VERSION "10.9.1"

NS_ :

BS_:

BU_: ADAS_Info AMP CPD DUMMY_DEBUG DUMMY_ECU EASC HUD MHU XGW_Info

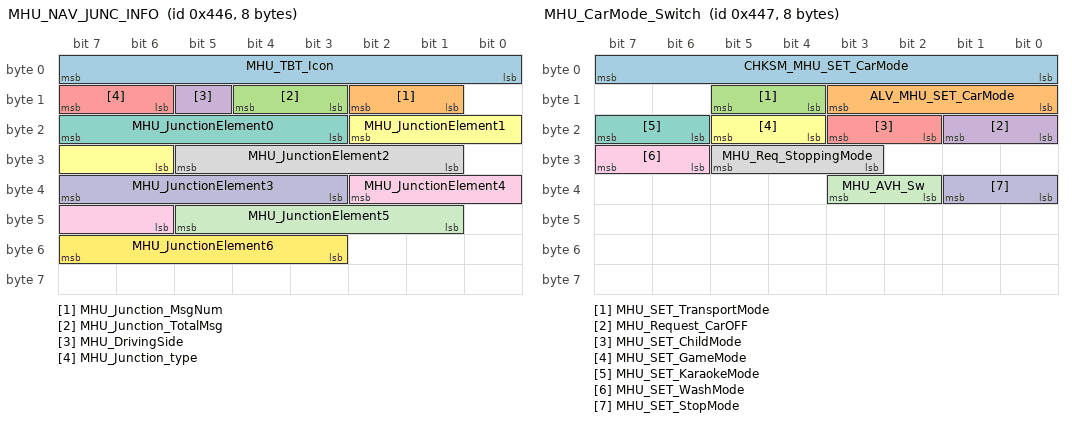
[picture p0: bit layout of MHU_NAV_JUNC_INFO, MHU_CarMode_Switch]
BO_ 1094 MHU_NAV_JUNC_INFO: 8 MHU
  SG_ MHU_TBT_Icon : 7|8@0+ (1,0) [0|255] "-" HUD
  SG_ MHU_Junction_MsgNum : 10|2@0+ (1,0) [0|3] "-" HUD
  SG_ MHU_Junction_TotalMsg : 12|2@0+ (1,0) [0|3] "-" HUD
  SG_ MHU_DrivingSide : 13|1@0+ (1,0) [0|1] "-" HUD
  SG_ MHU_Junction_type : 15|2@0+ (1,0) [0|3] "-" HUD
  SG_ MHU_JunctionElement1 : 18|5@0+ (1,0) [0|31] "-" HUD
  SG_ MHU_JunctionElement0 : 23|5@0+ (1,0) [0|31] "-" HUD
  SG_ MHU_JunctionElement2 : 29|5@0+ (1,0) [0|31] "-" HUD
  SG_ MHU_JunctionElement4 : 34|5@0+ (1,0) [0|31] "-" HUD
  SG_ MHU_JunctionElement3 : 39|5@0+ (1,0) [0|31] "-" HUD
  SG_ MHU_JunctionElement5 : 45|5@0+ (1,0) [0|31] "-" HUD
  SG_ MHU_JunctionElement6 : 55|5@0+ (1,0) [0|31] "-" HUD

BO_ 1095 MHU_CarMode_Switch: 8 MHU
  SG_ CHKSM_MHU_SET_CarMode : 7|8@0+ (1,0) [0|255] "" XGW_Info
  SG_ ALV_MHU_SET_CarMode : 11|4@0+ (1,0) [0|14] "" XGW_Info
  SG_ MHU_SET_TransportMode : 13|2@0+ (1,0) [0|3] "" XGW_Info
  SG_ MHU_Request_CarOFF : 17|2@0+ (1,0) [0|3] "-" XGW_Info
  SG_ MHU_SET_ChildMode : 19|2@0+ (1,0) [0|3] "" XGW_Info
  SG_ MHU_SET_GameMode : 21|2@0+ (1,0) [0|3] "" XGW_Info
  SG_ MHU_SET_KaraokeMode : 23|2@0+ (1,0) [0|3] "" XGW_Info
  SG_ MHU_Req_StoppingMode : 29|3@0+ (1,0) [0|7] "" XGW_Info
  SG_ MHU_SET_WashMode : 31|2@0+ (1,0) [0|3] "" XGW_Info
  SG_ MHU_SET_StopMode : 33|2@0+ (1,0) [0|3] "" XGW_Info
  SG_ MHU_AVH_Sw : 35|2@0+ (1,0) [0|3] "" XGW_Info

BO_ 1096 EDS_Error_FR_B: 8 XGW_Info
  SG_ CHKSM_EDS_Error_FR_B : 7|8@0+ (1,0) [0|255] "" MHU
  SG_ ALV_EDS_Error_FR_B : 11|4@0+ (1,0) [0|14] "" MHU
  SG_ EDS_iDcLnkOvCLimFail_FWD : 16|1@0+ (1,0) [0|1] "" MHU
  SG_ EDS_MotBlockedFault_FWD : 17|1@0+ (1,0) [0|1] "" MHU
  SG_ EDS_RSLErr_FWD : 18|1@0+ (1,0) [0|1] "" MHU
  SG_ EDS_MotTrqLimFault_FWD : 19|1@0+ (1,0) [0|1] "" MHU
  SG_ EDS_VCUChksumFault_FWD : 20|1@0+ (1,0) [0|1] "" MHU
  SG_ EDS_IGBTFault_FWD : 22|1@0+ (1,0) [0|1] "" MHU
  SG_ EDS_CANBusoffFault_FWD : 23|1@0+ (1,0) [0|1] "" MHU
  SG_ EDS_TDrvBoardOvHiWarn_FWD : 24|1@0+ (1,0) [0|1] "" MHU
  SG_ EDS_TIGBTOvHiFault_FWD : 25|1@0+ (1,0) [0|1] "" MHU
  SG_ EDS_TIGBTOvHiWarn_FWD : 26|1@0+ (1,0) [0|1] "" MHU
  SG_ EDS_IOHWABSampFail_FWD : 27|1@0+ (1,0) [0|1] "" MHU
  SG_ EDS_EDSOpenFault_FWD : 28|1@0+ (1,0) [0|1] "" MHU
  SG_ EDS_MotorOpenFault_FWD : 29|1@0+ (1,0) [0|1] "" MHU
  SG_ EDS_EparkSampFail_FWD : 30|1@0+ (1,0) [0|1] "" MHU
  SG_ EDS_EmacBlkdWarn_FWD : 31|1@0+ (1,0) [0|1] "" MHU
  SG_ EDS_VerMatchFailureErr_FWD : 32|1@0+ (1,0) [0|1] "" MHU
  SG_ EDS_DiashCirNoPsblErr_FWD : 33|1@0+ (1,0) [0|1] "" MHU
  SG_ EDS_OperOutdRngErr_FWD : 34|1@0+ (1,0) [0|1] "" MHU
  SG_ EDS_PhaseLossFaultErr_FWD : 35|1@0+ (1,0) [0|1] "" MHU
  SG_ EDS_CPLDFault_FWD : 36|1@0+ (1,0) [0|1] "" MHU
  SG_ EDS_CPLDFaultBaseSpd_FWD : 37|1@0+ (1,0) [0|1] "" MHU
  SG_ EDS_IOHWABNen33Fail_FWD : 38|1@0+ (1,0) [0|1] "" MHU
  SG_ EDS_HvMcuSlightFault_FWD : 39|1@0+ (1,0) [0|1] "" MHU
  SG_ EDS_HvMcuSevFault_FWD : 40|1@0+ (1,0) [0|1] "" MHU
  SG_ EDS_EDSPhaSampHWFault_FWD : 41|1@0+ (1,0) [0|1] "" MHU
  SG_ EDS_IsOvHiErr_FWD : 42|1@0+ (1,0) [0|1] "" MHU
  SG_ EDS_CanRollingCounterErr_FWD : 43|1@0+ (1,0) [0|1] "" MHU
  SG_ EDS_CanTimeoutErr_FWD : 44|1@0+ (1,0) [0|1] "" MHU
  SG_ EDS_CrashFault_FWD : 45|1@0+ (1,0) [0|1] "" MHU
  SG_ EDS_PCFSlightFault_FWD : 46|1@0+ (1,0) [0|1] "" MHU
  SG_ EDS_PCFSerFault_FWD : 47|1@0+ (1,0) [0|1] "" MHU
  SG_ SECCAN_EDS_Error_FR_B : 63|8@0+ (1,0) [0|255] "" MHU

BO_ 1097 EDS_Error_RR_B: 8 XGW_Info
  SG_ CHKSM_EDS_Error_RR_B : 7|8@0+ (1,0) [0|255] "" MHU
  SG_ ALV_EDS_Error_RR_B : 11|4@0+ (1,0) [0|14] "" MHU
  SG_ EDS_iDcLnkOvCLimFail_RWD : 16|1@0+ (1,0) [0|1] "" MHU
  SG_ EDS_MotBlockedFault_RWD : 17|1@0+ (1,0) [0|1] "" MHU
  SG_ EDS_RSLErr_RWD : 18|1@0+ (1,0) [0|1] "" MHU
  SG_ EDS_MotTrqLimFault_RWD : 19|1@0+ (1,0) [0|1] "" MHU
  SG_ EDS_VCUChksumFault_RWD : 20|1@0+ (1,0) [0|1] "" MHU
  SG_ EDS_IGBTFault_RWD : 22|1@0+ (1,0) [0|1] "" MHU
  SG_ EDS_CANBusoffFault_RWD : 23|1@0+ (1,0) [0|1] "" MHU
  SG_ EDS_TDrvBoardOvHiWarn_RWD : 24|1@0+ (1,0) [0|1] "" MHU
  SG_ EDS_TIGBTOvHiFault_RWD : 25|1@0+ (1,0) [0|1] "" MHU
  SG_ EDS_TIGBTOvHiWarn_RWD : 26|1@0+ (1,0) [0|1] "" MHU
  SG_ EDS_IOHWABSampFail_RWD : 27|1@0+ (1,0) [0|1] "" MHU
  SG_ EDS_EDSOpenFault_RWD : 28|1@0+ (1,0) [0|1] "" MHU
  SG_ EDS_MotorOpenFault_RWD : 29|1@0+ (1,0) [0|1] "" MHU
  SG_ EDS_EparkSampFail_RWD : 30|1@0+ (1,0) [0|1] "" MHU
  SG_ EDS_EmacBlkdWarn_RWD : 31|1@0+ (1,0) [0|1] "" MHU
  SG_ EDS_VerMatchFailureErr_RWD : 32|1@0+ (1,0) [0|1] "" MHU
  SG_ EDS_DiashCirNoPsblErr_RWD : 33|1@0+ (1,0) [0|1] "" MHU
  SG_ EDS_OperOutdRngErr_RWD : 34|1@0+ (1,0) [0|1] "" MHU
  SG_ EDS_PhaseLossFaultErr_RWD : 35|1@0+ (1,0) [0|1] "" MHU
  SG_ EDS_CPLDFault_RWD : 36|1@0+ (1,0) [0|1] "" MHU
  SG_ EDS_CPLDFaultBaseSpd_RWD : 37|1@0+ (1,0) [0|1] "" MHU
  SG_ EDS_IOHWABNen33Fail_RWD : 38|1@0+ (1,0) [0|1] "" MHU
  SG_ EDS_HvMcuSlightFault_RWD : 39|1@0+ (1,0) [0|1] "" MHU
  SG_ EDS_HvMcuSevFault_RWD : 40|1@0+ (1,0) [0|1] "" MHU
  SG_ EDS_EDSPhaSampHWFault_RWD : 41|1@0+ (1,0) [0|1] "" MHU
  SG_ EDS_IsOvHiErr_RWD : 42|1@0+ (1,0) [0|1] "" MHU
  SG_ EDS_CanRollingCounterErr_RWD : 43|1@0+ (1,0) [0|1] "" MHU
  SG_ EDS_CanTimeoutErr_RWD : 44|1@0+ (1,0) [0|1] "" MHU
  SG_ EDS_CrashFault_RWD : 45|1@0+ (1,0) [0|1] "" MHU
  SG_ EDS_PCFSlightFault_RWD : 46|1@0+ (1,0) [0|1] "" MHU
  SG_ EDS_PCFSerFault_RWD : 47|1@0+ (1,0) [0|1] "" MHU
  SG_ SECCAN_EDS_Error_RR_B : 63|8@0+ (1,0) [0|255] "" MHU

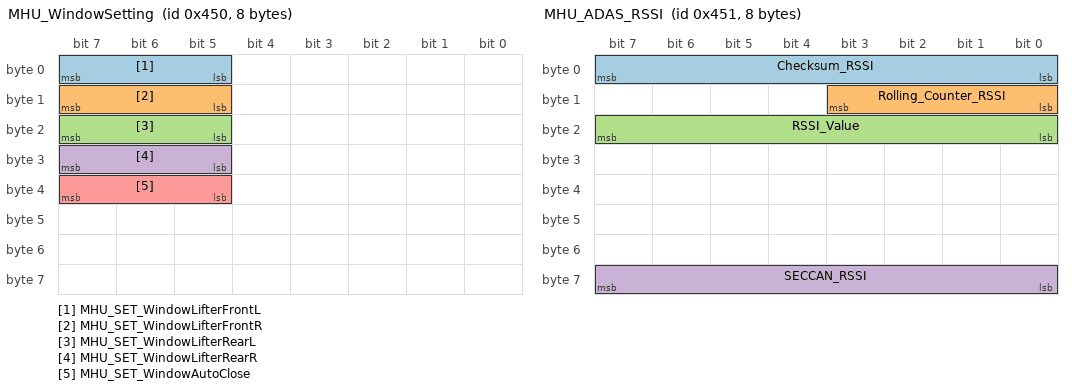
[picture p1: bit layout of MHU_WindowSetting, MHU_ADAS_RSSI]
BO_ 1104 MHU_WindowSetting: 8 MHU
  SG_ MHU_SET_WindowLifterFrontL : 7|3@0+ (1,0) [0|7] "" XGW_Info
  SG_ MHU_SET_WindowLifterFrontR : 15|3@0+ (1,0) [0|7] "" XGW_Info
  SG_ MHU_SET_WindowLifterRearL : 23|3@0+ (1,0) [0|7] "" XGW_Info
  SG_ MHU_SET_WindowLifterRearR : 31|3@0+ (1,0) [0|7] "" XGW_Info
  SG_ MHU_SET_WindowAutoClose : 39|3@0+ (1,0) [0|3] "" XGW_Info

BO_ 1105 MHU_ADAS_RSSI: 8 MHU
  SG_ Checksum_RSSI : 7|8@0+ (1,0) [0|255] "" ADAS_Info
  SG_ Rolling_Counter_RSSI : 11|4@0+ (1,0) [0|14] "" ADAS_Info
  SG_ RSSI_Value : 23|8@0+ (1,0) [0|255] "" ADAS_Info
  SG_ SECCAN_RSSI : 63|8@0+ (1,0) [0|255] "" ADAS_Info

BO_ 1106 MHU_AMP_Ann1_ModeSET: 8 MHU
  SG_ MHU_SET_ANN1_MODE : 7|2@0+ (1,0) [0|3] "" AMP

BO_ 1107 MHU_AMP_Ann1_PromptsSET: 8 MHU
  SG_ MHU_SET_ANN1_PROMPTS_SPEAKER : 7|3@0+ (1,0) [0|6] "" AMP

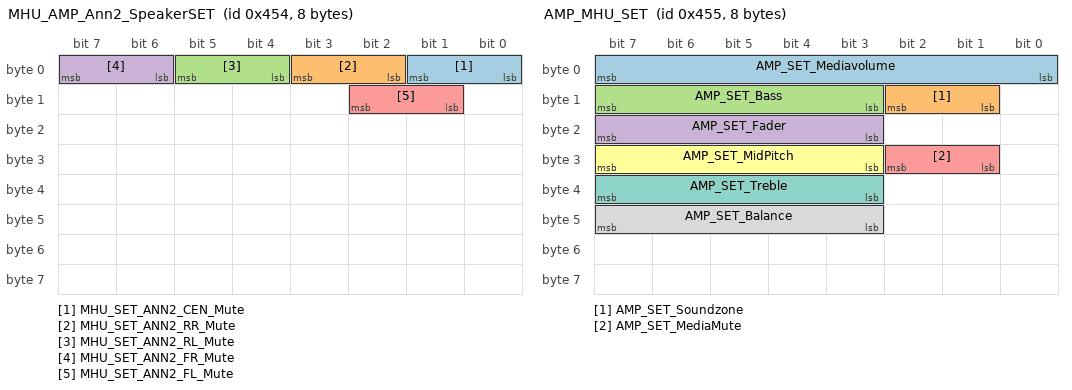
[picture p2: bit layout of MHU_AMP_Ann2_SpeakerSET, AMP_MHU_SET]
BO_ 1108 MHU_AMP_Ann2_SpeakerSET: 8 MHU
  SG_ MHU_SET_ANN2_CEN_Mute : 1|2@0+ (1,0) [0|2] "" AMP
  SG_ MHU_SET_ANN2_RR_Mute : 3|2@0+ (1,0) [0|2] "" AMP
  SG_ MHU_SET_ANN2_RL_Mute : 5|2@0+ (1,0) [0|2] "" AMP
  SG_ MHU_SET_ANN2_FR_Mute : 7|2@0+ (1,0) [0|2] "" AMP
  SG_ MHU_SET_ANN2_FL_Mute : 10|2@0+ (1,0) [0|2] "" AMP

BO_ 1109 AMP_MHU_SET: 8 AMP
  SG_ AMP_SET_Mediavolume : 7|8@0+ (1,0) [0|40] "-" MHU
  SG_ AMP_SET_Soundzone : 10|2@0+ (1,0) [0|3] "-" MHU
  SG_ AMP_SET_Bass : 15|5@0+ (1,-6) [-6|6] "-" MHU
  SG_ AMP_SET_Fader : 23|5@0+ (1,-10) [-10|10] "-" MHU
  SG_ AMP_SET_MediaMute : 26|2@0+ (1,0) [0|3] "-" MHU
  SG_ AMP_SET_MidPitch : 31|5@0+ (1,-6) [-6|6] "-" MHU
  SG_ AMP_SET_Treble : 39|5@0+ (1,-6) [-6|6] "-" MHU
  SG_ AMP_SET_Balance : 47|5@0+ (1,-10) [-10|10] "-" MHU

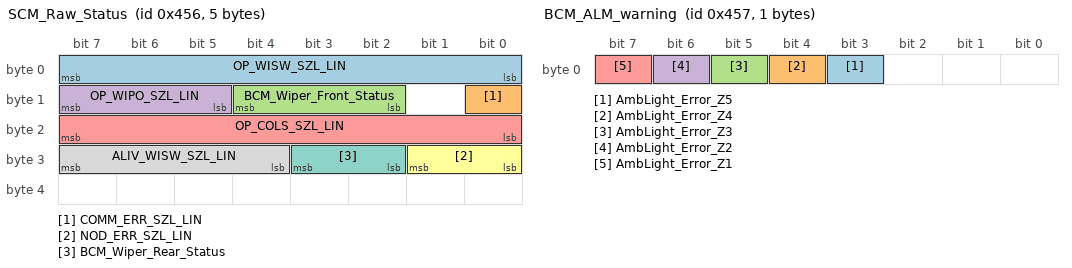
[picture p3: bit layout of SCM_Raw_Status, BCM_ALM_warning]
BO_ 1110 SCM_Raw_Status: 5 XGW_Info
  SG_ OP_WISW_SZL_LIN : 7|8@0+ (1,0) [0|255] "" HUD,MHU
  SG_ COMM_ERR_SZL_LIN : 8|1@0+ (1,0) [0|1] "" HUD,MHU
  SG_ BCM_Wiper_Front_Status : 12|3@0+ (1,0) [0|7] "" HUD,MHU
  SG_ OP_WIPO_SZL_LIN : 15|3@0+ (1,0) [0|7] "-" HUD,MHU
  SG_ OP_COLS_SZL_LIN : 23|8@0+ (1,0) [0|255] "-" HUD,MHU
  SG_ NOD_ERR_SZL_LIN : 25|2@0+ (1,0) [0|3] "" HUD,MHU
  SG_ BCM_Wiper_Rear_Status : 27|2@0+ (1,0) [0|3] "" MHU
  SG_ ALIV_WISW_SZL_LIN : 31|4@0+ (1,0) [0|14] "" HUD,MHU

BO_ 1111 BCM_ALM_warning: 1 XGW_Info
  SG_ AmbLight_Error_Z5 : 3|1@0+ (1,0) [0|1] "-" MHU
  SG_ AmbLight_Error_Z4 : 4|1@0+ (1,0) [0|1] "" MHU
  SG_ AmbLight_Error_Z3 : 5|1@0+ (1,0) [0|1] "-" MHU
  SG_ AmbLight_Error_Z2 : 6|1@0+ (1,0) [0|1] "" MHU
  SG_ AmbLight_Error_Z1 : 7|1@0+ (1,0) [0|1] "" MHU

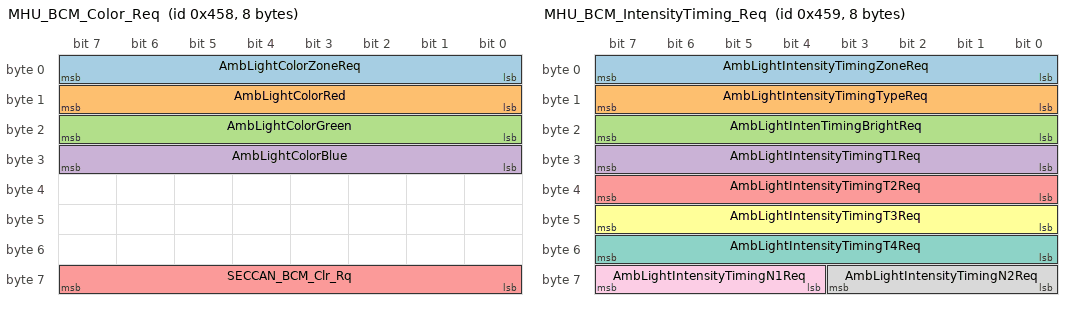
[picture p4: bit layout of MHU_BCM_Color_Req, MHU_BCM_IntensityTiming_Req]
BO_ 1112 MHU_BCM_Color_Req: 8 MHU
  SG_ AmbLightColorZoneReq : 7|8@0+ (1,0) [0|31] "-" XGW_Info
  SG_ AmbLightColorRed : 15|8@0+ (1,0) [0|255] "" XGW_Info
  SG_ AmbLightColorGreen : 23|8@0+ (1,0) [0|255] "-" XGW_Info
  SG_ AmbLightColorBlue : 31|8@0+ (1,0) [0|255] "-" XGW_Info
  SG_ SECCAN_BCM_Clr_Rq : 63|8@0+ (1,0) [0|255] "" XGW_Info

BO_ 1113 MHU_BCM_IntensityTiming_Req: 8 MHU
  SG_ AmbLightIntensityTimingZoneReq : 7|8@0+ (1,0) [0|31] "" XGW_Info
  SG_ AmbLightIntensityTimingTypeReq : 15|8@0+ (1,0) [0|5] "" XGW_Info
  SG_ AmbLightIntenTimingBrightReq : 23|8@0+ (1,0) [0|100] "" XGW_Info
  SG_ AmbLightIntensityTimingT1Req : 31|8@0+ (0.1,0) [0|25.5] "s" XGW_Info
  SG_ AmbLightIntensityTimingT2Req : 39|8@0+ (0.1,0) [0|25.5] "s" XGW_Info
  SG_ AmbLightIntensityTimingT3Req : 47|8@0+ (0.1,0) [0|25.5] "s" XGW_Info
  SG_ AmbLightIntensityTimingT4Req : 55|8@0+ (0.1,0) [0|25.5] "s" XGW_Info
  SG_ AmbLightIntensityTimingN2Req : 59|4@0+ (1,0) [0|15] "-" XGW_Info
  SG_ AmbLightIntensityTimingN1Req : 63|4@0+ (1,0) [0|15] "" XGW_Info

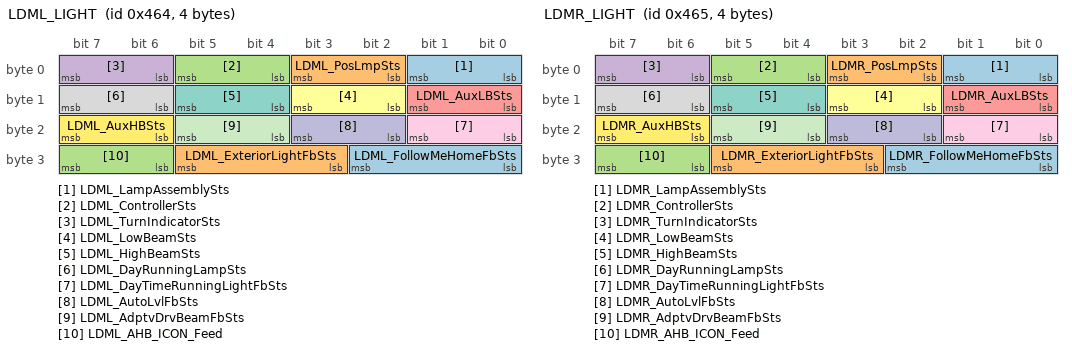
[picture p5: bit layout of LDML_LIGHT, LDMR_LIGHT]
BO_ 1124 LDML_LIGHT: 4 XGW_Info
  SG_ LDML_LampAssemblySts : 1|2@0+ (1,0) [0|3] "-" HUD,MHU
  SG_ LDML_PosLmpSts : 3|2@0+ (1,0) [0|3] "" HUD,MHU
  SG_ LDML_ControllerSts : 5|2@0+ (1,0) [0|3] "" HUD,MHU
  SG_ LDML_TurnIndicatorSts : 7|2@0+ (1,0) [0|3] "" HUD,MHU
  SG_ LDML_AuxLBSts : 9|2@0+ (1,0) [0|3] "-" HUD,MHU
  SG_ LDML_LowBeamSts : 11|2@0+ (1,0) [0|3] "-" HUD,MHU
  SG_ LDML_HighBeamSts : 13|2@0+ (1,0) [0|3] "" HUD,MHU
  SG_ LDML_DayRunningLampSts : 15|2@0+ (1,0) [0|3] "" HUD,MHU
  SG_ LDML_DayTimeRunningLightFbSts : 17|2@0+ (1,0) [0|3] "" HUD,MHU
  SG_ LDML_AutoLvlFbSts : 19|2@0+ (1,0) [0|3] "" HUD,MHU
  SG_ LDML_AdptvDrvBeamFbSts : 21|2@0+ (1,0) [0|3] "-" HUD,MHU
  SG_ LDML_AuxHBSts : 23|2@0+ (1,0) [0|3] "-" HUD,MHU
  SG_ LDML_FollowMeHomeFbSts : 26|3@0+ (1,0) [0|5] "-" HUD,MHU
  SG_ LDML_ExteriorLightFbSts : 29|3@0+ (1,0) [0|4] "-" HUD,MHU
  SG_ LDML_AHB_ICON_Feed : 31|2@0+ (1,0) [0|3] "" HUD,MHU

BO_ 1125 LDMR_LIGHT: 4 XGW_Info
  SG_ LDMR_LampAssemblySts : 1|2@0+ (1,0) [0|3] "" HUD,MHU
  SG_ LDMR_PosLmpSts : 3|2@0+ (1,0) [0|3] "-" HUD,MHU
  SG_ LDMR_ControllerSts : 5|2@0+ (1,0) [0|3] "" HUD,MHU
  SG_ LDMR_TurnIndicatorSts : 7|2@0+ (1,0) [0|3] "-" HUD,MHU
  SG_ LDMR_AuxLBSts : 9|2@0+ (1,0) [0|3] "-" HUD,MHU
  SG_ LDMR_LowBeamSts : 11|2@0+ (1,0) [0|3] "-" HUD,MHU
  SG_ LDMR_HighBeamSts : 13|2@0+ (1,0) [0|3] "" HUD,MHU
  SG_ LDMR_DayRunningLampSts : 15|2@0+ (1,0) [0|3] "" HUD,MHU
  SG_ LDMR_DayTimeRunningLightFbSts : 17|2@0+ (1,0) [0|3] "-" HUD,MHU
  SG_ LDMR_AutoLvlFbSts : 19|2@0+ (1,0) [0|3] "-" HUD,MHU
  SG_ LDMR_AdptvDrvBeamFbSts : 21|2@0+ (1,0) [0|3] "" HUD,MHU
  SG_ LDMR_AuxHBSts : 23|2@0+ (1,0) [0|3] "-" HUD,MHU
  SG_ LDMR_FollowMeHomeFbSts : 26|3@0+ (1,0) [0|5] "" HUD,MHU
  SG_ LDMR_ExteriorLightFbSts : 29|3@0+ (1,0) [0|4] "-" HUD,MHU
  SG_ LDMR_AHB_ICON_Feed : 31|2@0+ (1,0) [0|3] "" HUD,MHU

BO_ 1136 AMP_MHU_Ann1_ModeSET: 8 AMP
  SG_ AMP_SET_ANN1_MODE : 15|2@0+ (1,0) [0|3] "" MHU

BO_ 1137 AMP_MHU_Ann1_PromptsSET: 8 AMP
  SG_ AMP_SET_ANN1_PROMPTS_SPEAKER : 13|3@0+ (1,0) [0|6] "" MHU

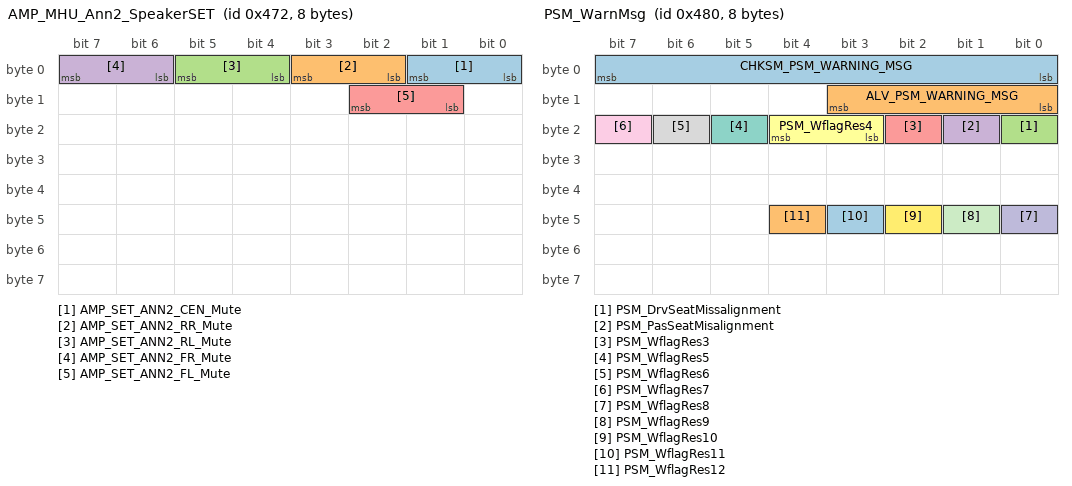
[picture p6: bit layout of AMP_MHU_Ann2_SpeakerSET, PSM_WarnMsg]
BO_ 1138 AMP_MHU_Ann2_SpeakerSET: 8 AMP
  SG_ AMP_SET_ANN2_CEN_Mute : 1|2@0+ (1,0) [0|3] "" MHU
  SG_ AMP_SET_ANN2_RR_Mute : 3|2@0+ (1,0) [0|3] "" MHU
  SG_ AMP_SET_ANN2_RL_Mute : 5|2@0+ (1,0) [0|3] "" MHU
  SG_ AMP_SET_ANN2_FR_Mute : 7|2@0+ (1,0) [0|3] "" MHU
  SG_ AMP_SET_ANN2_FL_Mute : 10|2@0+ (1,0) [0|3] "" MHU

BO_ 1152 PSM_WarnMsg: 8 XGW_Info
  SG_ CHKSM_PSM_WARNING_MSG : 7|8@0+ (1,0) [0|255] "" MHU
  SG_ ALV_PSM_WARNING_MSG : 11|4@0+ (1,0) [0|14] "" MHU
  SG_ PSM_DrvSeatMissalignment : 16|1@0+ (1,0) [0|1] "" MHU
  SG_ PSM_PasSeatMisalignment : 17|1@0+ (1,0) [0|1] "Bit" MHU
  SG_ PSM_WflagRes3 : 18|1@0+ (1,0) [0|1] "Bit" MHU
  SG_ PSM_WflagRes4 : 20|2@0+ (1,0) [0|3] "Bit" MHU
  SG_ PSM_WflagRes5 : 21|1@0+ (1,0) [0|1] "-" MHU
  SG_ PSM_WflagRes6 : 22|1@0+ (1,0) [0|1] "-" MHU
  SG_ PSM_WflagRes7 : 23|1@0+ (1,0) [0|1] "-" MHU
  SG_ PSM_WflagRes8 : 40|1@0+ (1,0) [0|1] "" MHU
  SG_ PSM_WflagRes9 : 41|1@0+ (1,0) [0|1] "" MHU
  SG_ PSM_WflagRes10 : 42|1@0+ (1,0) [0|1] "-" MHU
  SG_ PSM_WflagRes11 : 43|1@0+ (1,0) [0|1] "-" MHU
  SG_ PSM_WflagRes12 : 44|1@0+ (1,0) [0|1] "-" MHU

BO_ 1153 BCM_WarnMsg: 8 XGW_Info
 SG_ CHSKM_BCM_WarnMsg : 7|8@0+ (1,0) [0|255] "" MHU
 SG_ ALV_BCM_WarnMsg : 11|4@0+ (1,0) [0|14] "" MHU
 SG_ BCM_NoValidKey_1 : 12|1@0+ (1,0) [0|1] "" MHU
 SG_ BCM_SSB_defect : 13|1@0+ (1,0) [0|1] "" MHU
 SG_ BCM_WrongGearPosToStart : 14|1@0+ (1,0) [0|1] "" MHU
 SG_ BCM_NoValidKey_2 : 15|1@0+ (1,0) [0|1] "" MHU
 SG_ BCM_PressBrakeToStart : 16|1@0+ (1,0) [0|1] "" MHU
 SG_ BCM_TurnOffPosLightRemindr : 17|1@0+ (1,0) [0|1] "" MHU
 SG_ BCM_KeyFob_LowBattery : 18|1@0+ (1,0) [0|1] "" MHU
 SG_ BCM_StopLightDefect : 19|1@0+ (1,0) [0|1] "" MHU
 SG_ BCM_LowBeamDefect : 20|1@0+ (1,0) [0|1] "" MHU
 SG_ BCM_HighBeamDefect : 21|1@0+ (1,0) [0|1] "" MHU
 SG_ BCM_PositionLightDefect : 22|1@0+ (1,0) [0|1] "" MHU
 SG_ BCM_CHMLS_Defect : 23|1@0+ (1,0) [0|1] "" MHU
 SG_ BCM_LicencePlateLight_Defect : 24|1@0+ (1,0) [0|1] "" MHU
 SG_ BCM_FrontFog_Defect : 25|1@0+ (1,0) [0|1] "" MHU
 SG_ BCM_RearFog_Defect : 26|1@0+ (1,0) [0|1] "" MHU
 SG_ BCM_ReverseLightDefect : 27|1@0+ (1,0) [0|1] "" MHU
 SG_ BCM_RLS_Malfunction : 28|1@0+ (1,0) [0|1] "" MHU
 SG_ BCM_12VBattery_LowLevel : 29|1@0+ (1,0) [0|1] "" MHU
 SG_ BCM_ForgetKeyFOBInCar : 30|1@0+ (1,0) [0|1] "" MHU
 SG_ BCM_12VBattery_Discharging : 31|1@0+ (1,0) [0|1] "" MHU
 SG_ BCM_TurnIndicatorDefect : 32|1@0+ (1,0) [0|1] "" MHU
 SG_ BCM_dTPMS_Malfunc : 33|1@0+ (1,0) [0|1] "" MHU
 SG_ BCM_dTPMS_Malfunc_LostSensor : 34|1@0+ (1,0) [0|1] "" MHU
 SG_ BCM_dTPMS_LowPressure : 35|1@0+ (1,0) [0|1] "" MHU
 SG_ BCM_dTPMS_RapidLeak : 36|1@0+ (1,0) [0|1] "" MHU
 SG_ BCM_dTPMS_HighTemperature : 37|1@0+ (1,0) [0|1] "" MHU
 SG_ BCM_dTPMS_HighPressure : 38|1@0+ (1,0) [0|1] "" MHU
 SG_ BCM_dTPMS_LowBattery : 39|1@0+ (1,0) [0|1] "" MHU
 SG_ BCM_Keyfob_Leftcar : 40|1@0+ (1,0) [0|1] "" MHU
 SG_ BCM_IDB_Brakelight_Malfunction : 41|1@0+ (1,0) [0|1] "" MHU
 SG_ BCM_VCU_Brakelight_Malfunction : 42|1@0+ (1,0) [0|1] "" MHU
 SG_ BCM_ADAS_Turnlight_Malfunction : 43|1@0+ (1,0) [0|1] "" MHU
 SG_ BCM_ADAS_Highbeam_Malfunction : 44|1@0+ (1,0) [0|1] "" MHU
 SG_ BCM_ADAS_LowBeam_Malfunction : 45|1@0+ (1,0) [0|1] "" MHU
 SG_ BCM_MHU_Malfunction : 46|1@0+ (1,0) [0|1] "" MHU
 SG_ BCM_BCM_Malfunction : 47|1@0+ (1,0) [0|1] "" MHU
 SG_ BCM_SCM_Malfunction : 48|1@0+ (1,0) [0|1] "" MHU
 SG_ BCM_CrashSignalDefect : 49|1@0+ (1,0) [0|1] "" MHU
 SG_ BCM_FrontWiperDefect : 51|1@0+ (1,0) [0|1] "" MHU
 SG_ BCM_Rear_RightDoorLockDefect : 52|1@0+ (1,0) [0|1] "" MHU
 SG_ BCM_RearLeftDoorLockDefect : 53|1@0+ (1,0) [0|1] "" MHU
 SG_ BCM_Front_RightDoorLockDefect : 54|1@0+ (1,0) [0|1] "" MHU
 SG_ BCM_FrontLeftDoorLockDefect : 55|1@0+ (1,0) [0|1] "" MHU
 SG_ BCM_LDML_Malfunction : 56|1@0+ (1,0) [0|1] "" MHU
 SG_ BCM_LDMR_Malfunction : 57|1@0+ (1,0) [0|1] "" MHU
 SG_ BCM_RLBL_Malfunction : 58|1@0+ (1,0) [0|1] "" MHU
 SG_ BCM_RLBR_Malfunction : 59|1@0+ (1,0) [0|1] "" MHU
 SG_ BCM_RLT_Malfunction : 60|1@0+ (1,0) [0|1] "" MHU
 SG_ BCM_BCM_POWER_Malfunction : 61|1@0+ (1,0) [0|1] "" MHU
 SG_ BCM_IDB_AutoHazardBlinking_Malf : 62|1@0+ (1,0) [0|1] "" MHU

BO_ 1154 XGW_WarnMsg: 8 XGW_Info
  SG_ CHSKM_XGW_WarnMsg : 7|8@0+ (1,0) [0|255] "" MHU
  SG_ ALV_XGW_WarnMsg : 11|4@0+ (1,0) [0|14] "" MHU
  SG_ XGW_AutoHLLevelingFault : 12|1@0+ (1,0) [0|1] "-" MHU
  SG_ XGW_WasherFluidLvlSw : 13|1@0+ (1,0) [0|1] "-" MHU
  SG_ XGW_Warning_Flag_3 : 14|1@0+ (1,0) [0|1] "-" MHU
  SG_ XGW_Warning_Flag_4 : 15|1@0+ (1,0) [0|1] "-" MHU
  SG_ XGW_Warning_Flag_5 : 16|1@0+ (1,0) [0|1] "-" MHU
  SG_ XGW_Warning_Flag_6 : 17|1@0+ (1,0) [0|1] "-" MHU
  SG_ XGW_Warning_Flag_7 : 18|1@0+ (1,0) [0|1] "-" MHU
  SG_ XGW_Warning_Flag_8 : 19|1@0+ (1,0) [0|1] "-" MHU
  SG_ XGW_Warning_Flag_9 : 20|1@0+ (1,0) [0|1] "-" MHU
  SG_ XGW_Warning_Flag_10 : 21|1@0+ (1,0) [0|1] "-" MHU
  SG_ XGW_Warning_Flag_11 : 22|1@0+ (1,0) [0|1] "-" MHU
  SG_ XGW_Warning_Flag_12 : 23|1@0+ (1,0) [0|1] "-" MHU
  SG_ XGW_Reserved_signal1 : 31|8@0+ (1,0) [0|255] "-" MHU
  SG_ XGW_Reserved_signal2 : 39|8@0+ (1,0) [0|255] "-" MHU
  SG_ XGW_Reserved_signal3 : 47|8@0+ (1,0) [0|255] "-" MHU
  SG_ XGW_Reserved_signal4 : 55|8@0+ (1,0) [0|255] "-" MHU
  SG_ XGW_Reserved_signal5 : 63|8@0+ (1,0) [0|255] "-" MHU

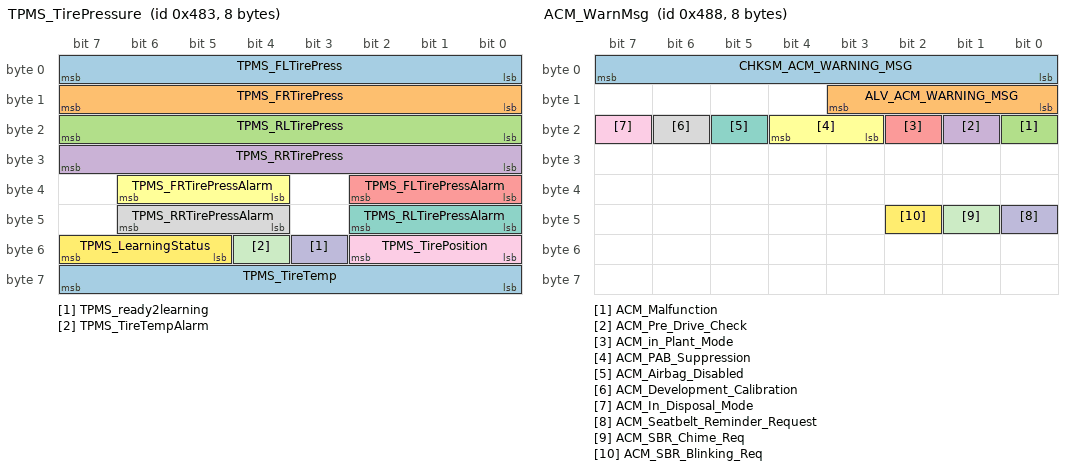
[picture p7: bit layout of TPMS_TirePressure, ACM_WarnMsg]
BO_ 1155 TPMS_TirePressure: 8 XGW_Info
  SG_ TPMS_FLTirePress : 7|8@0+ (1.373,0) [0|350] "kPa" MHU
  SG_ TPMS_FRTirePress : 15|8@0+ (1.373,0) [0|350] "kPa" MHU
  SG_ TPMS_RLTirePress : 23|8@0+ (1.373,0) [0|350] "kPa" MHU
  SG_ TPMS_RRTirePress : 31|8@0+ (1.373,0) [0|350] "kPa" MHU
  SG_ TPMS_FLTirePressAlarm : 34|3@0+ (1,0) [0|7] "" MHU
  SG_ TPMS_FRTirePressAlarm : 38|3@0+ (1,0) [0|7] "-" MHU
  SG_ TPMS_RLTirePressAlarm : 42|3@0+ (1,0) [0|7] "" MHU
  SG_ TPMS_RRTirePressAlarm : 46|3@0+ (1,0) [0|7] "" MHU
  SG_ TPMS_TirePosition : 50|3@0+ (1,0) [0|7] "-" MHU
  SG_ TPMS_ready2learning : 51|1@0+ (1,0) [0|1] "-" MHU
  SG_ TPMS_TireTempAlarm : 52|1@0+ (1,0) [0|1] "-" MHU
  SG_ TPMS_LearningStatus : 55|3@0+ (1,0) [0|7] "-" MHU
  SG_ TPMS_TireTemp : 63|8@0+ (1,-40) [-40|215] "Degree C" MHU

BO_ 1156 APA_FEEDBACK_MHU: 8 ADAS_Info
  SG_ CHKSM_APA_FEEDBACK_MHU : 7|8@0+ (1,0) [0|255] "" MHU
  SG_ ALV_APA_FEEDBACK_MHU : 11|4@0+ (1,0) [0|14] "" MHU
  SG_ APA_ReqInfoDispTxt3 : 19|5@0+ (1,0) [0|31] "-" MHU
  SG_ APA_ParkOutDircnDisReq : 20|1@0+ (1,0) [0|1] "-" MHU
  SG_ APA_ParkOutModeDisReq : 21|1@0+ (1,0) [0|1] "-" MHU
  SG_ APA_MHU_DisplaystartbuttonReq : 23|2@0+ (1,0) [0|3] "-" MHU
  SG_ APA_ReqInfoDispTxt4 : 27|4@0+ (1,0) [0|15] "-" MHU
  SG_ APA_ReqInfoDispTxt2 : 30|3@0+ (1,0) [0|7] "-" MHU
  SG_ APA_ReqInfoDispTxt1 : 34|3@0+ (1,0) [0|7] "-" MHU
  SG_ APA_MHU_Displayparkingtype : 35|1@0+ (1,0) [0|1] "-" MHU
  SG_ APA_ShowAPAFdbck : 37|2@0+ (1,0) [0|3] "-" MHU
  SG_ APA_FuncModeFdbck : 39|2@0+ (1,0) [0|3] "-" MHU
  SG_ APA_MHU_DisplayrecoverbuttonReq : 44|1@0+ (1,0) [0|1] "-" MHU
  SG_ APA_SysSoundIndication : 47|3@0+ (1,0) [0|7] "-" MHU
  SG_ APA_RecommendSlotID : 51|8@0+ (1,0) [0|255] "-" MHU
  SG_ APA_Currentfunction : 54|3@0+ (1,0) [0|7] "-" MHU
  SG_ APA_MHU_Status : 59|3@0+ (1,0) [0|7] "-" MHU

BO_ 1160 ACM_WarnMsg: 8 XGW_Info
  SG_ CHKSM_ACM_WARNING_MSG : 7|8@0+ (1,0) [0|255] "" MHU
  SG_ ALV_ACM_WARNING_MSG : 11|4@0+ (1,0) [0|14] "" MHU
  SG_ ACM_Malfunction : 16|1@0+ (1,0) [0|1] "" MHU
  SG_ ACM_Pre_Drive_Check : 17|1@0+ (1,0) [0|1] "Bit" MHU
  SG_ ACM_in_Plant_Mode : 18|1@0+ (1,0) [0|1] "Bit" MHU
  SG_ ACM_PAB_Suppression : 20|2@0+ (1,0) [0|3] "Bit" MHU
  SG_ ACM_Airbag_Disabled : 21|1@0+ (1,0) [0|1] "-" MHU
  SG_ ACM_Development_Calibration : 22|1@0+ (1,0) [0|1] "-" MHU
  SG_ ACM_In_Disposal_Mode : 23|1@0+ (1,0) [0|1] "" MHU
  SG_ ACM_Seatbelt_Reminder_Request : 40|1@0+ (1,0) [0|1] "-" MHU
  SG_ ACM_SBR_Chime_Req : 41|1@0+ (1,0) [0|1] "" MHU
  SG_ ACM_SBR_Blinking_Req : 42|1@0+ (1,0) [0|1] "" MHU

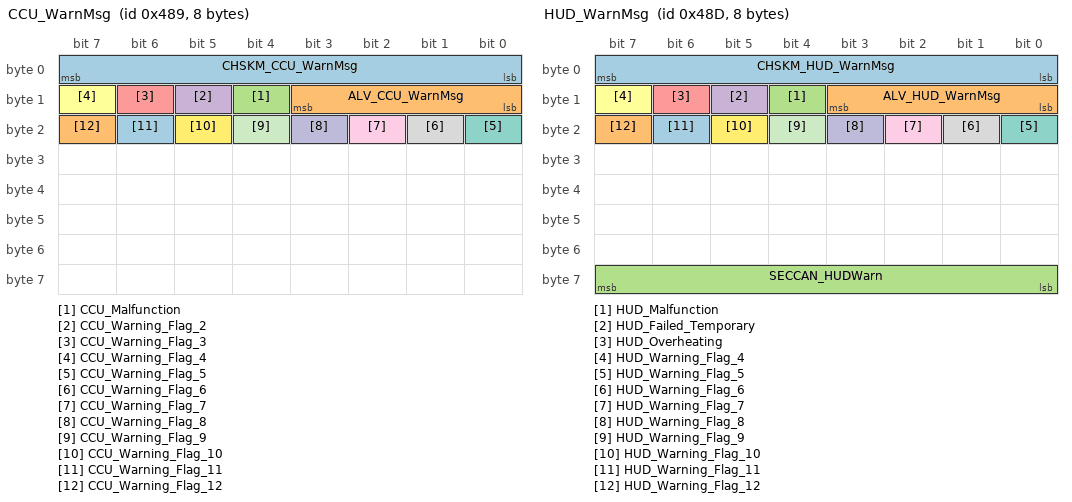
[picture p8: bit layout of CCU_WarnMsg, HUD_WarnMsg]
BO_ 1161 CCU_WarnMsg: 8 XGW_Info
  SG_ CHSKM_CCU_WarnMsg : 7|8@0+ (1,0) [0|255] "" MHU
  SG_ ALV_CCU_WarnMsg : 11|4@0+ (1,0) [0|14] "" MHU
  SG_ CCU_Malfunction : 12|1@0+ (1,0) [0|1] "" MHU
  SG_ CCU_Warning_Flag_2 : 13|1@0+ (1,0) [0|1] "-" MHU
  SG_ CCU_Warning_Flag_3 : 14|1@0+ (1,0) [0|1] "" MHU
  SG_ CCU_Warning_Flag_4 : 15|1@0+ (1,0) [0|1] "-" MHU
  SG_ CCU_Warning_Flag_5 : 16|1@0+ (1,0) [0|1] "-" MHU
  SG_ CCU_Warning_Flag_6 : 17|1@0+ (1,0) [0|1] "-" MHU
  SG_ CCU_Warning_Flag_7 : 18|1@0+ (1,0) [0|1] "-" MHU
  SG_ CCU_Warning_Flag_8 : 19|1@0+ (1,0) [0|1] "" MHU
  SG_ CCU_Warning_Flag_9 : 20|1@0+ (1,0) [0|1] "" MHU
  SG_ CCU_Warning_Flag_10 : 21|1@0+ (1,0) [0|1] "" MHU
  SG_ CCU_Warning_Flag_11 : 22|1@0+ (1,0) [0|1] "" MHU
  SG_ CCU_Warning_Flag_12 : 23|1@0+ (1,0) [0|1] "" MHU

BO_ 1165 HUD_WarnMsg: 8 HUD
  SG_ CHSKM_HUD_WarnMsg : 7|8@0+ (1,0) [0|255] "" MHU
  SG_ ALV_HUD_WarnMsg : 11|4@0+ (1,0) [0|14] "" MHU
  SG_ HUD_Malfunction : 12|1@0+ (1,0) [0|1] "-" MHU
  SG_ HUD_Failed_Temporary : 13|1@0+ (1,0) [0|1] "-" MHU
  SG_ HUD_Overheating : 14|1@0+ (1,0) [0|1] "-" MHU
  SG_ HUD_Warning_Flag_4 : 15|1@0+ (1,0) [0|1] "-" MHU
  SG_ HUD_Warning_Flag_5 : 16|1@0+ (1,0) [0|1] "-" MHU
  SG_ HUD_Warning_Flag_6 : 17|1@0+ (1,0) [0|1] "-" MHU
  SG_ HUD_Warning_Flag_7 : 18|1@0+ (1,0) [0|1] "-" MHU
  SG_ HUD_Warning_Flag_8 : 19|1@0+ (1,0) [0|1] "-" MHU
  SG_ HUD_Warning_Flag_9 : 20|1@0+ (1,0) [0|1] "-" MHU
  SG_ HUD_Warning_Flag_10 : 21|1@0+ (1,0) [0|1] "-" MHU
  SG_ HUD_Warning_Flag_11 : 22|1@0+ (1,0) [0|1] "-" MHU
  SG_ HUD_Warning_Flag_12 : 23|1@0+ (1,0) [0|1] "-" MHU
  SG_ SECCAN_HUDWarn : 63|8@0+ (1,0) [0|255] "" MHU

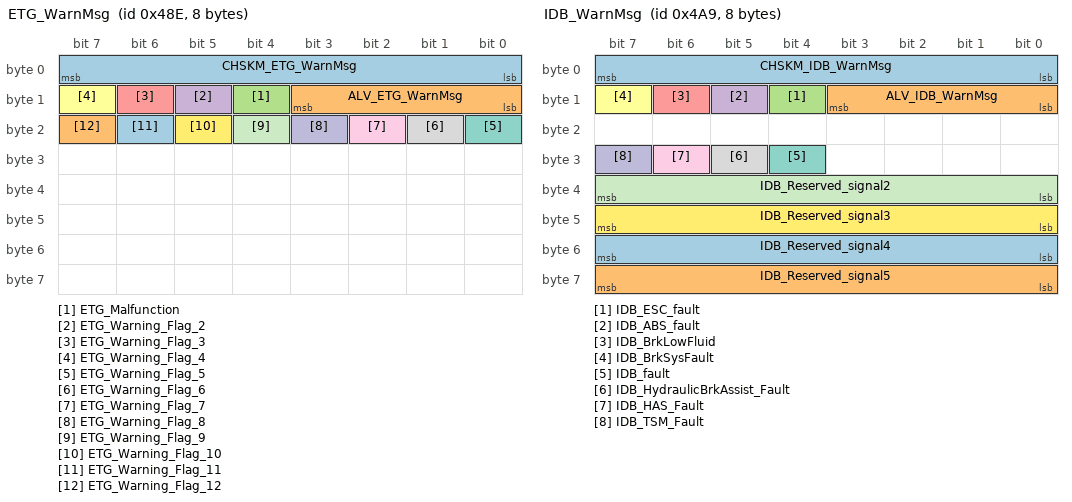
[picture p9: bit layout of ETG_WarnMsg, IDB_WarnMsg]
BO_ 1166 ETG_WarnMsg: 8 XGW_Info
  SG_ CHSKM_ETG_WarnMsg : 7|8@0+ (1,0) [0|255] "" MHU
  SG_ ALV_ETG_WarnMsg : 11|4@0+ (1,0) [0|14] "" MHU
  SG_ ETG_Malfunction : 12|1@0+ (1,0) [0|1] "-" MHU
  SG_ ETG_Warning_Flag_2 : 13|1@0+ (1,0) [0|1] "-" MHU
  SG_ ETG_Warning_Flag_3 : 14|1@0+ (1,0) [0|1] "" MHU
  SG_ ETG_Warning_Flag_4 : 15|1@0+ (1,0) [0|1] "" MHU
  SG_ ETG_Warning_Flag_5 : 16|1@0+ (1,0) [0|1] "-" MHU
  SG_ ETG_Warning_Flag_6 : 17|1@0+ (1,0) [0|1] "-" MHU
  SG_ ETG_Warning_Flag_7 : 18|1@0+ (1,0) [0|1] "-" MHU
  SG_ ETG_Warning_Flag_8 : 19|1@0+ (1,0) [0|1] "" MHU
  SG_ ETG_Warning_Flag_9 : 20|1@0+ (1,0) [0|1] "" MHU
  SG_ ETG_Warning_Flag_10 : 21|1@0+ (1,0) [0|1] "" MHU
  SG_ ETG_Warning_Flag_11 : 22|1@0+ (1,0) [0|1] "-" MHU
  SG_ ETG_Warning_Flag_12 : 23|1@0+ (1,0) [0|1] "" MHU

BO_ 1168 GS_WarnMsg: 8 XGW_Info
  SG_ CHSKM_GS_WarnMsg : 7|8@0+ (1,0) [0|255] "" MHU
  SG_ ALV_GS_WarnMsg : 11|4@0+ (1,0) [0|14] "" MHU
  SG_ GS_Warning_Flag_1 : 12|1@0+ (1,0) [0|1] "" MHU
  SG_ GS_Warning_Flag_2 : 13|1@0+ (1,0) [0|1] "" MHU
  SG_ GS_Warning_Flag_3 : 14|1@0+ (1,0) [0|1] "-" MHU
  SG_ GS_Warning_Flag_4 : 15|1@0+ (1,0) [0|1] "-" MHU
  SG_ GS_Warning_Flag_5 : 16|1@0+ (1,0) [0|1] "" MHU
  SG_ GS_Warning_Flag_6 : 17|1@0+ (1,0) [0|1] "-" MHU
  SG_ GS_Warning_Flag_7 : 18|1@0+ (1,0) [0|1] "" MHU
  SG_ GS_Warning_Flag_8 : 19|1@0+ (1,0) [0|1] "" MHU
  SG_ GS_Warning_Flag_9 : 20|1@0+ (1,0) [0|1] "-" MHU
  SG_ GS_Warning_Flag_10 : 21|1@0+ (1,0) [0|1] "-" MHU
  SG_ GS_Warning_Flag_11 : 22|1@0+ (1,0) [0|1] "" MHU
  SG_ GS_Warning_Flag_12 : 23|1@0+ (1,0) [0|1] "" MHU
  SG_ GS_Reserved_signal1 : 31|8@0+ (1,0) [0|255] "-" MHU
  SG_ GS_Reserved_signal2 : 39|8@0+ (1,0) [0|255] "" MHU
  SG_ GS_Reserved_signal3 : 47|8@0+ (1,0) [0|255] "" MHU
  SG_ GS_Reserved_signal4 : 55|8@0+ (1,0) [0|255] "-" MHU
  SG_ GS_Reserved_signal5 : 63|8@0+ (1,0) [0|255] "" MHU

BO_ 1171 BMS_WarnMsg: 8 XGW_Info
  SG_ CHSKM_BMS_WarnMsg : 7|8@0+ (1,0) [0|255] "" HUD,MHU
  SG_ ALV_BMS_WarnMsg : 11|4@0+ (1,0) [0|14] "" HUD,MHU
  SG_ BMS_PackTempSts : 13|2@0+ (1,0) [0|3] "" MHU
  SG_ BMS_ThermalRunaway : 14|1@0+ (1,0) [0|1] "" HUD,MHU
  SG_ BMS_BatteryReplacement : 15|1@0+ (1,0) [0|1] "" MHU
  SG_ BMS_Warning_PowerDegrade : 16|1@0+ (1,0) [0|1] "" MHU
  SG_ BMS_Warning_DeltaSoC : 17|1@0+ (1,0) [0|1] "" MHU
  SG_ BMS_Warning_HVILSts : 18|1@0+ (1,0) [0|1] "" MHU
  SG_ BMS_Warning_Isolation : 19|1@0+ (1,0) [0|1] "" MHU
  SG_ BMS_Warning_CoolantLeakage : 20|1@0+ (1,0) [0|1] "" MHU
  SG_ BMS_MalfunctionSts : 21|1@0+ (1,0) [0|1] "" MHU
  SG_ BMS_LowBattery : 23|2@0+ (1,0) [0|3] "" HUD,MHU
  SG_ BMS_Warning_DeltaTemperature : 31|8@0+ (1,0) [0|255] "" MHU
  SG_ BMS_Warning_BDUTemperatureSts : 39|8@0+ (1,0) [0|255] "" MHU
  SG_ BMS_Warning_Contactor_Aging : 47|1@0+ (1,0) [0|1] "" MHU
  SG_ BMS_Reserved_signal4 : 55|8@0+ (1,0) [0|255] "" MHU
  SG_ BMS_Reserved_signal5 : 63|8@0+ (1,0) [0|255] "" MHU

BO_ 1178 EDS_R_WarnMsg: 8 XGW_Info
  SG_ CHSKM_EDS_R_WarnMsg : 7|8@0+ (1,0) [0|255] "" MHU
  SG_ ALV_EDS_R_WarnMsg : 11|4@0+ (1,0) [0|14] "" MHU
  SG_ EDS_R_Error_1 : 12|1@0+ (1,0) [0|1] "-" MHU
  SG_ EDS_R_Error_2 : 13|1@0+ (1,0) [0|1] "-" MHU
  SG_ EDS_R_Error_3 : 14|1@0+ (1,0) [0|1] "-" MHU
  SG_ EDS_R_Error_4 : 15|1@0+ (1,0) [0|1] "-" MHU
  SG_ EDS_R_Error_5 : 16|1@0+ (1,0) [0|1] "-" MHU
  SG_ EDS_R_Error_6 : 17|1@0+ (1,0) [0|1] "-" MHU
  SG_ EDS_R_Error_7 : 18|1@0+ (1,0) [0|1] "-" MHU
  SG_ EDS_R_Error_8 : 19|1@0+ (1,0) [0|1] "-" MHU
  SG_ EDS_R_Error_9 : 20|1@0+ (1,0) [0|1] "-" MHU
  SG_ EDS_R_Error_10 : 21|1@0+ (1,0) [0|1] "-" MHU
  SG_ EDS_R_Error_11 : 22|1@0+ (1,0) [0|1] "-" MHU
  SG_ EDS_R_Error_12 : 23|1@0+ (1,0) [0|1] "-" MHU
  SG_ EDS_R_Error_13 : 24|1@0+ (1,0) [0|1] "-" MHU
  SG_ EDS_R_Error_14 : 25|1@0+ (1,0) [0|1] "-" MHU
  SG_ EDS_R_Error_15 : 26|1@0+ (1,0) [0|1] "-" MHU
  SG_ EDS_R_Error_16 : 27|1@0+ (1,0) [0|1] "-" MHU
  SG_ EDS_R_Error_17 : 28|1@0+ (1,0) [0|1] "-" MHU
  SG_ EDS_R_Error_18 : 29|1@0+ (1,0) [0|1] "-" MHU
  SG_ EDS_R_Error_19 : 30|1@0+ (1,0) [0|1] "-" MHU
  SG_ EDS_R_Error_20 : 31|1@0+ (1,0) [0|1] "-" MHU
  SG_ EDS_R_Error_21 : 32|1@0+ (1,0) [0|1] "-" MHU
  SG_ EDS_R_Error_22 : 33|1@0+ (1,0) [0|1] "-" MHU
  SG_ EDS_R_Error_23 : 34|1@0+ (1,0) [0|1] "-" MHU
  SG_ EDS_R_Error_24 : 35|1@0+ (1,0) [0|1] "-" MHU
  SG_ EDS_R_Error_25 : 36|1@0+ (1,0) [0|1] "-" MHU
  SG_ EDS_R_Error_26 : 37|1@0+ (1,0) [0|1] "-" MHU
  SG_ EDS_R_Error_27 : 38|1@0+ (1,0) [0|1] "-" MHU
  SG_ EDS_R_Error_28 : 39|1@0+ (1,0) [0|1] "-" MHU
  SG_ EDS_R_Error_29 : 40|1@0+ (1,0) [0|1] "-" MHU
  SG_ EDS_R_Error_30 : 41|1@0+ (1,0) [0|1] "-" MHU
  SG_ EDS_R_Error_31 : 42|1@0+ (1,0) [0|1] "-" MHU
  SG_ EDS_R_Error_32 : 43|1@0+ (1,0) [0|1] "-" MHU
  SG_ EDS_R_Error_33 : 44|1@0+ (1,0) [0|1] "-" MHU
  SG_ EDS_R_Error_34 : 45|1@0+ (1,0) [0|1] "-" MHU
  SG_ EDS_R_Error_35 : 46|1@0+ (1,0) [0|1] "-" MHU
  SG_ EDS_R_Error_36 : 47|1@0+ (1,0) [0|1] "-" MHU
  SG_ EDS_R_Error_37 : 48|1@0+ (1,0) [0|1] "-" MHU
  SG_ EDS_R_Error_38 : 49|1@0+ (1,0) [0|1] "-" MHU
  SG_ EDS_R_Error_39 : 50|1@0+ (1,0) [0|1] "-" MHU
  SG_ EDS_R_Error_40 : 51|1@0+ (1,0) [0|1] "-" MHU
  SG_ EDS_R_Error_41 : 52|1@0+ (1,0) [0|1] "-" MHU
  SG_ EDS_R_Error_42 : 53|1@0+ (1,0) [0|1] "-" MHU
  SG_ EDS_R_Error_43 : 54|1@0+ (1,0) [0|1] "-" MHU
  SG_ EDS_R_Error_44 : 55|1@0+ (1,0) [0|1] "-" MHU
  SG_ EDS_R_Error_45 : 56|1@0+ (1,0) [0|1] "-" MHU
  SG_ EDS_R_Error_46 : 57|1@0+ (1,0) [0|1] "-" MHU
  SG_ EDS_R_Error_47 : 58|1@0+ (1,0) [0|1] "-" MHU
  SG_ EDS_R_Error_48 : 59|1@0+ (1,0) [0|1] "-" MHU
  SG_ EDS_R_Error_49 : 60|1@0+ (1,0) [0|1] "-" MHU
  SG_ EDS_R_Error_50 : 61|1@0+ (1,0) [0|1] "-" MHU
  SG_ EDS_R_Error_51 : 62|1@0+ (1,0) [0|1] "-" MHU
  SG_ EDS_R_Error_52 : 63|1@0+ (1,0) [0|1] "-" MHU

BO_ 1179 EDS_F_WarnMsg: 8 XGW_Info
  SG_ CHSKM_EDS_F_WarnMsg : 7|8@0+ (1,0) [0|255] "" MHU
  SG_ ALV_EDS_F_WarnMsg : 11|4@0+ (1,0) [0|14] "" MHU
  SG_ EDS_F_Error_1 : 12|1@0+ (1,0) [0|1] "-" MHU
  SG_ EDS_F_Error_2 : 13|1@0+ (1,0) [0|1] "-" MHU
  SG_ EDS_F_Error_3 : 14|1@0+ (1,0) [0|1] "-" MHU
  SG_ EDS_F_Error_4 : 15|1@0+ (1,0) [0|1] "-" MHU
  SG_ EDS_F_Error_5 : 16|1@0+ (1,0) [0|1] "-" MHU
  SG_ EDS_F_Error_6 : 17|1@0+ (1,0) [0|1] "-" MHU
  SG_ EDS_F_Error_7 : 18|1@0+ (1,0) [0|1] "-" MHU
  SG_ EDS_F_Error_8 : 19|1@0+ (1,0) [0|1] "-" MHU
  SG_ EDS_F_Error_9 : 20|1@0+ (1,0) [0|1] "-" MHU
  SG_ EDS_F_Error_10 : 21|1@0+ (1,0) [0|1] "-" MHU
  SG_ EDS_F_Error_11 : 22|1@0+ (1,0) [0|1] "-" MHU
  SG_ EDS_F_Error_12 : 23|1@0+ (1,0) [0|1] "-" MHU
  SG_ EDS_F_Error_13 : 24|1@0+ (1,0) [0|1] "-" MHU
  SG_ EDS_F_Error_14 : 25|1@0+ (1,0) [0|1] "-" MHU
  SG_ EDS_F_Error_15 : 26|1@0+ (1,0) [0|1] "-" MHU
  SG_ EDS_F_Error_16 : 27|1@0+ (1,0) [0|1] "-" MHU
  SG_ EDS_F_Error_17 : 28|1@0+ (1,0) [0|1] "-" MHU
  SG_ EDS_F_Error_18 : 29|1@0+ (1,0) [0|1] "-" MHU
  SG_ EDS_F_Error_19 : 30|1@0+ (1,0) [0|1] "-" MHU
  SG_ EDS_F_Error_20 : 31|1@0+ (1,0) [0|1] "-" MHU
  SG_ EDS_F_Error_21 : 32|1@0+ (1,0) [0|1] "-" MHU
  SG_ EDS_F_Error_22 : 33|1@0+ (1,0) [0|1] "-" MHU
  SG_ EDS_F_Error_23 : 34|1@0+ (1,0) [0|1] "-" MHU
  SG_ EDS_F_Error_24 : 35|1@0+ (1,0) [0|1] "-" MHU
  SG_ EDS_F_Error_25 : 36|1@0+ (1,0) [0|1] "-" MHU
  SG_ EDS_F_Error_26 : 37|1@0+ (1,0) [0|1] "-" MHU
  SG_ EDS_F_Error_27 : 38|1@0+ (1,0) [0|1] "-" MHU
  SG_ EDS_F_Error_28 : 39|1@0+ (1,0) [0|1] "-" MHU
  SG_ EDS_F_Error_29 : 40|1@0+ (1,0) [0|1] "-" MHU
  SG_ EDS_F_Error_30 : 41|1@0+ (1,0) [0|1] "-" MHU
  SG_ EDS_F_Error_31 : 42|1@0+ (1,0) [0|1] "-" MHU
  SG_ EDS_F_Error_32 : 43|1@0+ (1,0) [0|1] "-" MHU
  SG_ EDS_F_Error_33 : 44|1@0+ (1,0) [0|1] "-" MHU
  SG_ EDS_F_Error_34 : 45|1@0+ (1,0) [0|1] "-" MHU
  SG_ EDS_F_Error_35 : 46|1@0+ (1,0) [0|1] "-" MHU
  SG_ EDS_F_Error_36 : 47|1@0+ (1,0) [0|1] "-" MHU
  SG_ EDS_F_Error_37 : 48|1@0+ (1,0) [0|1] "-" MHU
  SG_ EDS_F_Error_38 : 49|1@0+ (1,0) [0|1] "-" MHU
  SG_ EDS_F_Error_39 : 50|1@0+ (1,0) [0|1] "-" MHU
  SG_ EDS_F_Error_40 : 51|1@0+ (1,0) [0|1] "-" MHU
  SG_ EDS_F_Error_41 : 52|1@0+ (1,0) [0|1] "-" MHU
  SG_ EDS_F_Error_42 : 53|1@0+ (1,0) [0|1] "-" MHU
  SG_ EDS_F_Error_43 : 54|1@0+ (1,0) [0|1] "-" MHU
  SG_ EDS_F_Error_44 : 55|1@0+ (1,0) [0|1] "-" MHU
  SG_ EDS_F_Error_45 : 56|1@0+ (1,0) [0|1] "-" MHU
  SG_ EDS_F_Error_46 : 57|1@0+ (1,0) [0|1] "-" MHU
  SG_ EDS_F_Error_47 : 58|1@0+ (1,0) [0|1] "-" MHU
  SG_ EDS_F_Error_48 : 59|1@0+ (1,0) [0|1] "-" MHU
  SG_ EDS_F_Error_49 : 60|1@0+ (1,0) [0|1] "-" MHU
  SG_ EDS_F_Error_50 : 61|1@0+ (1,0) [0|1] "-" MHU
  SG_ EDS_F_Error_51 : 62|1@0+ (1,0) [0|1] "-" MHU
  SG_ EDS_F_Error_52 : 63|1@0+ (1,0) [0|1] "-" MHU

BO_ 1191 RCU_WarnMsg: 8 XGW_Info
  SG_ CHSKM_RCU_WarnMsg : 7|8@0+ (1,0) [0|255] "" MHU
  SG_ ALV_RCU_WarnMsg : 11|4@0+ (1,0) [0|14] "" MHU
  SG_ RCU_DAA_NoOpDoorOpen : 12|1@0+ (1,0) [0|1] "" MHU
  SG_ RCU_EHandBrk_fault : 13|1@0+ (1,0) [0|1] "" MHU
  SG_ RCU_EOL_NotDone : 14|1@0+ (1,0) [0|1] "" MHU
  SG_ RCU_ECD_RWU_active : 15|1@0+ (1,0) [0|1] "" MHU
  SG_ RCU_ParkOnSteepInclination : 16|1@0+ (1,0) [0|1] "" MHU
  SG_ RCU_BrkForceNotEnough : 17|1@0+ (1,0) [0|1] "" MHU
  SG_ RCU_ReleaseEPB_Wo_PressBrk : 20|1@0+ (1,0) [0|1] "" MHU
  SG_ RCU_ParkBrkApplied : 21|1@0+ (1,0) [0|1] "" MHU
  SG_ RCU_Swch_Mafnc : 27|1@0+ (1,0) [0|1] "" MHU
  SG_ RCU_DAA_NoOpBeltUnbuckled : 28|1@0+ (1,0) [0|1] "" MHU
  SG_ RCU_RollerBenchMode : 29|1@0+ (1,0) [0|1] "" MHU
  SG_ RCU_EPB_ParkLampState : 31|2@0+ (1,0) [0|3] "" MHU
  SG_ RCU_EPB_WarnLampState : 34|2@0+ (1,0) [0|3] "" MHU
  SG_ RCU_WflagRes36 : 36|1@0+ (1,0) [0|1] "" MHU
  SG_ RCU_WflagRes37 : 37|1@0+ (1,0) [0|1] "" MHU
  SG_ RCU_WflagRes38 : 38|1@0+ (1,0) [0|1] "" MHU
  SG_ RCU_WflagRes39 : 39|1@0+ (1,0) [0|1] "" MHU
  SG_ RCU_WflagRes40 : 40|1@0+ (1,0) [0|1] "" MHU
  SG_ RCU_WflagRes41 : 41|1@0+ (1,0) [0|1] "" MHU
  SG_ RCU_WflagRes42 : 42|1@0+ (1,0) [0|1] "" MHU
  SG_ RCU_WflagRes43 : 43|1@0+ (1,0) [0|1] "" MHU
  SG_ RCU_WflagRes44 : 44|1@0+ (1,0) [0|1] "" MHU
  SG_ RCU_WflagRes45 : 45|1@0+ (1,0) [0|1] "" MHU
  SG_ RCU_WflagRes46 : 46|1@0+ (1,0) [0|1] "" MHU
  SG_ RCU_WflagRes47 : 47|1@0+ (1,0) [0|1] "" MHU
  SG_ RCU_Reserved_signal1 : 55|8@0+ (1,0) [0|255] "" MHU

BO_ 1192 EPS_WarnMsg: 8 XGW_Info
  SG_ CHSKM_EPS_WarnMsg : 7|8@0+ (1,0) [0|255] "" MHU
  SG_ ALV_EPS_WarnMsg : 11|4@0+ (1,0) [0|14] "" MHU
  SG_ EPS_Malfunction : 12|1@0+ (1,0) [0|1] "-" MHU
  SG_ EPS_Reduced : 13|1@0+ (1,0) [0|1] "-" MHU
  SG_ EPS_Overheat : 14|1@0+ (1,0) [0|1] "" MHU
  SG_ EPS_NotReady : 15|1@0+ (1,0) [0|1] "-" MHU
  SG_ EPS_Warning_Flag_5 : 16|1@0+ (1,0) [0|1] "-" MHU
  SG_ EPS_Warning_Flag_6 : 17|1@0+ (1,0) [0|1] "" MHU
  SG_ EPS_Warning_Flag_7 : 18|1@0+ (1,0) [0|1] "" MHU
  SG_ EPS_Warning_Flag_8 : 19|1@0+ (1,0) [0|1] "-" MHU
  SG_ EPS_Warning_Flag_9 : 20|1@0+ (1,0) [0|1] "-" MHU
  SG_ EPS_Warning_Flag_10 : 21|1@0+ (1,0) [0|1] "" MHU
  SG_ EPS_Warning_Flag_11 : 22|1@0+ (1,0) [0|1] "" MHU
  SG_ EPS_Warning_Flag_12 : 23|1@0+ (1,0) [0|1] "-" MHU
  SG_ EPS_Reserved_signal1 : 31|8@0+ (1,0) [0|255] "" MHU
  SG_ EPS_Reserved_signal2 : 39|8@0+ (1,0) [0|255] "" MHU
  SG_ EPS_Reserved_signal3 : 47|8@0+ (1,0) [0|255] "-" MHU
  SG_ EPS_Reserved_signal4 : 55|8@0+ (1,0) [0|255] "" MHU
  SG_ EPS_Reserved_signal5 : 63|8@0+ (1,0) [0|255] "" MHU

BO_ 1193 IDB_WarnMsg: 8 XGW_Info
  SG_ CHSKM_IDB_WarnMsg : 7|8@0+ (1,0) [0|255] "" MHU
  SG_ ALV_IDB_WarnMsg : 11|4@0+ (1,0) [0|14] "" MHU
  SG_ IDB_ESC_fault : 12|1@0+ (1,0) [0|1] "-" MHU
  SG_ IDB_ABS_fault : 13|1@0+ (1,0) [0|1] "" MHU
  SG_ IDB_BrkLowFluid : 14|1@0+ (1,0) [0|1] "" MHU
  SG_ IDB_BrkSysFault : 15|1@0+ (1,0) [0|1] "-" MHU
  SG_ IDB_fault : 28|1@0+ (1,0) [0|1] "" MHU
  SG_ IDB_HydraulicBrkAssist_Fault : 29|1@0+ (1,0) [0|1] "-" MHU
  SG_ IDB_HAS_Fault : 30|1@0+ (1,0) [0|1] "" MHU
  SG_ IDB_TSM_Fault : 31|1@0+ (1,0) [0|1] "" MHU
  SG_ IDB_Reserved_signal2 : 39|8@0+ (1,0) [0|255] "-" MHU
  SG_ IDB_Reserved_signal3 : 47|8@0+ (1,0) [0|255] "-" MHU
  SG_ IDB_Reserved_signal4 : 55|8@0+ (1,0) [0|255] "-" MHU
  SG_ IDB_Reserved_signal5 : 63|8@0+ (1,0) [0|255] "" MHU

BO_ 1196 VCU_WarnMsg: 8 XGW_Info
  SG_ CHSKM_VCU_WarnMsg : 7|8@0+ (1,0) [0|255] "" MHU
  SG_ ALV_VCU_WarnMsg : 11|4@0+ (1,0) [0|14] "" MHU
  SG_ VCU_GearPOnlyAtStationaryAlert : 12|1@0+ (1,0) [0|1] "" MHU
  SG_ VCU_GearP_NotPossibleAlert : 13|1@0+ (1,0) [0|1] "" MHU
  SG_ VCU_PressBrakeToEngageGear : 14|1@0+ (1,0) [0|1] "" MHU
  SG_ VCU_CantChangeGear : 15|1@0+ (1,0) [0|1] "" MHU
  SG_ VCU_GearMalfunction : 16|1@0+ (1,0) [0|1] "" MHU
  SG_ VCU_RangeAlert : 17|1@0+ (1,0) [0|1] "" MHU
  SG_ VCU_HVSystemReduced : 18|1@0+ (1,0) [0|1] "" MHU
  SG_ VCU_FrontEDSReduced : 19|1@0+ (1,0) [0|1] "" MHU
  SG_ VCU_FrontEDS_Malfunc : 20|1@0+ (1,0) [0|1] "" MHU
  SG_ VCU_RearEDSReduced : 21|1@0+ (1,0) [0|1] "" MHU
  SG_ VCU_RearEDS_Malfunc : 22|1@0+ (1,0) [0|1] "" MHU
  SG_ VCU_CoolingSystem_Malfunc : 23|1@0+ (1,0) [0|1] "" MHU
  SG_ VCU_NeutralRequest : 24|1@0+ (1,0) [0|1] "" MHU
  SG_ VCU_SoftShutdown : 25|1@0+ (1,0) [0|1] "" MHU
  SG_ VCU_EmergencyShutdown : 26|1@0+ (1,0) [0|1] "" MHU
  SG_ VCU_ChgPortDoorSys_Malfunc : 27|1@0+ (1,0) [0|1] "" MHU
  SG_ VCU_Gearchange_NotPossible : 28|1@0+ (1,0) [0|1] "" MHU
  SG_ VCU_12v_Warning : 29|1@0+ (1,0) [0|1] "" MHU
  SG_ VCU_WflagRes19 : 30|1@0+ (1,0) [0|1] "" MHU
  SG_ VCU_WflagRes20 : 31|1@0+ (1,0) [0|1] "" MHU
  SG_ VCU_WflagRes21 : 32|1@0+ (1,0) [0|1] "" MHU
  SG_ VCU_WflagRes22 : 33|1@0+ (1,0) [0|1] "" MHU
  SG_ VCU_WflagRes23 : 34|1@0+ (1,0) [0|1] "" MHU
  SG_ VCU_WflagRes24 : 35|1@0+ (1,0) [0|1] "" MHU
  SG_ VCU_WflagRes25 : 36|1@0+ (1,0) [0|1] "" MHU
  SG_ VCU_WflagRes26 : 37|1@0+ (1,0) [0|1] "" MHU
  SG_ VCU_WflagRes27 : 38|1@0+ (1,0) [0|1] "" MHU
  SG_ VCU_SuperFastCharge_longer : 39|1@0+ (1,0) [0|1] "" MHU
  SG_ VCU_Reserved_signal1 : 47|8@0+ (1,0) [0|255] "" MHU
  SG_ VCU_Reserved_signal2 : 55|8@0+ (1,0) [0|255] "" MHU
  SG_ VCU_Reserved_signal3 : 63|8@0+ (1,0) [0|255] "" MHU

BO_ 1198 EASC_WarnMsg: 8 EASC
  SG_ CHSKM_EASC_WarnMsg : 7|8@0+ (1,0) [0|255] "" MHU
  SG_ ALV_EASC_WarnMsg : 11|4@0+ (1,0) [0|14] "" MHU
  SG_ EASC_Warning_Flag_1 : 12|1@0+ (1,0) [0|1] "-" MHU
  SG_ EASC_Warning_Flag_2 : 13|1@0+ (1,0) [0|1] "-" MHU
  SG_ EASC_Warning_Flag_3 : 14|1@0+ (1,0) [0|1] "-" MHU
  SG_ EASC_Warning_Flag_4 : 15|1@0+ (1,0) [0|1] "-" MHU
  SG_ EASC_Warning_Flag_5 : 16|1@0+ (1,0) [0|1] "-" MHU
  SG_ EASC_Warning_Flag_6 : 17|1@0+ (1,0) [0|1] "-" MHU
  SG_ EASC_Warning_Flag_7 : 18|1@0+ (1,0) [0|1] "-" MHU
  SG_ EASC_Warning_Flag_8 : 19|1@0+ (1,0) [0|1] "-" MHU
  SG_ EASC_Warning_Flag_9 : 20|1@0+ (1,0) [0|1] "-" MHU
  SG_ EASC_Warning_Flag_10 : 21|1@0+ (1,0) [0|1] "-" MHU
  SG_ EASC_Warning_Flag_11 : 22|1@0+ (1,0) [0|1] "-" MHU
  SG_ EASC_Warning_Flag_12 : 23|1@0+ (1,0) [0|1] "-" MHU
  SG_ EASC_Reserved_signal1 : 31|8@0+ (1,0) [0|255] "-" MHU
  SG_ EASC_Reserved_signal2 : 39|8@0+ (1,0) [0|255] "-" MHU
  SG_ EASC_Reserved_signal3 : 47|8@0+ (1,0) [0|255] "-" MHU
  SG_ EASC_Reserved_signal4 : 55|8@0+ (1,0) [0|255] "-" MHU
  SG_ EASC_Reserved_signal5 : 63|8@0+ (1,0) [0|255] "-" MHU

BO_ 1199 CPD_WarnMsg: 8 CPD
  SG_ CHSKM_CPD_WarnMsg : 7|8@0+ (1,0) [0|255] "" MHU
  SG_ ALV_CPD_WarnMsg : 11|4@0+ (1,0) [0|14] "" MHU
  SG_ CPD_Malfunction : 12|1@0+ (1,0) [0|1] "" MHU
  SG_ CPD_SensorFault : 14|2@0+ (1,0) [0|3] "" MHU
  SG_ CPD_Warning_Flag_4 : 15|1@0+ (1,0) [0|1] "" MHU
  SG_ CPD_Warning_Flag_5 : 16|1@0+ (1,0) [0|1] "" MHU
  SG_ CPD_Warning_Flag_6 : 17|1@0+ (1,0) [0|1] "" MHU
  SG_ CPD_Warning_Flag_7 : 18|1@0+ (1,0) [0|1] "" MHU
  SG_ CPD_Warning_Flag_8 : 19|1@0+ (1,0) [0|1] "" MHU
  SG_ CPD_Warning_Flag_9 : 20|1@0+ (1,0) [0|1] "" MHU
  SG_ CPD_Warning_Flag_10 : 21|1@0+ (1,0) [0|1] "" MHU
  SG_ CPD_Warning_Flag_11 : 22|1@0+ (1,0) [0|1] "" MHU
  SG_ CPD_Warning_Flag_12 : 23|1@0+ (1,0) [0|1] "" MHU
  SG_ CPD_Reserved_signal1 : 31|8@0+ (1,0) [0|255] "" MHU
  SG_ CPD_Reserved_signal2 : 39|8@0+ (1,0) [0|255] "" MHU
  SG_ CPD_Reserved_signal3 : 47|8@0+ (1,0) [0|255] "" MHU
  SG_ CPD_Reserved_signal4 : 55|8@0+ (1,0) [0|255] "" MHU
  SG_ CPD_Reserved_signal5 : 63|8@0+ (1,0) [0|255] "" MHU

BA_DEF_ BO_  "GenMsgSendType" ENUM "Cyclic","NotUsed","NotUsed","NotUsed","NotUsed","NotUsed","NotUsed","IfActive","NoMsgSendType","NotUsed";
BA_DEF_ BO_  "GenMsgILSupport" ENUM "No","Yes";
BA_DEF_ BO_  "DiagResponse" ENUM "No","Yes";
BA_DEF_ BO_  "DiagRequest" ENUM "No","Yes";
BA_DEF_ BO_  "NmAsrMessage" ENUM "No","Yes";
BA_DEF_ BO_  "DiagState" ENUM "No","Yes";
BA_DEF_ BO_  "DiagUudtResponse" ENUM "False","True";
BA_DEF_ BO_  "GenMsgStartDelayTime" INT 0 65535;
BA_DEF_ BO_  "GenMsgDelayTime" INT 0 0;
BA_DEF_ BO_  "GenMsgNrOfRepetition" INT 0 0;
BA_DEF_ BO_  "GenMsgCycleTimeFast" INT 0 0;
BA_DEF_ BO_  "GenMsgCycleTime" INT 0 0;
BA_DEF_ SG_  "GenSigSendType" ENUM "Cyclic","OnWrite","OnWriteWithRepetition","OnChange","OnChangeWithRepetition","IfActive","IfActiveWithRepetition","NoSigSendType","NotUsed","NotUsed","NotUsed","NotUsed","NotUsed";
BA_DEF_ SG_  "InvalidValue" STRING;
BA_DEF_ SG_  "GenSigStartValue" INT 0 0;
BA_DEF_ SG_  "GenSigTimeoutTime_ALL" INT 0 65535;
BA_DEF_DEF_  "DiagRequest" "No";
BA_DEF_DEF_  "DiagResponse" "No";
BA_DEF_DEF_  "DiagState" "No";
BA_DEF_DEF_  "DiagUudtResponse" "False";
BA_DEF_DEF_  "GenMsgCycleTime" 0;
BA_DEF_DEF_  "GenMsgCycleTimeFast" 0;
BA_DEF_DEF_  "GenMsgDelayTime" 0;
BA_DEF_DEF_  "GenMsgILSupport" "Yes";
BA_DEF_DEF_  "GenMsgNrOfRepetition" 0;
BA_DEF_DEF_  "GenMsgSendType" "NoMsgSendType";
BA_DEF_DEF_  "GenMsgStartDelayTime" 0;
BA_DEF_DEF_  "GenSigSendType" "Cyclic";
BA_DEF_DEF_  "GenSigStartValue" 0;
BA_DEF_DEF_  "GenSigTimeoutTime_ALL" 0;
BA_DEF_DEF_  "NmAsrMessage" "No";
BA_ "GenMsgCycleTime" BO_ 1095 200;
BA_ "GenMsgSendType" BO_ 1095 0;
BA_ "GenMsgCycleTime" BO_ 1096 100;
BA_ "GenMsgSendType" BO_ 1096 0;
BA_ "GenMsgCycleTime" BO_ 1097 100;
BA_ "GenMsgSendType" BO_ 1097 0;
BA_ "GenMsgCycleTimeFast" BO_ 1104 100;
BA_ "GenMsgNrOfRepetition" BO_ 1104 3;
BA_ "GenMsgCycleTime" BO_ 1105 100;
BA_ "GenMsgSendType" BO_ 1105 0;
BA_ "GenMsgCycleTime" BO_ 1106 100;
BA_ "GenMsgSendType" BO_ 1106 0;
BA_ "GenMsgCycleTime" BO_ 1107 100;
BA_ "GenMsgSendType" BO_ 1107 0;
BA_ "GenMsgCycleTime" BO_ 1108 100;
BA_ "GenMsgSendType" BO_ 1108 0;
BA_ "GenMsgCycleTime" BO_ 1109 100;
BA_ "GenMsgSendType" BO_ 1109 0;
BA_ "GenMsgCycleTimeFast" BO_ 1112 100;
BA_ "GenMsgNrOfRepetition" BO_ 1112 3;
BA_ "GenMsgCycleTimeFast" BO_ 1113 100;
BA_ "GenMsgNrOfRepetition" BO_ 1113 3;
BA_ "GenMsgCycleTime" BO_ 1124 50;
BA_ "GenMsgSendType" BO_ 1124 0;
BA_ "GenMsgCycleTime" BO_ 1125 50;
BA_ "GenMsgSendType" BO_ 1125 0;
BA_ "GenMsgCycleTime" BO_ 1136 100;
BA_ "GenMsgSendType" BO_ 1136 0;
BA_ "GenMsgCycleTime" BO_ 1137 100;
BA_ "GenMsgSendType" BO_ 1137 0;
BA_ "GenMsgCycleTime" BO_ 1138 100;
BA_ "GenMsgSendType" BO_ 1138 0;
BA_ "GenMsgCycleTime" BO_ 1152 1000;
BA_ "GenMsgCycleTimeFast" BO_ 1152 100;
BA_ "GenMsgNrOfRepetition" BO_ 1152 2;
BA_ "GenMsgSendType" BO_ 1152 0;
BA_ "GenMsgCycleTime" BO_ 1153 1000;
BA_ "GenMsgCycleTimeFast" BO_ 1153 100;
BA_ "GenMsgDelayTime" BO_ 1153 25;
BA_ "GenMsgNrOfRepetition" BO_ 1153 2;
BA_ "GenMsgSendType" BO_ 1153 0;
BA_ "GenMsgCycleTime" BO_ 1154 1000;
BA_ "GenMsgCycleTimeFast" BO_ 1154 100;
BA_ "GenMsgNrOfRepetition" BO_ 1154 2;
BA_ "GenMsgSendType" BO_ 1154 0;
BA_ "GenMsgCycleTime" BO_ 1155 50;
BA_ "GenMsgSendType" BO_ 1155 0;
BA_ "GenMsgCycleTime" BO_ 1156 50;
BA_ "GenMsgSendType" BO_ 1156 0;
BA_ "GenMsgCycleTime" BO_ 1160 1000;
BA_ "GenMsgCycleTimeFast" BO_ 1160 100;
BA_ "GenMsgNrOfRepetition" BO_ 1160 2;
BA_ "GenMsgSendType" BO_ 1160 0;
BA_ "GenMsgCycleTime" BO_ 1161 1000;
BA_ "GenMsgCycleTimeFast" BO_ 1161 100;
BA_ "GenMsgNrOfRepetition" BO_ 1161 2;
BA_ "GenMsgSendType" BO_ 1161 0;
BA_ "GenMsgCycleTime" BO_ 1165 1000;
BA_ "GenMsgCycleTimeFast" BO_ 1165 100;
BA_ "GenMsgNrOfRepetition" BO_ 1165 2;
BA_ "GenMsgSendType" BO_ 1165 0;
BA_ "GenMsgCycleTime" BO_ 1166 100;
BA_ "GenMsgSendType" BO_ 1166 0;
BA_ "GenMsgCycleTime" BO_ 1168 1000;
BA_ "GenMsgCycleTimeFast" BO_ 1168 100;
BA_ "GenMsgNrOfRepetition" BO_ 1168 2;
BA_ "GenMsgSendType" BO_ 1168 0;
BA_ "GenMsgCycleTime" BO_ 1171 1000;
BA_ "GenMsgCycleTimeFast" BO_ 1171 100;
BA_ "GenMsgILSupport" BO_ 1171 0;
BA_ "GenMsgNrOfRepetition" BO_ 1171 2;
BA_ "GenMsgSendType" BO_ 1171 0;
BA_ "GenMsgCycleTime" BO_ 1178 1000;
BA_ "GenMsgCycleTimeFast" BO_ 1178 100;
BA_ "GenMsgNrOfRepetition" BO_ 1178 2;
BA_ "GenMsgSendType" BO_ 1178 0;
BA_ "GenMsgCycleTime" BO_ 1179 1000;
BA_ "GenMsgCycleTimeFast" BO_ 1179 100;
BA_ "GenMsgNrOfRepetition" BO_ 1179 2;
BA_ "GenMsgSendType" BO_ 1179 0;
BA_ "GenMsgCycleTime" BO_ 1191 1000;
BA_ "GenMsgCycleTimeFast" BO_ 1191 100;
BA_ "GenMsgNrOfRepetition" BO_ 1191 2;
BA_ "GenMsgSendType" BO_ 1191 0;
BA_ "GenMsgCycleTime" BO_ 1192 1000;
BA_ "GenMsgCycleTimeFast" BO_ 1192 100;
BA_ "GenMsgNrOfRepetition" BO_ 1192 2;
BA_ "GenMsgSendType" BO_ 1192 0;
BA_ "GenMsgCycleTime" BO_ 1193 1000;
BA_ "GenMsgCycleTimeFast" BO_ 1193 100;
BA_ "GenMsgNrOfRepetition" BO_ 1193 2;
BA_ "GenMsgSendType" BO_ 1193 0;
BA_ "GenMsgCycleTime" BO_ 1196 1000;
BA_ "GenMsgCycleTimeFast" BO_ 1196 100;
BA_ "GenMsgNrOfRepetition" BO_ 1196 2;
BA_ "GenMsgSendType" BO_ 1196 0;
BA_ "GenMsgCycleTime" BO_ 1198 1000;
BA_ "GenMsgCycleTimeFast" BO_ 1198 100;
BA_ "GenMsgNrOfRepetition" BO_ 1198 2;
BA_ "GenMsgSendType" BO_ 1198 0;
BA_ "GenMsgCycleTime" BO_ 1199 1000;
BA_ "GenMsgCycleTimeFast" BO_ 1199 100;
BA_ "GenMsgNrOfRepetition" BO_ 1199 2;
BA_ "GenMsgSendType" BO_ 1199 0;
BA_ "GenSigSendType" SG_ 1094 MHU_TBT_Icon 1;
BA_ "GenSigSendType" SG_ 1094 MHU_Junction_MsgNum 1;
BA_ "GenSigStartValue" SG_ 1094 MHU_Junction_MsgNum 1;
BA_ "GenSigSendType" SG_ 1094 MHU_Junction_TotalMsg 1;
BA_ "GenSigStartValue" SG_ 1094 MHU_Junction_TotalMsg 1;
BA_ "GenSigSendType" SG_ 1094 MHU_DrivingSide 1;
BA_ "GenSigSendType" SG_ 1094 MHU_Junction_type 1;
BA_ "InvalidValue" SG_ 1094 MHU_Junction_type "3h";
BA_ "GenSigSendType" SG_ 1094 MHU_JunctionElement1 1;
BA_ "InvalidValue" SG_ 1094 MHU_JunctionElement1 "1Fh";
BA_ "GenSigSendType" SG_ 1094 MHU_JunctionElement0 1;
BA_ "InvalidValue" SG_ 1094 MHU_JunctionElement0 "1Fh";
BA_ "GenSigSendType" SG_ 1094 MHU_JunctionElement2 1;
BA_ "InvalidValue" SG_ 1094 MHU_JunctionElement2 "1Fh";
BA_ "GenSigSendType" SG_ 1094 MHU_JunctionElement4 1;
BA_ "InvalidValue" SG_ 1094 MHU_JunctionElement4 "1Fh";
BA_ "GenSigSendType" SG_ 1094 MHU_JunctionElement3 1;
BA_ "InvalidValue" SG_ 1094 MHU_JunctionElement3 "1Fh";
BA_ "GenSigSendType" SG_ 1094 MHU_JunctionElement5 1;
BA_ "InvalidValue" SG_ 1094 MHU_JunctionElement5 "1Fh";
BA_ "GenSigSendType" SG_ 1094 MHU_JunctionElement6 1;
BA_ "InvalidValue" SG_ 1094 MHU_JunctionElement6 "1Fh";
BA_ "GenSigTimeoutTime_ALL" SG_ 1095 CHKSM_MHU_SET_CarMode 1000;
BA_ "InvalidValue" SG_ 1095 CHKSM_MHU_SET_CarMode "null";
BA_ "GenSigTimeoutTime_ALL" SG_ 1095 ALV_MHU_SET_CarMode 1000;
BA_ "InvalidValue" SG_ 1095 ALV_MHU_SET_CarMode "Fh";
BA_ "GenSigTimeoutTime_ALL" SG_ 1095 MHU_SET_TransportMode 1000;
BA_ "InvalidValue" SG_ 1095 MHU_SET_TransportMode "3h";
BA_ "GenSigTimeoutTime_ALL" SG_ 1095 MHU_Request_CarOFF 1000;
BA_ "InvalidValue" SG_ 1095 MHU_Request_CarOFF "3h";
BA_ "GenSigTimeoutTime_ALL" SG_ 1095 MHU_SET_ChildMode 1000;
BA_ "InvalidValue" SG_ 1095 MHU_SET_ChildMode "null";
BA_ "InvalidValue" SG_ 1095 MHU_SET_ChildMode "3h";
BA_ "GenSigTimeoutTime_ALL" SG_ 1095 MHU_SET_GameMode 1000;
BA_ "InvalidValue" SG_ 1095 MHU_SET_GameMode "null";
BA_ "InvalidValue" SG_ 1095 MHU_SET_GameMode "3h";
BA_ "GenSigTimeoutTime_ALL" SG_ 1095 MHU_SET_KaraokeMode 1000;
BA_ "InvalidValue" SG_ 1095 MHU_SET_KaraokeMode "3h";
BA_ "InvalidValue" SG_ 1095 MHU_SET_KaraokeMode "null";
BA_ "GenSigStartValue" SG_ 1095 MHU_Req_StoppingMode 4;
BA_ "GenSigTimeoutTime_ALL" SG_ 1095 MHU_Req_StoppingMode 1000;
BA_ "InvalidValue" SG_ 1095 MHU_Req_StoppingMode "7h";
BA_ "GenSigTimeoutTime_ALL" SG_ 1095 MHU_SET_WashMode 1000;
BA_ "InvalidValue" SG_ 1095 MHU_SET_WashMode "3h";
BA_ "InvalidValue" SG_ 1095 MHU_SET_WashMode "null";
BA_ "GenSigTimeoutTime_ALL" SG_ 1095 MHU_SET_StopMode 1000;
BA_ "InvalidValue" SG_ 1095 MHU_SET_StopMode "3h";
BA_ "GenSigTimeoutTime_ALL" SG_ 1095 MHU_AVH_Sw 1000;
BA_ "InvalidValue" SG_ 1095 MHU_AVH_Sw "3h";
BA_ "GenSigTimeoutTime_ALL" SG_ 1096 CHKSM_EDS_Error_FR_B 500;
BA_ "InvalidValue" SG_ 1096 CHKSM_EDS_Error_FR_B "null";
BA_ "GenSigTimeoutTime_ALL" SG_ 1096 ALV_EDS_Error_FR_B 500;
BA_ "InvalidValue" SG_ 1096 ALV_EDS_Error_FR_B "Fh";
BA_ "GenSigTimeoutTime_ALL" SG_ 1096 EDS_iDcLnkOvCLimFail_FWD 500;
BA_ "InvalidValue" SG_ 1096 EDS_iDcLnkOvCLimFail_FWD "null";
BA_ "GenSigTimeoutTime_ALL" SG_ 1096 EDS_MotBlockedFault_FWD 500;
BA_ "InvalidValue" SG_ 1096 EDS_MotBlockedFault_FWD "null";
BA_ "GenSigTimeoutTime_ALL" SG_ 1096 EDS_RSLErr_FWD 500;
BA_ "InvalidValue" SG_ 1096 EDS_RSLErr_FWD "null";
BA_ "GenSigTimeoutTime_ALL" SG_ 1096 EDS_MotTrqLimFault_FWD 500;
BA_ "InvalidValue" SG_ 1096 EDS_MotTrqLimFault_FWD "null";
BA_ "GenSigTimeoutTime_ALL" SG_ 1096 EDS_VCUChksumFault_FWD 500;
BA_ "InvalidValue" SG_ 1096 EDS_VCUChksumFault_FWD "null";
BA_ "GenSigTimeoutTime_ALL" SG_ 1096 EDS_IGBTFault_FWD 500;
BA_ "InvalidValue" SG_ 1096 EDS_IGBTFault_FWD "null";
BA_ "GenSigTimeoutTime_ALL" SG_ 1096 EDS_CANBusoffFault_FWD 500;
BA_ "InvalidValue" SG_ 1096 EDS_CANBusoffFault_FWD "null";
BA_ "GenSigTimeoutTime_ALL" SG_ 1096 EDS_TDrvBoardOvHiWarn_FWD 500;
BA_ "InvalidValue" SG_ 1096 EDS_TDrvBoardOvHiWarn_FWD "null";
BA_ "GenSigTimeoutTime_ALL" SG_ 1096 EDS_TIGBTOvHiFault_FWD 500;
BA_ "InvalidValue" SG_ 1096 EDS_TIGBTOvHiFault_FWD "null";
BA_ "GenSigTimeoutTime_ALL" SG_ 1096 EDS_TIGBTOvHiWarn_FWD 500;
BA_ "InvalidValue" SG_ 1096 EDS_TIGBTOvHiWarn_FWD "null";
BA_ "GenSigTimeoutTime_ALL" SG_ 1096 EDS_IOHWABSampFail_FWD 500;
BA_ "InvalidValue" SG_ 1096 EDS_IOHWABSampFail_FWD "null";
BA_ "GenSigTimeoutTime_ALL" SG_ 1096 EDS_EDSOpenFault_FWD 500;
BA_ "InvalidValue" SG_ 1096 EDS_EDSOpenFault_FWD "null";
BA_ "GenSigTimeoutTime_ALL" SG_ 1096 EDS_MotorOpenFault_FWD 500;
BA_ "InvalidValue" SG_ 1096 EDS_MotorOpenFault_FWD "null";
BA_ "GenSigTimeoutTime_ALL" SG_ 1096 EDS_EparkSampFail_FWD 500;
BA_ "InvalidValue" SG_ 1096 EDS_EparkSampFail_FWD "null";
BA_ "GenSigTimeoutTime_ALL" SG_ 1096 EDS_EmacBlkdWarn_FWD 500;
BA_ "InvalidValue" SG_ 1096 EDS_EmacBlkdWarn_FWD "null";
BA_ "GenSigTimeoutTime_ALL" SG_ 1096 EDS_VerMatchFailureErr_FWD 500;
BA_ "InvalidValue" SG_ 1096 EDS_VerMatchFailureErr_FWD "null";
BA_ "GenSigTimeoutTime_ALL" SG_ 1096 EDS_DiashCirNoPsblErr_FWD 500;
BA_ "InvalidValue" SG_ 1096 EDS_DiashCirNoPsblErr_FWD "null";
BA_ "GenSigTimeoutTime_ALL" SG_ 1096 EDS_OperOutdRngErr_FWD 500;
BA_ "InvalidValue" SG_ 1096 EDS_OperOutdRngErr_FWD "null";
BA_ "GenSigTimeoutTime_ALL" SG_ 1096 EDS_PhaseLossFaultErr_FWD 500;
BA_ "InvalidValue" SG_ 1096 EDS_PhaseLossFaultErr_FWD "null";
BA_ "GenSigTimeoutTime_ALL" SG_ 1096 EDS_CPLDFault_FWD 500;
BA_ "InvalidValue" SG_ 1096 EDS_CPLDFault_FWD "null";
BA_ "GenSigTimeoutTime_ALL" SG_ 1096 EDS_CPLDFaultBaseSpd_FWD 500;
BA_ "InvalidValue" SG_ 1096 EDS_CPLDFaultBaseSpd_FWD "null";
BA_ "GenSigTimeoutTime_ALL" SG_ 1096 EDS_IOHWABNen33Fail_FWD 500;
BA_ "InvalidValue" SG_ 1096 EDS_IOHWABNen33Fail_FWD "null";
BA_ "GenSigTimeoutTime_ALL" SG_ 1096 EDS_HvMcuSlightFault_FWD 500;
BA_ "InvalidValue" SG_ 1096 EDS_HvMcuSlightFault_FWD "null";
BA_ "GenSigTimeoutTime_ALL" SG_ 1096 EDS_HvMcuSevFault_FWD 500;
BA_ "InvalidValue" SG_ 1096 EDS_HvMcuSevFault_FWD "null";
BA_ "GenSigTimeoutTime_ALL" SG_ 1096 EDS_EDSPhaSampHWFault_FWD 500;
BA_ "InvalidValue" SG_ 1096 EDS_EDSPhaSampHWFault_FWD "null";
BA_ "GenSigTimeoutTime_ALL" SG_ 1096 EDS_IsOvHiErr_FWD 500;
BA_ "InvalidValue" SG_ 1096 EDS_IsOvHiErr_FWD "null";
BA_ "GenSigTimeoutTime_ALL" SG_ 1096 EDS_CanRollingCounterErr_FWD 500;
BA_ "InvalidValue" SG_ 1096 EDS_CanRollingCounterErr_FWD "null";
BA_ "GenSigTimeoutTime_ALL" SG_ 1096 EDS_CanTimeoutErr_FWD 500;
BA_ "InvalidValue" SG_ 1096 EDS_CanTimeoutErr_FWD "null";
BA_ "GenSigTimeoutTime_ALL" SG_ 1096 EDS_CrashFault_FWD 500;
BA_ "InvalidValue" SG_ 1096 EDS_CrashFault_FWD "null";
BA_ "GenSigTimeoutTime_ALL" SG_ 1096 EDS_PCFSlightFault_FWD 500;
BA_ "InvalidValue" SG_ 1096 EDS_PCFSlightFault_FWD "null";
BA_ "GenSigTimeoutTime_ALL" SG_ 1096 EDS_PCFSerFault_FWD 500;
BA_ "InvalidValue" SG_ 1096 EDS_PCFSerFault_FWD "null";
BA_ "GenSigTimeoutTime_ALL" SG_ 1096 SECCAN_EDS_Error_FR_B 500;
BA_ "InvalidValue" SG_ 1096 SECCAN_EDS_Error_FR_B "null";
BA_ "GenSigTimeoutTime_ALL" SG_ 1097 CHKSM_EDS_Error_RR_B 500;
BA_ "InvalidValue" SG_ 1097 CHKSM_EDS_Error_RR_B "null";
BA_ "GenSigTimeoutTime_ALL" SG_ 1097 ALV_EDS_Error_RR_B 500;
BA_ "InvalidValue" SG_ 1097 ALV_EDS_Error_RR_B "Fh";
BA_ "GenSigTimeoutTime_ALL" SG_ 1097 EDS_iDcLnkOvCLimFail_RWD 500;
BA_ "InvalidValue" SG_ 1097 EDS_iDcLnkOvCLimFail_RWD "null";
BA_ "GenSigTimeoutTime_ALL" SG_ 1097 EDS_MotBlockedFault_RWD 500;
BA_ "InvalidValue" SG_ 1097 EDS_MotBlockedFault_RWD "null";
BA_ "GenSigTimeoutTime_ALL" SG_ 1097 EDS_RSLErr_RWD 500;
BA_ "InvalidValue" SG_ 1097 EDS_RSLErr_RWD "null";
BA_ "GenSigTimeoutTime_ALL" SG_ 1097 EDS_MotTrqLimFault_RWD 500;
BA_ "InvalidValue" SG_ 1097 EDS_MotTrqLimFault_RWD "null";
BA_ "GenSigTimeoutTime_ALL" SG_ 1097 EDS_VCUChksumFault_RWD 500;
BA_ "InvalidValue" SG_ 1097 EDS_VCUChksumFault_RWD "null";
BA_ "GenSigTimeoutTime_ALL" SG_ 1097 EDS_IGBTFault_RWD 500;
BA_ "InvalidValue" SG_ 1097 EDS_IGBTFault_RWD "null";
BA_ "GenSigTimeoutTime_ALL" SG_ 1097 EDS_CANBusoffFault_RWD 500;
BA_ "InvalidValue" SG_ 1097 EDS_CANBusoffFault_RWD "null";
BA_ "GenSigTimeoutTime_ALL" SG_ 1097 EDS_TDrvBoardOvHiWarn_RWD 500;
BA_ "InvalidValue" SG_ 1097 EDS_TDrvBoardOvHiWarn_RWD "null";
BA_ "GenSigTimeoutTime_ALL" SG_ 1097 EDS_TIGBTOvHiFault_RWD 500;
BA_ "InvalidValue" SG_ 1097 EDS_TIGBTOvHiFault_RWD "null";
BA_ "GenSigTimeoutTime_ALL" SG_ 1097 EDS_TIGBTOvHiWarn_RWD 500;
BA_ "InvalidValue" SG_ 1097 EDS_TIGBTOvHiWarn_RWD "null";
BA_ "GenSigTimeoutTime_ALL" SG_ 1097 EDS_IOHWABSampFail_RWD 500;
BA_ "InvalidValue" SG_ 1097 EDS_IOHWABSampFail_RWD "null";
BA_ "GenSigTimeoutTime_ALL" SG_ 1097 EDS_EDSOpenFault_RWD 500;
BA_ "InvalidValue" SG_ 1097 EDS_EDSOpenFault_RWD "null";
BA_ "GenSigTimeoutTime_ALL" SG_ 1097 EDS_MotorOpenFault_RWD 500;
BA_ "InvalidValue" SG_ 1097 EDS_MotorOpenFault_RWD "null";
BA_ "GenSigTimeoutTime_ALL" SG_ 1097 EDS_EparkSampFail_RWD 500;
BA_ "InvalidValue" SG_ 1097 EDS_EparkSampFail_RWD "null";
BA_ "GenSigTimeoutTime_ALL" SG_ 1097 EDS_EmacBlkdWarn_RWD 500;
BA_ "InvalidValue" SG_ 1097 EDS_EmacBlkdWarn_RWD "null";
BA_ "GenSigTimeoutTime_ALL" SG_ 1097 EDS_VerMatchFailureErr_RWD 500;
BA_ "InvalidValue" SG_ 1097 EDS_VerMatchFailureErr_RWD "null";
BA_ "GenSigTimeoutTime_ALL" SG_ 1097 EDS_DiashCirNoPsblErr_RWD 500;
BA_ "InvalidValue" SG_ 1097 EDS_DiashCirNoPsblErr_RWD "null";
BA_ "GenSigTimeoutTime_ALL" SG_ 1097 EDS_OperOutdRngErr_RWD 500;
BA_ "InvalidValue" SG_ 1097 EDS_OperOutdRngErr_RWD "null";
BA_ "GenSigTimeoutTime_ALL" SG_ 1097 EDS_PhaseLossFaultErr_RWD 500;
BA_ "InvalidValue" SG_ 1097 EDS_PhaseLossFaultErr_RWD "null";
BA_ "GenSigTimeoutTime_ALL" SG_ 1097 EDS_CPLDFault_RWD 500;
BA_ "InvalidValue" SG_ 1097 EDS_CPLDFault_RWD "null";
BA_ "GenSigTimeoutTime_ALL" SG_ 1097 EDS_CPLDFaultBaseSpd_RWD 500;
BA_ "InvalidValue" SG_ 1097 EDS_CPLDFaultBaseSpd_RWD "null";
BA_ "GenSigTimeoutTime_ALL" SG_ 1097 EDS_IOHWABNen33Fail_RWD 500;
BA_ "InvalidValue" SG_ 1097 EDS_IOHWABNen33Fail_RWD "null";
BA_ "GenSigTimeoutTime_ALL" SG_ 1097 EDS_HvMcuSlightFault_RWD 500;
BA_ "InvalidValue" SG_ 1097 EDS_HvMcuSlightFault_RWD "null";
BA_ "GenSigTimeoutTime_ALL" SG_ 1097 EDS_HvMcuSevFault_RWD 500;
BA_ "InvalidValue" SG_ 1097 EDS_HvMcuSevFault_RWD "null";
BA_ "GenSigTimeoutTime_ALL" SG_ 1097 EDS_EDSPhaSampHWFault_RWD 500;
BA_ "InvalidValue" SG_ 1097 EDS_EDSPhaSampHWFault_RWD "null";
BA_ "GenSigTimeoutTime_ALL" SG_ 1097 EDS_IsOvHiErr_RWD 500;
BA_ "InvalidValue" SG_ 1097 EDS_IsOvHiErr_RWD "null";
BA_ "GenSigTimeoutTime_ALL" SG_ 1097 EDS_CanRollingCounterErr_RWD 500;
BA_ "InvalidValue" SG_ 1097 EDS_CanRollingCounterErr_RWD "null";
BA_ "GenSigTimeoutTime_ALL" SG_ 1097 EDS_CanTimeoutErr_RWD 500;
BA_ "InvalidValue" SG_ 1097 EDS_CanTimeoutErr_RWD "null";
BA_ "GenSigTimeoutTime_ALL" SG_ 1097 EDS_CrashFault_RWD 500;
BA_ "InvalidValue" SG_ 1097 EDS_CrashFault_RWD "null";
BA_ "GenSigTimeoutTime_ALL" SG_ 1097 EDS_PCFSlightFault_RWD 500;
BA_ "InvalidValue" SG_ 1097 EDS_PCFSlightFault_RWD "null";
BA_ "GenSigTimeoutTime_ALL" SG_ 1097 EDS_PCFSerFault_RWD 500;
BA_ "InvalidValue" SG_ 1097 EDS_PCFSerFault_RWD "null";
BA_ "GenSigTimeoutTime_ALL" SG_ 1097 SECCAN_EDS_Error_RR_B 500;
BA_ "InvalidValue" SG_ 1097 SECCAN_EDS_Error_RR_B "null";
BA_ "GenSigSendType" SG_ 1104 MHU_SET_WindowLifterFrontL 2;
BA_ "InvalidValue" SG_ 1104 MHU_SET_WindowLifterFrontL "7h";
BA_ "GenSigSendType" SG_ 1104 MHU_SET_WindowLifterFrontR 2;
BA_ "InvalidValue" SG_ 1104 MHU_SET_WindowLifterFrontR "7h";
BA_ "GenSigSendType" SG_ 1104 MHU_SET_WindowLifterRearL 2;
BA_ "InvalidValue" SG_ 1104 MHU_SET_WindowLifterRearL "7h";
BA_ "GenSigSendType" SG_ 1104 MHU_SET_WindowLifterRearR 2;
BA_ "InvalidValue" SG_ 1104 MHU_SET_WindowLifterRearR "7h";
BA_ "GenSigSendType" SG_ 1104 MHU_SET_WindowAutoClose 2;
BA_ "InvalidValue" SG_ 1104 MHU_SET_WindowAutoClose "3h";
BA_ "GenSigTimeoutTime_ALL" SG_ 1105 Checksum_RSSI 1000;
BA_ "InvalidValue" SG_ 1105 Checksum_RSSI "null";
BA_ "GenSigTimeoutTime_ALL" SG_ 1105 Rolling_Counter_RSSI 1000;
BA_ "InvalidValue" SG_ 1105 Rolling_Counter_RSSI "Fh";
BA_ "GenSigTimeoutTime_ALL" SG_ 1105 RSSI_Value 1000;
BA_ "InvalidValue" SG_ 1105 RSSI_Value "Fh";
BA_ "GenSigTimeoutTime_ALL" SG_ 1105 SECCAN_RSSI 1000;
BA_ "GenSigTimeoutTime_ALL" SG_ 1106 MHU_SET_ANN1_MODE 500;
BA_ "InvalidValue" SG_ 1106 MHU_SET_ANN1_MODE "null";
BA_ "GenSigTimeoutTime_ALL" SG_ 1107 MHU_SET_ANN1_PROMPTS_SPEAKER 500;
BA_ "InvalidValue" SG_ 1107 MHU_SET_ANN1_PROMPTS_SPEAKER "null";
BA_ "GenSigTimeoutTime_ALL" SG_ 1108 MHU_SET_ANN2_CEN_Mute 500;
BA_ "InvalidValue" SG_ 1108 MHU_SET_ANN2_CEN_Mute "0";
BA_ "GenSigTimeoutTime_ALL" SG_ 1108 MHU_SET_ANN2_RR_Mute 500;
BA_ "InvalidValue" SG_ 1108 MHU_SET_ANN2_RR_Mute "0";
BA_ "GenSigTimeoutTime_ALL" SG_ 1108 MHU_SET_ANN2_RL_Mute 500;
BA_ "InvalidValue" SG_ 1108 MHU_SET_ANN2_RL_Mute "0";
BA_ "GenSigTimeoutTime_ALL" SG_ 1108 MHU_SET_ANN2_FR_Mute 500;
BA_ "InvalidValue" SG_ 1108 MHU_SET_ANN2_FR_Mute "0";
BA_ "GenSigTimeoutTime_ALL" SG_ 1108 MHU_SET_ANN2_FL_Mute 500;
BA_ "InvalidValue" SG_ 1108 MHU_SET_ANN2_FL_Mute "0";
BA_ "GenSigStartValue" SG_ 1109 AMP_SET_Mediavolume 15;
BA_ "GenSigTimeoutTime_ALL" SG_ 1109 AMP_SET_Mediavolume 500;
BA_ "InvalidValue" SG_ 1109 AMP_SET_Mediavolume "FFh";
BA_ "GenSigTimeoutTime_ALL" SG_ 1109 AMP_SET_Soundzone 500;
BA_ "InvalidValue" SG_ 1109 AMP_SET_Soundzone "0";
BA_ "GenSigTimeoutTime_ALL" SG_ 1109 AMP_SET_Bass 500;
BA_ "InvalidValue" SG_ 1109 AMP_SET_Bass "1Fh";
BA_ "GenSigTimeoutTime_ALL" SG_ 1109 AMP_SET_Fader 500;
BA_ "InvalidValue" SG_ 1109 AMP_SET_Fader "1Fh";
BA_ "GenSigTimeoutTime_ALL" SG_ 1109 AMP_SET_MediaMute 500;
BA_ "InvalidValue" SG_ 1109 AMP_SET_MediaMute "3h";
BA_ "GenSigTimeoutTime_ALL" SG_ 1109 AMP_SET_MidPitch 500;
BA_ "InvalidValue" SG_ 1109 AMP_SET_MidPitch "1Fh";
BA_ "GenSigTimeoutTime_ALL" SG_ 1109 AMP_SET_Treble 500;
BA_ "InvalidValue" SG_ 1109 AMP_SET_Treble "1Fh";
BA_ "GenSigTimeoutTime_ALL" SG_ 1109 AMP_SET_Balance 500;
BA_ "InvalidValue" SG_ 1109 AMP_SET_Balance "1Fh";
BA_ "GenSigSendType" SG_ 1110 OP_WISW_SZL_LIN 3;
BA_ "InvalidValue" SG_ 1110 OP_WISW_SZL_LIN "null";
BA_ "GenSigSendType" SG_ 1110 COMM_ERR_SZL_LIN 3;
BA_ "InvalidValue" SG_ 1110 COMM_ERR_SZL_LIN "null";
BA_ "GenSigSendType" SG_ 1110 BCM_Wiper_Front_Status 3;
BA_ "InvalidValue" SG_ 1110 BCM_Wiper_Front_Status "null";
BA_ "GenSigSendType" SG_ 1110 OP_WIPO_SZL_LIN 3;
BA_ "InvalidValue" SG_ 1110 OP_WIPO_SZL_LIN "null";
BA_ "GenSigSendType" SG_ 1110 OP_COLS_SZL_LIN 3;
BA_ "InvalidValue" SG_ 1110 OP_COLS_SZL_LIN "null";
BA_ "GenSigSendType" SG_ 1110 NOD_ERR_SZL_LIN 3;
BA_ "InvalidValue" SG_ 1110 NOD_ERR_SZL_LIN "null";
BA_ "GenSigSendType" SG_ 1110 BCM_Wiper_Rear_Status 3;
BA_ "InvalidValue" SG_ 1110 BCM_Wiper_Rear_Status "3h";
BA_ "InvalidValue" SG_ 1110 BCM_Wiper_Rear_Status "null";
BA_ "GenSigSendType" SG_ 1110 ALIV_WISW_SZL_LIN 3;
BA_ "InvalidValue" SG_ 1110 ALIV_WISW_SZL_LIN "Fh";
BA_ "GenSigSendType" SG_ 1111 AmbLight_Error_Z5 3;
BA_ "InvalidValue" SG_ 1111 AmbLight_Error_Z5 "null";
BA_ "GenSigSendType" SG_ 1111 AmbLight_Error_Z4 3;
BA_ "InvalidValue" SG_ 1111 AmbLight_Error_Z4 "null";
BA_ "GenSigSendType" SG_ 1111 AmbLight_Error_Z3 3;
BA_ "InvalidValue" SG_ 1111 AmbLight_Error_Z3 "null";
BA_ "GenSigSendType" SG_ 1111 AmbLight_Error_Z2 3;
BA_ "InvalidValue" SG_ 1111 AmbLight_Error_Z2 "null";
BA_ "GenSigSendType" SG_ 1111 AmbLight_Error_Z1 3;
BA_ "InvalidValue" SG_ 1111 AmbLight_Error_Z1 "null";
BA_ "GenSigSendType" SG_ 1112 AmbLightColorZoneReq 2;
BA_ "InvalidValue" SG_ 1112 AmbLightColorZoneReq "null";
BA_ "GenSigSendType" SG_ 1112 AmbLightColorRed 2;
BA_ "InvalidValue" SG_ 1112 AmbLightColorRed "null";
BA_ "GenSigSendType" SG_ 1112 AmbLightColorGreen 2;
BA_ "InvalidValue" SG_ 1112 AmbLightColorGreen "null";
BA_ "GenSigSendType" SG_ 1112 AmbLightColorBlue 2;
BA_ "InvalidValue" SG_ 1112 AmbLightColorBlue "null";
BA_ "GenSigSendType" SG_ 1112 SECCAN_BCM_Clr_Rq 2;
BA_ "InvalidValue" SG_ 1112 SECCAN_BCM_Clr_Rq "null";
BA_ "GenSigSendType" SG_ 1113 AmbLightIntensityTimingZoneReq 2;
BA_ "InvalidValue" SG_ 1113 AmbLightIntensityTimingZoneReq "null";
BA_ "GenSigSendType" SG_ 1113 AmbLightIntensityTimingTypeReq 2;
BA_ "InvalidValue" SG_ 1113 AmbLightIntensityTimingTypeReq "null";
BA_ "GenSigSendType" SG_ 1113 AmbLightIntenTimingBrightReq 2;
BA_ "InvalidValue" SG_ 1113 AmbLightIntenTimingBrightReq "null";
BA_ "GenSigSendType" SG_ 1113 AmbLightIntensityTimingT1Req 2;
BA_ "InvalidValue" SG_ 1113 AmbLightIntensityTimingT1Req "null";
BA_ "GenSigSendType" SG_ 1113 AmbLightIntensityTimingT2Req 2;
BA_ "InvalidValue" SG_ 1113 AmbLightIntensityTimingT2Req "null";
BA_ "GenSigSendType" SG_ 1113 AmbLightIntensityTimingT3Req 2;
BA_ "InvalidValue" SG_ 1113 AmbLightIntensityTimingT3Req "null";
BA_ "GenSigSendType" SG_ 1113 AmbLightIntensityTimingT4Req 2;
BA_ "InvalidValue" SG_ 1113 AmbLightIntensityTimingT4Req "null";
BA_ "GenSigSendType" SG_ 1113 AmbLightIntensityTimingN2Req 2;
BA_ "InvalidValue" SG_ 1113 AmbLightIntensityTimingN2Req "null";
BA_ "GenSigSendType" SG_ 1113 AmbLightIntensityTimingN1Req 2;
BA_ "InvalidValue" SG_ 1113 AmbLightIntensityTimingN1Req "null";
BA_ "GenSigTimeoutTime_ALL" SG_ 1124 LDML_LampAssemblySts 500;
BA_ "InvalidValue" SG_ 1124 LDML_LampAssemblySts "3h";
BA_ "GenSigTimeoutTime_ALL" SG_ 1124 LDML_PosLmpSts 500;
BA_ "InvalidValue" SG_ 1124 LDML_PosLmpSts "3h";
BA_ "GenSigTimeoutTime_ALL" SG_ 1124 LDML_ControllerSts 500;
BA_ "InvalidValue" SG_ 1124 LDML_ControllerSts "3h";
BA_ "GenSigTimeoutTime_ALL" SG_ 1124 LDML_TurnIndicatorSts 500;
BA_ "InvalidValue" SG_ 1124 LDML_TurnIndicatorSts "3h";
BA_ "GenSigTimeoutTime_ALL" SG_ 1124 LDML_AuxLBSts 500;
BA_ "InvalidValue" SG_ 1124 LDML_AuxLBSts "3h";
BA_ "GenSigTimeoutTime_ALL" SG_ 1124 LDML_LowBeamSts 500;
BA_ "InvalidValue" SG_ 1124 LDML_LowBeamSts "3h";
BA_ "GenSigTimeoutTime_ALL" SG_ 1124 LDML_HighBeamSts 500;
BA_ "InvalidValue" SG_ 1124 LDML_HighBeamSts "3h";
BA_ "GenSigTimeoutTime_ALL" SG_ 1124 LDML_DayRunningLampSts 500;
BA_ "InvalidValue" SG_ 1124 LDML_DayRunningLampSts "3h";
BA_ "GenSigTimeoutTime_ALL" SG_ 1124 LDML_DayTimeRunningLightFbSts 500;
BA_ "InvalidValue" SG_ 1124 LDML_DayTimeRunningLightFbSts "3h";
BA_ "GenSigTimeoutTime_ALL" SG_ 1124 LDML_AutoLvlFbSts 500;
BA_ "InvalidValue" SG_ 1124 LDML_AutoLvlFbSts "3h";
BA_ "GenSigTimeoutTime_ALL" SG_ 1124 LDML_AdptvDrvBeamFbSts 500;
BA_ "InvalidValue" SG_ 1124 LDML_AdptvDrvBeamFbSts "3h";
BA_ "GenSigTimeoutTime_ALL" SG_ 1124 LDML_AuxHBSts 500;
BA_ "InvalidValue" SG_ 1124 LDML_AuxHBSts "3h";
BA_ "GenSigTimeoutTime_ALL" SG_ 1124 LDML_FollowMeHomeFbSts 500;
BA_ "InvalidValue" SG_ 1124 LDML_FollowMeHomeFbSts "5h";
BA_ "GenSigTimeoutTime_ALL" SG_ 1124 LDML_ExteriorLightFbSts 500;
BA_ "InvalidValue" SG_ 1124 LDML_ExteriorLightFbSts "4h";
BA_ "GenSigStartValue" SG_ 1124 LDML_AHB_ICON_Feed 3;
BA_ "GenSigTimeoutTime_ALL" SG_ 1124 LDML_AHB_ICON_Feed 500;
BA_ "InvalidValue" SG_ 1124 LDML_AHB_ICON_Feed "3h";
BA_ "GenSigTimeoutTime_ALL" SG_ 1125 LDMR_LampAssemblySts 500;
BA_ "InvalidValue" SG_ 1125 LDMR_LampAssemblySts "3h";
BA_ "GenSigTimeoutTime_ALL" SG_ 1125 LDMR_PosLmpSts 500;
BA_ "InvalidValue" SG_ 1125 LDMR_PosLmpSts "3h";
BA_ "GenSigTimeoutTime_ALL" SG_ 1125 LDMR_ControllerSts 500;
BA_ "InvalidValue" SG_ 1125 LDMR_ControllerSts "3h";
BA_ "GenSigTimeoutTime_ALL" SG_ 1125 LDMR_TurnIndicatorSts 500;
BA_ "InvalidValue" SG_ 1125 LDMR_TurnIndicatorSts "3h";
BA_ "GenSigTimeoutTime_ALL" SG_ 1125 LDMR_AuxLBSts 500;
BA_ "InvalidValue" SG_ 1125 LDMR_AuxLBSts "3h";
BA_ "GenSigTimeoutTime_ALL" SG_ 1125 LDMR_LowBeamSts 500;
BA_ "InvalidValue" SG_ 1125 LDMR_LowBeamSts "3h";
BA_ "GenSigTimeoutTime_ALL" SG_ 1125 LDMR_HighBeamSts 500;
BA_ "InvalidValue" SG_ 1125 LDMR_HighBeamSts "3h";
BA_ "GenSigTimeoutTime_ALL" SG_ 1125 LDMR_DayRunningLampSts 500;
BA_ "InvalidValue" SG_ 1125 LDMR_DayRunningLampSts "3h";
BA_ "GenSigTimeoutTime_ALL" SG_ 1125 LDMR_DayTimeRunningLightFbSts 500;
BA_ "InvalidValue" SG_ 1125 LDMR_DayTimeRunningLightFbSts "3h";
BA_ "GenSigTimeoutTime_ALL" SG_ 1125 LDMR_AutoLvlFbSts 500;
BA_ "InvalidValue" SG_ 1125 LDMR_AutoLvlFbSts "3h";
BA_ "GenSigTimeoutTime_ALL" SG_ 1125 LDMR_AdptvDrvBeamFbSts 500;
BA_ "InvalidValue" SG_ 1125 LDMR_AdptvDrvBeamFbSts "3h";
BA_ "GenSigTimeoutTime_ALL" SG_ 1125 LDMR_AuxHBSts 500;
BA_ "InvalidValue" SG_ 1125 LDMR_AuxHBSts "3h";
BA_ "GenSigTimeoutTime_ALL" SG_ 1125 LDMR_FollowMeHomeFbSts 500;
BA_ "InvalidValue" SG_ 1125 LDMR_FollowMeHomeFbSts "5h";
BA_ "GenSigTimeoutTime_ALL" SG_ 1125 LDMR_ExteriorLightFbSts 500;
BA_ "InvalidValue" SG_ 1125 LDMR_ExteriorLightFbSts "4h";
BA_ "GenSigStartValue" SG_ 1125 LDMR_AHB_ICON_Feed 3;
BA_ "GenSigTimeoutTime_ALL" SG_ 1125 LDMR_AHB_ICON_Feed 500;
BA_ "InvalidValue" SG_ 1125 LDMR_AHB_ICON_Feed "3h";
BA_ "GenSigTimeoutTime_ALL" SG_ 1136 AMP_SET_ANN1_MODE 500;
BA_ "InvalidValue" SG_ 1136 AMP_SET_ANN1_MODE "null";
BA_ "GenSigTimeoutTime_ALL" SG_ 1137 AMP_SET_ANN1_PROMPTS_SPEAKER 500;
BA_ "InvalidValue" SG_ 1137 AMP_SET_ANN1_PROMPTS_SPEAKER "null";
BA_ "GenSigTimeoutTime_ALL" SG_ 1138 AMP_SET_ANN2_CEN_Mute 500;
BA_ "InvalidValue" SG_ 1138 AMP_SET_ANN2_CEN_Mute "null";
BA_ "GenSigTimeoutTime_ALL" SG_ 1138 AMP_SET_ANN2_RR_Mute 500;
BA_ "InvalidValue" SG_ 1138 AMP_SET_ANN2_RR_Mute "null";
BA_ "GenSigTimeoutTime_ALL" SG_ 1138 AMP_SET_ANN2_RL_Mute 500;
BA_ "InvalidValue" SG_ 1138 AMP_SET_ANN2_RL_Mute "null";
BA_ "GenSigTimeoutTime_ALL" SG_ 1138 AMP_SET_ANN2_FR_Mute 500;
BA_ "InvalidValue" SG_ 1138 AMP_SET_ANN2_FR_Mute "null";
BA_ "GenSigTimeoutTime_ALL" SG_ 1138 AMP_SET_ANN2_FL_Mute 500;
BA_ "InvalidValue" SG_ 1138 AMP_SET_ANN2_FL_Mute "null";
BA_ "GenSigSendType" SG_ 1152 CHKSM_PSM_WARNING_MSG 3;
BA_ "GenSigTimeoutTime_ALL" SG_ 1152 CHKSM_PSM_WARNING_MSG 5000;
BA_ "InvalidValue" SG_ 1152 CHKSM_PSM_WARNING_MSG "null";
BA_ "GenSigSendType" SG_ 1152 ALV_PSM_WARNING_MSG 3;
BA_ "GenSigTimeoutTime_ALL" SG_ 1152 ALV_PSM_WARNING_MSG 5000;
BA_ "InvalidValue" SG_ 1152 ALV_PSM_WARNING_MSG "Fh";
BA_ "GenSigSendType" SG_ 1152 PSM_DrvSeatMissalignment 4;
BA_ "GenSigTimeoutTime_ALL" SG_ 1152 PSM_DrvSeatMissalignment 5000;
BA_ "InvalidValue" SG_ 1152 PSM_DrvSeatMissalignment "null";
BA_ "GenSigSendType" SG_ 1152 PSM_PasSeatMisalignment 4;
BA_ "GenSigTimeoutTime_ALL" SG_ 1152 PSM_PasSeatMisalignment 5000;
BA_ "InvalidValue" SG_ 1152 PSM_PasSeatMisalignment "null";
BA_ "GenSigSendType" SG_ 1152 PSM_WflagRes3 4;
BA_ "GenSigTimeoutTime_ALL" SG_ 1152 PSM_WflagRes3 5000;
BA_ "InvalidValue" SG_ 1152 PSM_WflagRes3 "null";
BA_ "GenSigSendType" SG_ 1152 PSM_WflagRes4 4;
BA_ "GenSigTimeoutTime_ALL" SG_ 1152 PSM_WflagRes4 5000;
BA_ "InvalidValue" SG_ 1152 PSM_WflagRes4 "3h";
BA_ "GenSigSendType" SG_ 1152 PSM_WflagRes5 4;
BA_ "GenSigTimeoutTime_ALL" SG_ 1152 PSM_WflagRes5 5000;
BA_ "InvalidValue" SG_ 1152 PSM_WflagRes5 "null";
BA_ "GenSigSendType" SG_ 1152 PSM_WflagRes6 4;
BA_ "GenSigTimeoutTime_ALL" SG_ 1152 PSM_WflagRes6 5000;
BA_ "InvalidValue" SG_ 1152 PSM_WflagRes6 "null";
BA_ "GenSigSendType" SG_ 1152 PSM_WflagRes7 4;
BA_ "GenSigTimeoutTime_ALL" SG_ 1152 PSM_WflagRes7 5000;
BA_ "InvalidValue" SG_ 1152 PSM_WflagRes7 "null";
BA_ "GenSigSendType" SG_ 1152 PSM_WflagRes8 4;
BA_ "GenSigTimeoutTime_ALL" SG_ 1152 PSM_WflagRes8 5000;
BA_ "InvalidValue" SG_ 1152 PSM_WflagRes8 "null";
BA_ "GenSigSendType" SG_ 1152 PSM_WflagRes9 4;
BA_ "GenSigTimeoutTime_ALL" SG_ 1152 PSM_WflagRes9 5000;
BA_ "InvalidValue" SG_ 1152 PSM_WflagRes9 "null";
BA_ "GenSigSendType" SG_ 1152 PSM_WflagRes10 4;
BA_ "GenSigTimeoutTime_ALL" SG_ 1152 PSM_WflagRes10 5000;
BA_ "InvalidValue" SG_ 1152 PSM_WflagRes10 "null";
BA_ "GenSigSendType" SG_ 1152 PSM_WflagRes11 4;
BA_ "GenSigTimeoutTime_ALL" SG_ 1152 PSM_WflagRes11 5000;
BA_ "InvalidValue" SG_ 1152 PSM_WflagRes11 "null";
BA_ "GenSigSendType" SG_ 1152 PSM_WflagRes12 4;
BA_ "GenSigTimeoutTime_ALL" SG_ 1152 PSM_WflagRes12 5000;
BA_ "InvalidValue" SG_ 1152 PSM_WflagRes12 "null";
BA_ "GenSigSendType" SG_ 1153 CHSKM_BCM_WarnMsg 3;
BA_ "GenSigTimeoutTime_ALL" SG_ 1153 CHSKM_BCM_WarnMsg 5000;
BA_ "InvalidValue" SG_ 1153 CHSKM_BCM_WarnMsg "-";
BA_ "GenSigSendType" SG_ 1153 ALV_BCM_WarnMsg 3;
BA_ "GenSigTimeoutTime_ALL" SG_ 1153 ALV_BCM_WarnMsg 5000;
BA_ "InvalidValue" SG_ 1153 ALV_BCM_WarnMsg "Fh";
BA_ "GenSigSendType" SG_ 1153 BCM_NoValidKey_1 4;
BA_ "GenSigTimeoutTime_ALL" SG_ 1153 BCM_NoValidKey_1 5000;
BA_ "InvalidValue" SG_ 1153 BCM_NoValidKey_1 "-";
BA_ "GenSigSendType" SG_ 1153 BCM_SSB_defect 4;
BA_ "GenSigTimeoutTime_ALL" SG_ 1153 BCM_SSB_defect 5000;
BA_ "InvalidValue" SG_ 1153 BCM_SSB_defect "-";
BA_ "GenSigSendType" SG_ 1153 BCM_WrongGearPosToStart 4;
BA_ "GenSigTimeoutTime_ALL" SG_ 1153 BCM_WrongGearPosToStart 5000;
BA_ "InvalidValue" SG_ 1153 BCM_WrongGearPosToStart "-";
BA_ "GenSigSendType" SG_ 1153 BCM_NoValidKey_2 4;
BA_ "GenSigTimeoutTime_ALL" SG_ 1153 BCM_NoValidKey_2 5000;
BA_ "InvalidValue" SG_ 1153 BCM_NoValidKey_2 "-";
BA_ "GenSigSendType" SG_ 1153 BCM_PressBrakeToStart 4;
BA_ "GenSigTimeoutTime_ALL" SG_ 1153 BCM_PressBrakeToStart 5000;
BA_ "InvalidValue" SG_ 1153 BCM_PressBrakeToStart "-";
BA_ "GenSigSendType" SG_ 1153 BCM_TurnOffPosLightRemindr 4;
BA_ "GenSigTimeoutTime_ALL" SG_ 1153 BCM_TurnOffPosLightRemindr 5000;
BA_ "InvalidValue" SG_ 1153 BCM_TurnOffPosLightRemindr "-";
BA_ "GenSigSendType" SG_ 1153 BCM_KeyFob_LowBattery 4;
BA_ "GenSigTimeoutTime_ALL" SG_ 1153 BCM_KeyFob_LowBattery 5000;
BA_ "InvalidValue" SG_ 1153 BCM_KeyFob_LowBattery "-";
BA_ "GenSigSendType" SG_ 1153 BCM_StopLightDefect 4;
BA_ "GenSigTimeoutTime_ALL" SG_ 1153 BCM_StopLightDefect 5000;
BA_ "InvalidValue" SG_ 1153 BCM_StopLightDefect "-";
BA_ "GenSigSendType" SG_ 1153 BCM_LowBeamDefect 4;
BA_ "GenSigTimeoutTime_ALL" SG_ 1153 BCM_LowBeamDefect 5000;
BA_ "InvalidValue" SG_ 1153 BCM_LowBeamDefect "-";
BA_ "GenSigSendType" SG_ 1153 BCM_HighBeamDefect 4;
BA_ "GenSigTimeoutTime_ALL" SG_ 1153 BCM_HighBeamDefect 5000;
BA_ "InvalidValue" SG_ 1153 BCM_HighBeamDefect "-";
BA_ "GenSigSendType" SG_ 1153 BCM_PositionLightDefect 4;
BA_ "GenSigTimeoutTime_ALL" SG_ 1153 BCM_PositionLightDefect 5000;
BA_ "InvalidValue" SG_ 1153 BCM_PositionLightDefect "-";
BA_ "GenSigSendType" SG_ 1153 BCM_CHMLS_Defect 4;
BA_ "GenSigTimeoutTime_ALL" SG_ 1153 BCM_CHMLS_Defect 5000;
BA_ "InvalidValue" SG_ 1153 BCM_CHMLS_Defect "-";
BA_ "GenSigSendType" SG_ 1153 BCM_LicencePlateLight_Defect 4;
BA_ "GenSigTimeoutTime_ALL" SG_ 1153 BCM_LicencePlateLight_Defect 5000;
BA_ "InvalidValue" SG_ 1153 BCM_LicencePlateLight_Defect "-";
BA_ "GenSigSendType" SG_ 1153 BCM_FrontFog_Defect 4;
BA_ "GenSigTimeoutTime_ALL" SG_ 1153 BCM_FrontFog_Defect 5000;
BA_ "InvalidValue" SG_ 1153 BCM_FrontFog_Defect "-";
BA_ "GenSigSendType" SG_ 1153 BCM_RearFog_Defect 4;
BA_ "GenSigTimeoutTime_ALL" SG_ 1153 BCM_RearFog_Defect 5000;
BA_ "InvalidValue" SG_ 1153 BCM_RearFog_Defect "-";
BA_ "GenSigSendType" SG_ 1153 BCM_ReverseLightDefect 4;
BA_ "GenSigTimeoutTime_ALL" SG_ 1153 BCM_ReverseLightDefect 5000;
BA_ "InvalidValue" SG_ 1153 BCM_ReverseLightDefect "-";
BA_ "GenSigSendType" SG_ 1153 BCM_RLS_Malfunction 4;
BA_ "GenSigTimeoutTime_ALL" SG_ 1153 BCM_RLS_Malfunction 5000;
BA_ "InvalidValue" SG_ 1153 BCM_RLS_Malfunction "-";
BA_ "GenSigSendType" SG_ 1153 BCM_12VBattery_LowLevel 4;
BA_ "GenSigTimeoutTime_ALL" SG_ 1153 BCM_12VBattery_LowLevel 5000;
BA_ "InvalidValue" SG_ 1153 BCM_12VBattery_LowLevel "-";
BA_ "GenSigSendType" SG_ 1153 BCM_ForgetKeyFOBInCar 4;
BA_ "GenSigTimeoutTime_ALL" SG_ 1153 BCM_ForgetKeyFOBInCar 5000;
BA_ "InvalidValue" SG_ 1153 BCM_ForgetKeyFOBInCar "-";
BA_ "GenSigSendType" SG_ 1153 BCM_12VBattery_Discharging 4;
BA_ "GenSigTimeoutTime_ALL" SG_ 1153 BCM_12VBattery_Discharging 5000;
BA_ "InvalidValue" SG_ 1153 BCM_12VBattery_Discharging "-";
BA_ "GenSigSendType" SG_ 1153 BCM_TurnIndicatorDefect 4;
BA_ "GenSigTimeoutTime_ALL" SG_ 1153 BCM_TurnIndicatorDefect 5000;
BA_ "InvalidValue" SG_ 1153 BCM_TurnIndicatorDefect "-";
BA_ "GenSigSendType" SG_ 1153 BCM_dTPMS_Malfunc 4;
BA_ "GenSigTimeoutTime_ALL" SG_ 1153 BCM_dTPMS_Malfunc 5000;
BA_ "InvalidValue" SG_ 1153 BCM_dTPMS_Malfunc "-";
BA_ "GenSigSendType" SG_ 1153 BCM_dTPMS_Malfunc_LostSensor 4;
BA_ "GenSigTimeoutTime_ALL" SG_ 1153 BCM_dTPMS_Malfunc_LostSensor 5000;
BA_ "InvalidValue" SG_ 1153 BCM_dTPMS_Malfunc_LostSensor "-";
BA_ "GenSigSendType" SG_ 1153 BCM_dTPMS_LowPressure 4;
BA_ "GenSigTimeoutTime_ALL" SG_ 1153 BCM_dTPMS_LowPressure 5000;
BA_ "InvalidValue" SG_ 1153 BCM_dTPMS_LowPressure "-";
BA_ "GenSigSendType" SG_ 1153 BCM_dTPMS_RapidLeak 4;
BA_ "GenSigTimeoutTime_ALL" SG_ 1153 BCM_dTPMS_RapidLeak 5000;
BA_ "InvalidValue" SG_ 1153 BCM_dTPMS_RapidLeak "-";
BA_ "GenSigSendType" SG_ 1153 BCM_dTPMS_HighTemperature 4;
BA_ "GenSigTimeoutTime_ALL" SG_ 1153 BCM_dTPMS_HighTemperature 5000;
BA_ "InvalidValue" SG_ 1153 BCM_dTPMS_HighTemperature "-";
BA_ "GenSigSendType" SG_ 1153 BCM_dTPMS_HighPressure 4;
BA_ "GenSigTimeoutTime_ALL" SG_ 1153 BCM_dTPMS_HighPressure 5000;
BA_ "InvalidValue" SG_ 1153 BCM_dTPMS_HighPressure "-";
BA_ "GenSigSendType" SG_ 1153 BCM_dTPMS_LowBattery 4;
BA_ "GenSigTimeoutTime_ALL" SG_ 1153 BCM_dTPMS_LowBattery 5000;
BA_ "InvalidValue" SG_ 1153 BCM_dTPMS_LowBattery "-";
BA_ "GenSigSendType" SG_ 1153 BCM_Keyfob_Leftcar 4;
BA_ "GenSigTimeoutTime_ALL" SG_ 1153 BCM_Keyfob_Leftcar 5000;
BA_ "InvalidValue" SG_ 1153 BCM_Keyfob_Leftcar "-";
BA_ "GenSigSendType" SG_ 1153 BCM_IDB_Brakelight_Malfunction 4;
BA_ "GenSigTimeoutTime_ALL" SG_ 1153 BCM_IDB_Brakelight_Malfunction 5000;
BA_ "InvalidValue" SG_ 1153 BCM_IDB_Brakelight_Malfunction "-";
BA_ "GenSigSendType" SG_ 1153 BCM_VCU_Brakelight_Malfunction 4;
BA_ "GenSigTimeoutTime_ALL" SG_ 1153 BCM_VCU_Brakelight_Malfunction 5000;
BA_ "InvalidValue" SG_ 1153 BCM_VCU_Brakelight_Malfunction "-";
BA_ "GenSigSendType" SG_ 1153 BCM_ADAS_Turnlight_Malfunction 4;
BA_ "GenSigTimeoutTime_ALL" SG_ 1153 BCM_ADAS_Turnlight_Malfunction 5000;
BA_ "InvalidValue" SG_ 1153 BCM_ADAS_Turnlight_Malfunction "-";
BA_ "GenSigSendType" SG_ 1153 BCM_ADAS_Highbeam_Malfunction 4;
BA_ "GenSigTimeoutTime_ALL" SG_ 1153 BCM_ADAS_Highbeam_Malfunction 5000;
BA_ "InvalidValue" SG_ 1153 BCM_ADAS_Highbeam_Malfunction "-";
BA_ "GenSigSendType" SG_ 1153 BCM_ADAS_LowBeam_Malfunction 4;
BA_ "GenSigTimeoutTime_ALL" SG_ 1153 BCM_ADAS_LowBeam_Malfunction 5000;
BA_ "InvalidValue" SG_ 1153 BCM_ADAS_LowBeam_Malfunction "-";
BA_ "GenSigSendType" SG_ 1153 BCM_MHU_Malfunction 4;
BA_ "GenSigTimeoutTime_ALL" SG_ 1153 BCM_MHU_Malfunction 5000;
BA_ "InvalidValue" SG_ 1153 BCM_MHU_Malfunction "-";
BA_ "GenSigSendType" SG_ 1153 BCM_BCM_Malfunction 4;
BA_ "GenSigTimeoutTime_ALL" SG_ 1153 BCM_BCM_Malfunction 5000;
BA_ "InvalidValue" SG_ 1153 BCM_BCM_Malfunction "-";
BA_ "GenSigSendType" SG_ 1153 BCM_SCM_Malfunction 4;
BA_ "GenSigTimeoutTime_ALL" SG_ 1153 BCM_SCM_Malfunction 5000;
BA_ "InvalidValue" SG_ 1153 BCM_SCM_Malfunction "-";
BA_ "GenSigSendType" SG_ 1153 BCM_CrashSignalDefect 4;
BA_ "GenSigTimeoutTime_ALL" SG_ 1153 BCM_CrashSignalDefect 5000;
BA_ "InvalidValue" SG_ 1153 BCM_CrashSignalDefect "-";
BA_ "GenSigSendType" SG_ 1153 BCM_FrontWiperDefect 4;
BA_ "GenSigTimeoutTime_ALL" SG_ 1153 BCM_FrontWiperDefect 5000;
BA_ "InvalidValue" SG_ 1153 BCM_FrontWiperDefect "-";
BA_ "GenSigSendType" SG_ 1153 BCM_Rear_RightDoorLockDefect 4;
BA_ "GenSigTimeoutTime_ALL" SG_ 1153 BCM_Rear_RightDoorLockDefect 5000;
BA_ "InvalidValue" SG_ 1153 BCM_Rear_RightDoorLockDefect "-";
BA_ "GenSigSendType" SG_ 1153 BCM_RearLeftDoorLockDefect 4;
BA_ "GenSigTimeoutTime_ALL" SG_ 1153 BCM_RearLeftDoorLockDefect 5000;
BA_ "InvalidValue" SG_ 1153 BCM_RearLeftDoorLockDefect "-";
BA_ "GenSigSendType" SG_ 1153 BCM_Front_RightDoorLockDefect 4;
BA_ "GenSigTimeoutTime_ALL" SG_ 1153 BCM_Front_RightDoorLockDefect 5000;
BA_ "InvalidValue" SG_ 1153 BCM_Front_RightDoorLockDefect "-";
BA_ "GenSigSendType" SG_ 1153 BCM_FrontLeftDoorLockDefect 4;
BA_ "GenSigTimeoutTime_ALL" SG_ 1153 BCM_FrontLeftDoorLockDefect 5000;
BA_ "InvalidValue" SG_ 1153 BCM_FrontLeftDoorLockDefect "-";
BA_ "GenSigSendType" SG_ 1153 BCM_LDML_Malfunction 4;
BA_ "GenSigTimeoutTime_ALL" SG_ 1153 BCM_LDML_Malfunction 5000;
BA_ "InvalidValue" SG_ 1153 BCM_LDML_Malfunction "-";
BA_ "GenSigSendType" SG_ 1153 BCM_LDMR_Malfunction 4;
BA_ "GenSigTimeoutTime_ALL" SG_ 1153 BCM_LDMR_Malfunction 5000;
BA_ "InvalidValue" SG_ 1153 BCM_LDMR_Malfunction "-";
BA_ "GenSigSendType" SG_ 1153 BCM_RLBL_Malfunction 4;
BA_ "GenSigTimeoutTime_ALL" SG_ 1153 BCM_RLBL_Malfunction 5000;
BA_ "InvalidValue" SG_ 1153 BCM_RLBL_Malfunction "-";
BA_ "GenSigSendType" SG_ 1153 BCM_RLBR_Malfunction 4;
BA_ "GenSigTimeoutTime_ALL" SG_ 1153 BCM_RLBR_Malfunction 5000;
BA_ "InvalidValue" SG_ 1153 BCM_RLBR_Malfunction "-";
BA_ "GenSigSendType" SG_ 1153 BCM_RLT_Malfunction 4;
BA_ "GenSigTimeoutTime_ALL" SG_ 1153 BCM_RLT_Malfunction 5000;
BA_ "InvalidValue" SG_ 1153 BCM_RLT_Malfunction "-";
BA_ "GenSigSendType" SG_ 1153 BCM_BCM_POWER_Malfunction 4;
BA_ "GenSigTimeoutTime_ALL" SG_ 1153 BCM_BCM_POWER_Malfunction 5000;
BA_ "InvalidValue" SG_ 1153 BCM_BCM_POWER_Malfunction "-";
BA_ "GenSigSendType" SG_ 1153 BCM_IDB_AutoHazardBlinking_Malf 4;
BA_ "GenSigTimeoutTime_ALL" SG_ 1153 BCM_IDB_AutoHazardBlinking_Malf 5000;
BA_ "InvalidValue" SG_ 1153 BCM_IDB_AutoHazardBlinking_Malf "-";
BA_ "GenSigSendType" SG_ 1154 CHSKM_XGW_WarnMsg 3;
BA_ "GenSigTimeoutTime_ALL" SG_ 1154 CHSKM_XGW_WarnMsg 5000;
BA_ "GenSigSendType" SG_ 1154 ALV_XGW_WarnMsg 3;
BA_ "GenSigTimeoutTime_ALL" SG_ 1154 ALV_XGW_WarnMsg 5000;
BA_ "InvalidValue" SG_ 1154 ALV_XGW_WarnMsg "Fh";
BA_ "GenSigSendType" SG_ 1154 XGW_AutoHLLevelingFault 4;
BA_ "GenSigTimeoutTime_ALL" SG_ 1154 XGW_AutoHLLevelingFault 5000;
BA_ "GenSigSendType" SG_ 1154 XGW_WasherFluidLvlSw 4;
BA_ "GenSigTimeoutTime_ALL" SG_ 1154 XGW_WasherFluidLvlSw 5000;
BA_ "GenSigSendType" SG_ 1154 XGW_Warning_Flag_3 4;
BA_ "GenSigTimeoutTime_ALL" SG_ 1154 XGW_Warning_Flag_3 5000;
BA_ "GenSigSendType" SG_ 1154 XGW_Warning_Flag_4 4;
BA_ "GenSigTimeoutTime_ALL" SG_ 1154 XGW_Warning_Flag_4 5000;
BA_ "GenSigSendType" SG_ 1154 XGW_Warning_Flag_5 4;
BA_ "GenSigTimeoutTime_ALL" SG_ 1154 XGW_Warning_Flag_5 5000;
BA_ "GenSigSendType" SG_ 1154 XGW_Warning_Flag_6 4;
BA_ "GenSigTimeoutTime_ALL" SG_ 1154 XGW_Warning_Flag_6 5000;
BA_ "GenSigSendType" SG_ 1154 XGW_Warning_Flag_7 4;
BA_ "GenSigTimeoutTime_ALL" SG_ 1154 XGW_Warning_Flag_7 5000;
BA_ "GenSigSendType" SG_ 1154 XGW_Warning_Flag_8 4;
BA_ "GenSigTimeoutTime_ALL" SG_ 1154 XGW_Warning_Flag_8 5000;
BA_ "GenSigSendType" SG_ 1154 XGW_Warning_Flag_9 4;
BA_ "GenSigTimeoutTime_ALL" SG_ 1154 XGW_Warning_Flag_9 5000;
BA_ "GenSigSendType" SG_ 1154 XGW_Warning_Flag_10 4;
BA_ "GenSigTimeoutTime_ALL" SG_ 1154 XGW_Warning_Flag_10 5000;
BA_ "GenSigSendType" SG_ 1154 XGW_Warning_Flag_11 4;
BA_ "GenSigTimeoutTime_ALL" SG_ 1154 XGW_Warning_Flag_11 5000;
BA_ "GenSigSendType" SG_ 1154 XGW_Warning_Flag_12 4;
BA_ "GenSigTimeoutTime_ALL" SG_ 1154 XGW_Warning_Flag_12 5000;
BA_ "GenSigSendType" SG_ 1154 XGW_Reserved_signal1 4;
BA_ "GenSigTimeoutTime_ALL" SG_ 1154 XGW_Reserved_signal1 5000;
BA_ "GenSigSendType" SG_ 1154 XGW_Reserved_signal2 4;
BA_ "GenSigTimeoutTime_ALL" SG_ 1154 XGW_Reserved_signal2 5000;
BA_ "GenSigSendType" SG_ 1154 XGW_Reserved_signal3 4;
BA_ "GenSigTimeoutTime_ALL" SG_ 1154 XGW_Reserved_signal3 5000;
BA_ "GenSigSendType" SG_ 1154 XGW_Reserved_signal4 4;
BA_ "GenSigTimeoutTime_ALL" SG_ 1154 XGW_Reserved_signal4 5000;
BA_ "GenSigSendType" SG_ 1154 XGW_Reserved_signal5 4;
BA_ "GenSigTimeoutTime_ALL" SG_ 1154 XGW_Reserved_signal5 5000;
BA_ "GenSigTimeoutTime_ALL" SG_ 1155 TPMS_FLTirePress 500;
BA_ "InvalidValue" SG_ 1155 TPMS_FLTirePress "FFh";
BA_ "GenSigTimeoutTime_ALL" SG_ 1155 TPMS_FRTirePress 500;
BA_ "InvalidValue" SG_ 1155 TPMS_FRTirePress "FFh";
BA_ "GenSigTimeoutTime_ALL" SG_ 1155 TPMS_RLTirePress 500;
BA_ "InvalidValue" SG_ 1155 TPMS_RLTirePress "FFh";
BA_ "GenSigTimeoutTime_ALL" SG_ 1155 TPMS_RRTirePress 500;
BA_ "InvalidValue" SG_ 1155 TPMS_RRTirePress "FFh";
BA_ "GenSigTimeoutTime_ALL" SG_ 1155 TPMS_FLTirePressAlarm 500;
BA_ "InvalidValue" SG_ 1155 TPMS_FLTirePressAlarm "null";
BA_ "GenSigTimeoutTime_ALL" SG_ 1155 TPMS_FRTirePressAlarm 500;
BA_ "InvalidValue" SG_ 1155 TPMS_FRTirePressAlarm "null";
BA_ "GenSigTimeoutTime_ALL" SG_ 1155 TPMS_RLTirePressAlarm 500;
BA_ "InvalidValue" SG_ 1155 TPMS_RLTirePressAlarm "null";
BA_ "GenSigTimeoutTime_ALL" SG_ 1155 TPMS_RRTirePressAlarm 500;
BA_ "InvalidValue" SG_ 1155 TPMS_RRTirePressAlarm "null";
BA_ "GenSigTimeoutTime_ALL" SG_ 1155 TPMS_TirePosition 500;
BA_ "InvalidValue" SG_ 1155 TPMS_TirePosition "null";
BA_ "GenSigTimeoutTime_ALL" SG_ 1155 TPMS_ready2learning 500;
BA_ "InvalidValue" SG_ 1155 TPMS_ready2learning "null";
BA_ "InvalidValue" SG_ 1155 TPMS_ready2learning "0";
BA_ "GenSigTimeoutTime_ALL" SG_ 1155 TPMS_TireTempAlarm 500;
BA_ "InvalidValue" SG_ 1155 TPMS_TireTempAlarm "null";
BA_ "GenSigTimeoutTime_ALL" SG_ 1155 TPMS_LearningStatus 500;
BA_ "InvalidValue" SG_ 1155 TPMS_LearningStatus "null";
BA_ "InvalidValue" SG_ 1155 TPMS_LearningStatus "0";
BA_ "GenSigStartValue" SG_ 1155 TPMS_TireTemp 68;
BA_ "GenSigTimeoutTime_ALL" SG_ 1155 TPMS_TireTemp 500;
BA_ "InvalidValue" SG_ 1155 TPMS_TireTemp "FFh";
BA_ "GenSigTimeoutTime_ALL" SG_ 1156 CHKSM_APA_FEEDBACK_MHU 500;
BA_ "InvalidValue" SG_ 1156 CHKSM_APA_FEEDBACK_MHU "0";
BA_ "GenSigTimeoutTime_ALL" SG_ 1156 ALV_APA_FEEDBACK_MHU 500;
BA_ "InvalidValue" SG_ 1156 ALV_APA_FEEDBACK_MHU "Fh";
BA_ "GenSigTimeoutTime_ALL" SG_ 1156 APA_ReqInfoDispTxt3 500;
BA_ "InvalidValue" SG_ 1156 APA_ReqInfoDispTxt3 "1Fh";
BA_ "GenSigTimeoutTime_ALL" SG_ 1156 APA_ParkOutDircnDisReq 500;
BA_ "GenSigTimeoutTime_ALL" SG_ 1156 APA_ParkOutModeDisReq 500;
BA_ "GenSigTimeoutTime_ALL" SG_ 1156 APA_MHU_DisplaystartbuttonReq 500;
BA_ "GenSigTimeoutTime_ALL" SG_ 1156 APA_ReqInfoDispTxt4 500;
BA_ "InvalidValue" SG_ 1156 APA_ReqInfoDispTxt4 "Fh";
BA_ "GenSigTimeoutTime_ALL" SG_ 1156 APA_ReqInfoDispTxt2 500;
BA_ "InvalidValue" SG_ 1156 APA_ReqInfoDispTxt2 "7h";
BA_ "GenSigTimeoutTime_ALL" SG_ 1156 APA_ReqInfoDispTxt1 500;
BA_ "InvalidValue" SG_ 1156 APA_ReqInfoDispTxt1 "7h";
BA_ "GenSigTimeoutTime_ALL" SG_ 1156 APA_MHU_Displayparkingtype 500;
BA_ "GenSigTimeoutTime_ALL" SG_ 1156 APA_ShowAPAFdbck 500;
BA_ "GenSigTimeoutTime_ALL" SG_ 1156 APA_FuncModeFdbck 500;
BA_ "InvalidValue" SG_ 1156 APA_FuncModeFdbck "3h";
BA_ "GenSigTimeoutTime_ALL" SG_ 1156 APA_MHU_DisplayrecoverbuttonReq 500;
BA_ "GenSigTimeoutTime_ALL" SG_ 1156 APA_SysSoundIndication 500;
BA_ "InvalidValue" SG_ 1156 APA_SysSoundIndication "7h";
BA_ "GenSigTimeoutTime_ALL" SG_ 1156 APA_RecommendSlotID 500;
BA_ "InvalidValue" SG_ 1156 APA_RecommendSlotID "FFh";
BA_ "GenSigTimeoutTime_ALL" SG_ 1156 APA_Currentfunction 500;
BA_ "InvalidValue" SG_ 1156 APA_Currentfunction "7h";
BA_ "GenSigTimeoutTime_ALL" SG_ 1156 APA_MHU_Status 500;
BA_ "InvalidValue" SG_ 1156 APA_MHU_Status "7h";
BA_ "GenSigSendType" SG_ 1160 CHKSM_ACM_WARNING_MSG 3;
BA_ "GenSigTimeoutTime_ALL" SG_ 1160 CHKSM_ACM_WARNING_MSG 5000;
BA_ "InvalidValue" SG_ 1160 CHKSM_ACM_WARNING_MSG "null";
BA_ "GenSigSendType" SG_ 1160 ALV_ACM_WARNING_MSG 3;
BA_ "GenSigTimeoutTime_ALL" SG_ 1160 ALV_ACM_WARNING_MSG 5000;
BA_ "InvalidValue" SG_ 1160 ALV_ACM_WARNING_MSG "Fh";
BA_ "GenSigSendType" SG_ 1160 ACM_Malfunction 4;
BA_ "GenSigTimeoutTime_ALL" SG_ 1160 ACM_Malfunction 5000;
BA_ "InvalidValue" SG_ 1160 ACM_Malfunction "null";
BA_ "GenSigSendType" SG_ 1160 ACM_Pre_Drive_Check 4;
BA_ "GenSigTimeoutTime_ALL" SG_ 1160 ACM_Pre_Drive_Check 5000;
BA_ "InvalidValue" SG_ 1160 ACM_Pre_Drive_Check "null";
BA_ "GenSigSendType" SG_ 1160 ACM_in_Plant_Mode 4;
BA_ "GenSigTimeoutTime_ALL" SG_ 1160 ACM_in_Plant_Mode 5000;
BA_ "InvalidValue" SG_ 1160 ACM_in_Plant_Mode "null";
BA_ "GenSigSendType" SG_ 1160 ACM_PAB_Suppression 4;
BA_ "GenSigTimeoutTime_ALL" SG_ 1160 ACM_PAB_Suppression 5000;
BA_ "InvalidValue" SG_ 1160 ACM_PAB_Suppression "3h";
BA_ "GenSigSendType" SG_ 1160 ACM_Airbag_Disabled 4;
BA_ "GenSigTimeoutTime_ALL" SG_ 1160 ACM_Airbag_Disabled 5000;
BA_ "InvalidValue" SG_ 1160 ACM_Airbag_Disabled "null";
BA_ "GenSigSendType" SG_ 1160 ACM_Development_Calibration 4;
BA_ "GenSigTimeoutTime_ALL" SG_ 1160 ACM_Development_Calibration 5000;
BA_ "InvalidValue" SG_ 1160 ACM_Development_Calibration "null";
BA_ "GenSigSendType" SG_ 1160 ACM_In_Disposal_Mode 4;
BA_ "GenSigTimeoutTime_ALL" SG_ 1160 ACM_In_Disposal_Mode 5000;
BA_ "InvalidValue" SG_ 1160 ACM_In_Disposal_Mode "null";
BA_ "GenSigSendType" SG_ 1160 ACM_Seatbelt_Reminder_Request 4;
BA_ "GenSigTimeoutTime_ALL" SG_ 1160 ACM_Seatbelt_Reminder_Request 5000;
BA_ "InvalidValue" SG_ 1160 ACM_Seatbelt_Reminder_Request "null";
BA_ "GenSigSendType" SG_ 1160 ACM_SBR_Chime_Req 4;
BA_ "GenSigTimeoutTime_ALL" SG_ 1160 ACM_SBR_Chime_Req 5000;
BA_ "InvalidValue" SG_ 1160 ACM_SBR_Chime_Req "null";
BA_ "GenSigSendType" SG_ 1160 ACM_SBR_Blinking_Req 4;
BA_ "GenSigTimeoutTime_ALL" SG_ 1160 ACM_SBR_Blinking_Req 5000;
BA_ "InvalidValue" SG_ 1160 ACM_SBR_Blinking_Req "null";
BA_ "GenSigTimeoutTime_ALL" SG_ 1161 CHSKM_CCU_WarnMsg 500;
BA_ "InvalidValue" SG_ 1161 CHSKM_CCU_WarnMsg "null";
BA_ "GenSigTimeoutTime_ALL" SG_ 1161 ALV_CCU_WarnMsg 500;
BA_ "InvalidValue" SG_ 1161 ALV_CCU_WarnMsg "Fh";
BA_ "GenSigTimeoutTime_ALL" SG_ 1161 CCU_Malfunction 500;
BA_ "InvalidValue" SG_ 1161 CCU_Malfunction "null";
BA_ "GenSigTimeoutTime_ALL" SG_ 1161 CCU_Warning_Flag_2 500;
BA_ "InvalidValue" SG_ 1161 CCU_Warning_Flag_2 "null";
BA_ "GenSigTimeoutTime_ALL" SG_ 1161 CCU_Warning_Flag_3 500;
BA_ "InvalidValue" SG_ 1161 CCU_Warning_Flag_3 "null";
BA_ "GenSigTimeoutTime_ALL" SG_ 1161 CCU_Warning_Flag_4 500;
BA_ "InvalidValue" SG_ 1161 CCU_Warning_Flag_4 "null";
BA_ "GenSigTimeoutTime_ALL" SG_ 1161 CCU_Warning_Flag_5 500;
BA_ "InvalidValue" SG_ 1161 CCU_Warning_Flag_5 "null";
BA_ "GenSigTimeoutTime_ALL" SG_ 1161 CCU_Warning_Flag_6 500;
BA_ "InvalidValue" SG_ 1161 CCU_Warning_Flag_6 "null";
BA_ "GenSigTimeoutTime_ALL" SG_ 1161 CCU_Warning_Flag_7 500;
BA_ "InvalidValue" SG_ 1161 CCU_Warning_Flag_7 "null";
BA_ "GenSigTimeoutTime_ALL" SG_ 1161 CCU_Warning_Flag_8 500;
BA_ "InvalidValue" SG_ 1161 CCU_Warning_Flag_8 "null";
BA_ "GenSigTimeoutTime_ALL" SG_ 1161 CCU_Warning_Flag_9 500;
BA_ "InvalidValue" SG_ 1161 CCU_Warning_Flag_9 "null";
BA_ "GenSigTimeoutTime_ALL" SG_ 1161 CCU_Warning_Flag_10 500;
BA_ "InvalidValue" SG_ 1161 CCU_Warning_Flag_10 "null";
BA_ "GenSigTimeoutTime_ALL" SG_ 1161 CCU_Warning_Flag_11 500;
BA_ "InvalidValue" SG_ 1161 CCU_Warning_Flag_11 "null";
BA_ "GenSigTimeoutTime_ALL" SG_ 1161 CCU_Warning_Flag_12 500;
BA_ "InvalidValue" SG_ 1161 CCU_Warning_Flag_12 "null";
BA_ "GenSigSendType" SG_ 1165 CHSKM_HUD_WarnMsg 3;
BA_ "GenSigTimeoutTime_ALL" SG_ 1165 CHSKM_HUD_WarnMsg 5000;
BA_ "GenSigSendType" SG_ 1165 ALV_HUD_WarnMsg 3;
BA_ "GenSigTimeoutTime_ALL" SG_ 1165 ALV_HUD_WarnMsg 5000;
BA_ "InvalidValue" SG_ 1165 ALV_HUD_WarnMsg "Fh";
BA_ "GenSigSendType" SG_ 1165 HUD_Malfunction 4;
BA_ "GenSigTimeoutTime_ALL" SG_ 1165 HUD_Malfunction 5000;
BA_ "GenSigSendType" SG_ 1165 HUD_Failed_Temporary 4;
BA_ "GenSigTimeoutTime_ALL" SG_ 1165 HUD_Failed_Temporary 5000;
BA_ "GenSigSendType" SG_ 1165 HUD_Overheating 4;
BA_ "GenSigTimeoutTime_ALL" SG_ 1165 HUD_Overheating 5000;
BA_ "GenSigSendType" SG_ 1165 HUD_Warning_Flag_4 4;
BA_ "GenSigTimeoutTime_ALL" SG_ 1165 HUD_Warning_Flag_4 5000;
BA_ "GenSigSendType" SG_ 1165 HUD_Warning_Flag_5 4;
BA_ "GenSigTimeoutTime_ALL" SG_ 1165 HUD_Warning_Flag_5 5000;
BA_ "GenSigSendType" SG_ 1165 HUD_Warning_Flag_6 4;
BA_ "GenSigTimeoutTime_ALL" SG_ 1165 HUD_Warning_Flag_6 5000;
BA_ "GenSigSendType" SG_ 1165 HUD_Warning_Flag_7 4;
BA_ "GenSigTimeoutTime_ALL" SG_ 1165 HUD_Warning_Flag_7 5000;
BA_ "GenSigSendType" SG_ 1165 HUD_Warning_Flag_8 4;
BA_ "GenSigTimeoutTime_ALL" SG_ 1165 HUD_Warning_Flag_8 5000;
BA_ "GenSigSendType" SG_ 1165 HUD_Warning_Flag_9 4;
BA_ "GenSigTimeoutTime_ALL" SG_ 1165 HUD_Warning_Flag_9 5000;
BA_ "GenSigSendType" SG_ 1165 HUD_Warning_Flag_10 4;
BA_ "GenSigTimeoutTime_ALL" SG_ 1165 HUD_Warning_Flag_10 5000;
BA_ "GenSigSendType" SG_ 1165 HUD_Warning_Flag_11 4;
BA_ "GenSigTimeoutTime_ALL" SG_ 1165 HUD_Warning_Flag_11 5000;
BA_ "GenSigSendType" SG_ 1165 HUD_Warning_Flag_12 4;
BA_ "GenSigTimeoutTime_ALL" SG_ 1165 HUD_Warning_Flag_12 5000;
BA_ "GenSigSendType" SG_ 1165 SECCAN_HUDWarn 3;
BA_ "GenSigTimeoutTime_ALL" SG_ 1165 SECCAN_HUDWarn 5000;
BA_ "GenSigTimeoutTime_ALL" SG_ 1166 CHSKM_ETG_WarnMsg 500;
BA_ "InvalidValue" SG_ 1166 CHSKM_ETG_WarnMsg "null";
BA_ "GenSigTimeoutTime_ALL" SG_ 1166 ALV_ETG_WarnMsg 500;
BA_ "InvalidValue" SG_ 1166 ALV_ETG_WarnMsg "Fh";
BA_ "GenSigTimeoutTime_ALL" SG_ 1166 ETG_Malfunction 500;
BA_ "InvalidValue" SG_ 1166 ETG_Malfunction "null";
BA_ "GenSigTimeoutTime_ALL" SG_ 1166 ETG_Warning_Flag_2 500;
BA_ "InvalidValue" SG_ 1166 ETG_Warning_Flag_2 "null";
BA_ "GenSigTimeoutTime_ALL" SG_ 1166 ETG_Warning_Flag_3 500;
BA_ "InvalidValue" SG_ 1166 ETG_Warning_Flag_3 "null";
BA_ "GenSigTimeoutTime_ALL" SG_ 1166 ETG_Warning_Flag_4 500;
BA_ "InvalidValue" SG_ 1166 ETG_Warning_Flag_4 "null";
BA_ "GenSigTimeoutTime_ALL" SG_ 1166 ETG_Warning_Flag_5 500;
BA_ "InvalidValue" SG_ 1166 ETG_Warning_Flag_5 "null";
BA_ "GenSigTimeoutTime_ALL" SG_ 1166 ETG_Warning_Flag_6 500;
BA_ "InvalidValue" SG_ 1166 ETG_Warning_Flag_6 "null";
BA_ "GenSigTimeoutTime_ALL" SG_ 1166 ETG_Warning_Flag_7 500;
BA_ "InvalidValue" SG_ 1166 ETG_Warning_Flag_7 "null";
BA_ "GenSigTimeoutTime_ALL" SG_ 1166 ETG_Warning_Flag_8 500;
BA_ "InvalidValue" SG_ 1166 ETG_Warning_Flag_8 "null";
BA_ "GenSigTimeoutTime_ALL" SG_ 1166 ETG_Warning_Flag_9 500;
BA_ "InvalidValue" SG_ 1166 ETG_Warning_Flag_9 "null";
BA_ "GenSigTimeoutTime_ALL" SG_ 1166 ETG_Warning_Flag_10 500;
BA_ "InvalidValue" SG_ 1166 ETG_Warning_Flag_10 "null";
BA_ "GenSigTimeoutTime_ALL" SG_ 1166 ETG_Warning_Flag_11 500;
BA_ "InvalidValue" SG_ 1166 ETG_Warning_Flag_11 "null";
BA_ "GenSigTimeoutTime_ALL" SG_ 1166 ETG_Warning_Flag_12 500;
BA_ "InvalidValue" SG_ 1166 ETG_Warning_Flag_12 "null";
BA_ "GenSigSendType" SG_ 1168 CHSKM_GS_WarnMsg 3;
BA_ "GenSigTimeoutTime_ALL" SG_ 1168 CHSKM_GS_WarnMsg 5000;
BA_ "InvalidValue" SG_ 1168 CHSKM_GS_WarnMsg "null";
BA_ "GenSigSendType" SG_ 1168 ALV_GS_WarnMsg 3;
BA_ "GenSigTimeoutTime_ALL" SG_ 1168 ALV_GS_WarnMsg 5000;
BA_ "InvalidValue" SG_ 1168 ALV_GS_WarnMsg "Fh";
BA_ "GenSigSendType" SG_ 1168 GS_Warning_Flag_1 4;
BA_ "GenSigTimeoutTime_ALL" SG_ 1168 GS_Warning_Flag_1 5000;
BA_ "InvalidValue" SG_ 1168 GS_Warning_Flag_1 "null";
BA_ "GenSigSendType" SG_ 1168 GS_Warning_Flag_2 4;
BA_ "GenSigTimeoutTime_ALL" SG_ 1168 GS_Warning_Flag_2 5000;
BA_ "InvalidValue" SG_ 1168 GS_Warning_Flag_2 "null";
BA_ "GenSigSendType" SG_ 1168 GS_Warning_Flag_3 4;
BA_ "GenSigTimeoutTime_ALL" SG_ 1168 GS_Warning_Flag_3 5000;
BA_ "InvalidValue" SG_ 1168 GS_Warning_Flag_3 "null";
BA_ "GenSigSendType" SG_ 1168 GS_Warning_Flag_4 4;
BA_ "GenSigTimeoutTime_ALL" SG_ 1168 GS_Warning_Flag_4 5000;
BA_ "InvalidValue" SG_ 1168 GS_Warning_Flag_4 "null";
BA_ "GenSigSendType" SG_ 1168 GS_Warning_Flag_5 4;
BA_ "GenSigTimeoutTime_ALL" SG_ 1168 GS_Warning_Flag_5 5000;
BA_ "InvalidValue" SG_ 1168 GS_Warning_Flag_5 "null";
BA_ "GenSigSendType" SG_ 1168 GS_Warning_Flag_6 4;
BA_ "GenSigTimeoutTime_ALL" SG_ 1168 GS_Warning_Flag_6 5000;
BA_ "InvalidValue" SG_ 1168 GS_Warning_Flag_6 "null";
BA_ "GenSigSendType" SG_ 1168 GS_Warning_Flag_7 4;
BA_ "GenSigTimeoutTime_ALL" SG_ 1168 GS_Warning_Flag_7 5000;
BA_ "InvalidValue" SG_ 1168 GS_Warning_Flag_7 "null";
BA_ "GenSigSendType" SG_ 1168 GS_Warning_Flag_8 4;
BA_ "GenSigTimeoutTime_ALL" SG_ 1168 GS_Warning_Flag_8 5000;
BA_ "InvalidValue" SG_ 1168 GS_Warning_Flag_8 "null";
BA_ "GenSigSendType" SG_ 1168 GS_Warning_Flag_9 4;
BA_ "GenSigTimeoutTime_ALL" SG_ 1168 GS_Warning_Flag_9 5000;
BA_ "InvalidValue" SG_ 1168 GS_Warning_Flag_9 "null";
BA_ "GenSigSendType" SG_ 1168 GS_Warning_Flag_10 4;
BA_ "GenSigTimeoutTime_ALL" SG_ 1168 GS_Warning_Flag_10 5000;
BA_ "InvalidValue" SG_ 1168 GS_Warning_Flag_10 "null";
BA_ "GenSigSendType" SG_ 1168 GS_Warning_Flag_11 4;
BA_ "GenSigTimeoutTime_ALL" SG_ 1168 GS_Warning_Flag_11 5000;
BA_ "InvalidValue" SG_ 1168 GS_Warning_Flag_11 "null";
BA_ "GenSigSendType" SG_ 1168 GS_Warning_Flag_12 4;
BA_ "GenSigTimeoutTime_ALL" SG_ 1168 GS_Warning_Flag_12 5000;
BA_ "InvalidValue" SG_ 1168 GS_Warning_Flag_12 "null";
BA_ "GenSigSendType" SG_ 1168 GS_Reserved_signal1 4;
BA_ "GenSigTimeoutTime_ALL" SG_ 1168 GS_Reserved_signal1 5000;
BA_ "InvalidValue" SG_ 1168 GS_Reserved_signal1 "null";
BA_ "GenSigSendType" SG_ 1168 GS_Reserved_signal2 4;
BA_ "GenSigTimeoutTime_ALL" SG_ 1168 GS_Reserved_signal2 5000;
BA_ "InvalidValue" SG_ 1168 GS_Reserved_signal2 "null";
BA_ "GenSigSendType" SG_ 1168 GS_Reserved_signal3 4;
BA_ "GenSigTimeoutTime_ALL" SG_ 1168 GS_Reserved_signal3 5000;
BA_ "InvalidValue" SG_ 1168 GS_Reserved_signal3 "null";
BA_ "GenSigSendType" SG_ 1168 GS_Reserved_signal4 4;
BA_ "GenSigTimeoutTime_ALL" SG_ 1168 GS_Reserved_signal4 5000;
BA_ "InvalidValue" SG_ 1168 GS_Reserved_signal4 "null";
BA_ "GenSigSendType" SG_ 1168 GS_Reserved_signal5 4;
BA_ "GenSigTimeoutTime_ALL" SG_ 1168 GS_Reserved_signal5 5000;
BA_ "InvalidValue" SG_ 1168 GS_Reserved_signal5 "null";
BA_ "GenSigSendType" SG_ 1171 CHSKM_BMS_WarnMsg 3;
BA_ "GenSigTimeoutTime_ALL" SG_ 1171 CHSKM_BMS_WarnMsg 5000;
BA_ "InvalidValue" SG_ 1171 CHSKM_BMS_WarnMsg "null";
BA_ "GenSigSendType" SG_ 1171 ALV_BMS_WarnMsg 3;
BA_ "GenSigTimeoutTime_ALL" SG_ 1171 ALV_BMS_WarnMsg 5000;
BA_ "InvalidValue" SG_ 1171 ALV_BMS_WarnMsg "Fh";
BA_ "GenSigSendType" SG_ 1171 BMS_PackTempSts 4;
BA_ "GenSigTimeoutTime_ALL" SG_ 1171 BMS_PackTempSts 5000;
BA_ "InvalidValue" SG_ 1171 BMS_PackTempSts "null";
BA_ "GenSigSendType" SG_ 1171 BMS_ThermalRunaway 4;
BA_ "GenSigTimeoutTime_ALL" SG_ 1171 BMS_ThermalRunaway 5000;
BA_ "InvalidValue" SG_ 1171 BMS_ThermalRunaway "null";
BA_ "GenSigSendType" SG_ 1171 BMS_BatteryReplacement 4;
BA_ "GenSigTimeoutTime_ALL" SG_ 1171 BMS_BatteryReplacement 5000;
BA_ "InvalidValue" SG_ 1171 BMS_BatteryReplacement "null";
BA_ "GenSigSendType" SG_ 1171 BMS_Warning_PowerDegrade 4;
BA_ "GenSigTimeoutTime_ALL" SG_ 1171 BMS_Warning_PowerDegrade 5000;
BA_ "InvalidValue" SG_ 1171 BMS_Warning_PowerDegrade "null";
BA_ "GenSigSendType" SG_ 1171 BMS_Warning_DeltaSoC 4;
BA_ "GenSigTimeoutTime_ALL" SG_ 1171 BMS_Warning_DeltaSoC 5000;
BA_ "InvalidValue" SG_ 1171 BMS_Warning_DeltaSoC "null";
BA_ "GenSigSendType" SG_ 1171 BMS_Warning_HVILSts 4;
BA_ "GenSigTimeoutTime_ALL" SG_ 1171 BMS_Warning_HVILSts 5000;
BA_ "InvalidValue" SG_ 1171 BMS_Warning_HVILSts "null";
BA_ "GenSigSendType" SG_ 1171 BMS_Warning_Isolation 4;
BA_ "GenSigTimeoutTime_ALL" SG_ 1171 BMS_Warning_Isolation 5000;
BA_ "InvalidValue" SG_ 1171 BMS_Warning_Isolation "null";
BA_ "GenSigSendType" SG_ 1171 BMS_Warning_CoolantLeakage 4;
BA_ "GenSigTimeoutTime_ALL" SG_ 1171 BMS_Warning_CoolantLeakage 5000;
BA_ "InvalidValue" SG_ 1171 BMS_Warning_CoolantLeakage "null";
BA_ "GenSigSendType" SG_ 1171 BMS_MalfunctionSts 4;
BA_ "GenSigTimeoutTime_ALL" SG_ 1171 BMS_MalfunctionSts 5000;
BA_ "InvalidValue" SG_ 1171 BMS_MalfunctionSts "null";
BA_ "GenSigSendType" SG_ 1171 BMS_LowBattery 4;
BA_ "GenSigTimeoutTime_ALL" SG_ 1171 BMS_LowBattery 5000;
BA_ "InvalidValue" SG_ 1171 BMS_LowBattery "null";
BA_ "GenSigSendType" SG_ 1171 BMS_Warning_DeltaTemperature 4;
BA_ "GenSigTimeoutTime_ALL" SG_ 1171 BMS_Warning_DeltaTemperature 5000;
BA_ "InvalidValue" SG_ 1171 BMS_Warning_DeltaTemperature "null";
BA_ "GenSigSendType" SG_ 1171 BMS_Warning_BDUTemperatureSts 4;
BA_ "GenSigTimeoutTime_ALL" SG_ 1171 BMS_Warning_BDUTemperatureSts 5000;
BA_ "InvalidValue" SG_ 1171 BMS_Warning_BDUTemperatureSts "null";
BA_ "GenSigSendType" SG_ 1171 BMS_Warning_Contactor_Aging 4;
BA_ "GenSigTimeoutTime_ALL" SG_ 1171 BMS_Warning_Contactor_Aging 5000;
BA_ "InvalidValue" SG_ 1171 BMS_Warning_Contactor_Aging "null";
BA_ "GenSigSendType" SG_ 1171 BMS_Reserved_signal4 4;
BA_ "GenSigTimeoutTime_ALL" SG_ 1171 BMS_Reserved_signal4 5000;
BA_ "InvalidValue" SG_ 1171 BMS_Reserved_signal4 "null";
BA_ "GenSigSendType" SG_ 1171 BMS_Reserved_signal5 4;
BA_ "GenSigTimeoutTime_ALL" SG_ 1171 BMS_Reserved_signal5 5000;
BA_ "InvalidValue" SG_ 1171 BMS_Reserved_signal5 "null";
BA_ "GenSigSendType" SG_ 1178 CHSKM_EDS_R_WarnMsg 3;
BA_ "GenSigTimeoutTime_ALL" SG_ 1178 CHSKM_EDS_R_WarnMsg 5000;
BA_ "InvalidValue" SG_ 1178 CHSKM_EDS_R_WarnMsg "null";
BA_ "GenSigSendType" SG_ 1178 ALV_EDS_R_WarnMsg 3;
BA_ "GenSigTimeoutTime_ALL" SG_ 1178 ALV_EDS_R_WarnMsg 5000;
BA_ "InvalidValue" SG_ 1178 ALV_EDS_R_WarnMsg "Fh";
BA_ "GenSigSendType" SG_ 1178 EDS_R_Error_1 4;
BA_ "GenSigTimeoutTime_ALL" SG_ 1178 EDS_R_Error_1 5000;
BA_ "InvalidValue" SG_ 1178 EDS_R_Error_1 "null";
BA_ "GenSigSendType" SG_ 1178 EDS_R_Error_2 4;
BA_ "GenSigTimeoutTime_ALL" SG_ 1178 EDS_R_Error_2 5000;
BA_ "InvalidValue" SG_ 1178 EDS_R_Error_2 "null";
BA_ "GenSigSendType" SG_ 1178 EDS_R_Error_3 4;
BA_ "GenSigTimeoutTime_ALL" SG_ 1178 EDS_R_Error_3 5000;
BA_ "InvalidValue" SG_ 1178 EDS_R_Error_3 "null";
BA_ "GenSigSendType" SG_ 1178 EDS_R_Error_4 4;
BA_ "GenSigTimeoutTime_ALL" SG_ 1178 EDS_R_Error_4 5000;
BA_ "InvalidValue" SG_ 1178 EDS_R_Error_4 "null";
BA_ "GenSigSendType" SG_ 1178 EDS_R_Error_5 4;
BA_ "GenSigTimeoutTime_ALL" SG_ 1178 EDS_R_Error_5 5000;
BA_ "InvalidValue" SG_ 1178 EDS_R_Error_5 "null";
BA_ "GenSigSendType" SG_ 1178 EDS_R_Error_6 4;
BA_ "GenSigTimeoutTime_ALL" SG_ 1178 EDS_R_Error_6 5000;
BA_ "InvalidValue" SG_ 1178 EDS_R_Error_6 "null";
BA_ "GenSigSendType" SG_ 1178 EDS_R_Error_7 4;
BA_ "GenSigTimeoutTime_ALL" SG_ 1178 EDS_R_Error_7 5000;
BA_ "InvalidValue" SG_ 1178 EDS_R_Error_7 "null";
BA_ "GenSigSendType" SG_ 1178 EDS_R_Error_8 4;
BA_ "GenSigTimeoutTime_ALL" SG_ 1178 EDS_R_Error_8 5000;
BA_ "InvalidValue" SG_ 1178 EDS_R_Error_8 "null";
BA_ "GenSigSendType" SG_ 1178 EDS_R_Error_9 4;
BA_ "GenSigTimeoutTime_ALL" SG_ 1178 EDS_R_Error_9 5000;
BA_ "InvalidValue" SG_ 1178 EDS_R_Error_9 "null";
BA_ "GenSigSendType" SG_ 1178 EDS_R_Error_10 4;
BA_ "GenSigTimeoutTime_ALL" SG_ 1178 EDS_R_Error_10 5000;
BA_ "InvalidValue" SG_ 1178 EDS_R_Error_10 "null";
BA_ "GenSigSendType" SG_ 1178 EDS_R_Error_11 4;
BA_ "GenSigTimeoutTime_ALL" SG_ 1178 EDS_R_Error_11 5000;
BA_ "InvalidValue" SG_ 1178 EDS_R_Error_11 "null";
BA_ "GenSigSendType" SG_ 1178 EDS_R_Error_12 4;
BA_ "GenSigTimeoutTime_ALL" SG_ 1178 EDS_R_Error_12 5000;
BA_ "InvalidValue" SG_ 1178 EDS_R_Error_12 "null";
BA_ "GenSigSendType" SG_ 1178 EDS_R_Error_13 4;
BA_ "GenSigTimeoutTime_ALL" SG_ 1178 EDS_R_Error_13 5000;
BA_ "InvalidValue" SG_ 1178 EDS_R_Error_13 "null";
BA_ "GenSigSendType" SG_ 1178 EDS_R_Error_14 4;
BA_ "GenSigTimeoutTime_ALL" SG_ 1178 EDS_R_Error_14 5000;
BA_ "InvalidValue" SG_ 1178 EDS_R_Error_14 "null";
BA_ "GenSigSendType" SG_ 1178 EDS_R_Error_15 4;
BA_ "GenSigTimeoutTime_ALL" SG_ 1178 EDS_R_Error_15 5000;
BA_ "InvalidValue" SG_ 1178 EDS_R_Error_15 "null";
BA_ "GenSigSendType" SG_ 1178 EDS_R_Error_16 4;
BA_ "GenSigTimeoutTime_ALL" SG_ 1178 EDS_R_Error_16 5000;
BA_ "InvalidValue" SG_ 1178 EDS_R_Error_16 "null";
BA_ "GenSigSendType" SG_ 1178 EDS_R_Error_17 4;
BA_ "GenSigTimeoutTime_ALL" SG_ 1178 EDS_R_Error_17 5000;
BA_ "InvalidValue" SG_ 1178 EDS_R_Error_17 "null";
BA_ "GenSigSendType" SG_ 1178 EDS_R_Error_18 4;
BA_ "GenSigTimeoutTime_ALL" SG_ 1178 EDS_R_Error_18 5000;
BA_ "InvalidValue" SG_ 1178 EDS_R_Error_18 "null";
BA_ "GenSigSendType" SG_ 1178 EDS_R_Error_19 4;
BA_ "GenSigTimeoutTime_ALL" SG_ 1178 EDS_R_Error_19 5000;
BA_ "InvalidValue" SG_ 1178 EDS_R_Error_19 "null";
BA_ "GenSigSendType" SG_ 1178 EDS_R_Error_20 4;
BA_ "GenSigTimeoutTime_ALL" SG_ 1178 EDS_R_Error_20 5000;
BA_ "InvalidValue" SG_ 1178 EDS_R_Error_20 "null";
BA_ "GenSigSendType" SG_ 1178 EDS_R_Error_21 4;
BA_ "GenSigTimeoutTime_ALL" SG_ 1178 EDS_R_Error_21 5000;
BA_ "InvalidValue" SG_ 1178 EDS_R_Error_21 "null";
BA_ "GenSigSendType" SG_ 1178 EDS_R_Error_22 4;
BA_ "GenSigTimeoutTime_ALL" SG_ 1178 EDS_R_Error_22 5000;
BA_ "InvalidValue" SG_ 1178 EDS_R_Error_22 "null";
BA_ "GenSigSendType" SG_ 1178 EDS_R_Error_23 4;
BA_ "GenSigTimeoutTime_ALL" SG_ 1178 EDS_R_Error_23 5000;
BA_ "InvalidValue" SG_ 1178 EDS_R_Error_23 "null";
BA_ "GenSigSendType" SG_ 1178 EDS_R_Error_24 4;
BA_ "GenSigTimeoutTime_ALL" SG_ 1178 EDS_R_Error_24 5000;
BA_ "InvalidValue" SG_ 1178 EDS_R_Error_24 "null";
BA_ "GenSigSendType" SG_ 1178 EDS_R_Error_25 4;
BA_ "GenSigTimeoutTime_ALL" SG_ 1178 EDS_R_Error_25 5000;
BA_ "InvalidValue" SG_ 1178 EDS_R_Error_25 "null";
BA_ "GenSigSendType" SG_ 1178 EDS_R_Error_26 4;
BA_ "GenSigTimeoutTime_ALL" SG_ 1178 EDS_R_Error_26 5000;
BA_ "InvalidValue" SG_ 1178 EDS_R_Error_26 "null";
BA_ "GenSigSendType" SG_ 1178 EDS_R_Error_27 4;
BA_ "GenSigTimeoutTime_ALL" SG_ 1178 EDS_R_Error_27 5000;
BA_ "InvalidValue" SG_ 1178 EDS_R_Error_27 "null";
BA_ "GenSigSendType" SG_ 1178 EDS_R_Error_28 4;
BA_ "GenSigTimeoutTime_ALL" SG_ 1178 EDS_R_Error_28 5000;
BA_ "InvalidValue" SG_ 1178 EDS_R_Error_28 "null";
BA_ "GenSigSendType" SG_ 1178 EDS_R_Error_29 4;
BA_ "GenSigTimeoutTime_ALL" SG_ 1178 EDS_R_Error_29 5000;
BA_ "InvalidValue" SG_ 1178 EDS_R_Error_29 "null";
BA_ "GenSigSendType" SG_ 1178 EDS_R_Error_30 4;
BA_ "GenSigTimeoutTime_ALL" SG_ 1178 EDS_R_Error_30 5000;
BA_ "InvalidValue" SG_ 1178 EDS_R_Error_30 "null";
BA_ "GenSigSendType" SG_ 1178 EDS_R_Error_31 4;
BA_ "GenSigTimeoutTime_ALL" SG_ 1178 EDS_R_Error_31 5000;
BA_ "InvalidValue" SG_ 1178 EDS_R_Error_31 "null";
BA_ "GenSigSendType" SG_ 1178 EDS_R_Error_32 4;
BA_ "GenSigTimeoutTime_ALL" SG_ 1178 EDS_R_Error_32 5000;
BA_ "InvalidValue" SG_ 1178 EDS_R_Error_32 "null";
BA_ "GenSigSendType" SG_ 1178 EDS_R_Error_33 4;
BA_ "GenSigTimeoutTime_ALL" SG_ 1178 EDS_R_Error_33 5000;
BA_ "InvalidValue" SG_ 1178 EDS_R_Error_33 "null";
BA_ "GenSigSendType" SG_ 1178 EDS_R_Error_34 4;
BA_ "GenSigTimeoutTime_ALL" SG_ 1178 EDS_R_Error_34 5000;
BA_ "InvalidValue" SG_ 1178 EDS_R_Error_34 "null";
BA_ "GenSigSendType" SG_ 1178 EDS_R_Error_35 4;
BA_ "GenSigTimeoutTime_ALL" SG_ 1178 EDS_R_Error_35 5000;
BA_ "InvalidValue" SG_ 1178 EDS_R_Error_35 "null";
BA_ "GenSigSendType" SG_ 1178 EDS_R_Error_36 4;
BA_ "GenSigTimeoutTime_ALL" SG_ 1178 EDS_R_Error_36 5000;
BA_ "InvalidValue" SG_ 1178 EDS_R_Error_36 "null";
BA_ "GenSigSendType" SG_ 1178 EDS_R_Error_37 4;
BA_ "GenSigTimeoutTime_ALL" SG_ 1178 EDS_R_Error_37 5000;
BA_ "InvalidValue" SG_ 1178 EDS_R_Error_37 "null";
BA_ "GenSigSendType" SG_ 1178 EDS_R_Error_38 4;
BA_ "GenSigTimeoutTime_ALL" SG_ 1178 EDS_R_Error_38 5000;
BA_ "InvalidValue" SG_ 1178 EDS_R_Error_38 "null";
BA_ "GenSigSendType" SG_ 1178 EDS_R_Error_39 4;
BA_ "GenSigTimeoutTime_ALL" SG_ 1178 EDS_R_Error_39 5000;
BA_ "InvalidValue" SG_ 1178 EDS_R_Error_39 "null";
BA_ "GenSigSendType" SG_ 1178 EDS_R_Error_40 4;
BA_ "GenSigTimeoutTime_ALL" SG_ 1178 EDS_R_Error_40 5000;
BA_ "InvalidValue" SG_ 1178 EDS_R_Error_40 "null";
BA_ "GenSigSendType" SG_ 1178 EDS_R_Error_41 4;
BA_ "GenSigTimeoutTime_ALL" SG_ 1178 EDS_R_Error_41 5000;
BA_ "InvalidValue" SG_ 1178 EDS_R_Error_41 "null";
BA_ "GenSigSendType" SG_ 1178 EDS_R_Error_42 4;
BA_ "GenSigTimeoutTime_ALL" SG_ 1178 EDS_R_Error_42 5000;
BA_ "InvalidValue" SG_ 1178 EDS_R_Error_42 "null";
BA_ "GenSigSendType" SG_ 1178 EDS_R_Error_43 4;
BA_ "GenSigTimeoutTime_ALL" SG_ 1178 EDS_R_Error_43 5000;
BA_ "InvalidValue" SG_ 1178 EDS_R_Error_43 "null";
BA_ "GenSigSendType" SG_ 1178 EDS_R_Error_44 4;
BA_ "GenSigTimeoutTime_ALL" SG_ 1178 EDS_R_Error_44 5000;
BA_ "InvalidValue" SG_ 1178 EDS_R_Error_44 "null";
BA_ "GenSigSendType" SG_ 1178 EDS_R_Error_45 4;
BA_ "GenSigTimeoutTime_ALL" SG_ 1178 EDS_R_Error_45 5000;
BA_ "InvalidValue" SG_ 1178 EDS_R_Error_45 "null";
BA_ "GenSigSendType" SG_ 1178 EDS_R_Error_46 4;
BA_ "GenSigTimeoutTime_ALL" SG_ 1178 EDS_R_Error_46 5000;
BA_ "InvalidValue" SG_ 1178 EDS_R_Error_46 "null";
BA_ "GenSigSendType" SG_ 1178 EDS_R_Error_47 4;
BA_ "GenSigTimeoutTime_ALL" SG_ 1178 EDS_R_Error_47 5000;
BA_ "InvalidValue" SG_ 1178 EDS_R_Error_47 "null";
BA_ "GenSigSendType" SG_ 1178 EDS_R_Error_48 4;
BA_ "GenSigTimeoutTime_ALL" SG_ 1178 EDS_R_Error_48 5000;
BA_ "InvalidValue" SG_ 1178 EDS_R_Error_48 "null";
BA_ "GenSigSendType" SG_ 1178 EDS_R_Error_49 4;
BA_ "GenSigTimeoutTime_ALL" SG_ 1178 EDS_R_Error_49 5000;
BA_ "InvalidValue" SG_ 1178 EDS_R_Error_49 "null";
BA_ "GenSigSendType" SG_ 1178 EDS_R_Error_50 4;
BA_ "GenSigTimeoutTime_ALL" SG_ 1178 EDS_R_Error_50 5000;
BA_ "InvalidValue" SG_ 1178 EDS_R_Error_50 "null";
BA_ "GenSigSendType" SG_ 1178 EDS_R_Error_51 4;
BA_ "GenSigTimeoutTime_ALL" SG_ 1178 EDS_R_Error_51 5000;
BA_ "InvalidValue" SG_ 1178 EDS_R_Error_51 "null";
BA_ "GenSigSendType" SG_ 1178 EDS_R_Error_52 4;
BA_ "GenSigTimeoutTime_ALL" SG_ 1178 EDS_R_Error_52 5000;
BA_ "InvalidValue" SG_ 1178 EDS_R_Error_52 "null";
BA_ "GenSigSendType" SG_ 1179 CHSKM_EDS_F_WarnMsg 3;
BA_ "GenSigTimeoutTime_ALL" SG_ 1179 CHSKM_EDS_F_WarnMsg 5000;
BA_ "InvalidValue" SG_ 1179 CHSKM_EDS_F_WarnMsg "null";
BA_ "GenSigSendType" SG_ 1179 ALV_EDS_F_WarnMsg 3;
BA_ "GenSigTimeoutTime_ALL" SG_ 1179 ALV_EDS_F_WarnMsg 5000;
BA_ "InvalidValue" SG_ 1179 ALV_EDS_F_WarnMsg "Fh";
BA_ "GenSigSendType" SG_ 1179 EDS_F_Error_1 4;
BA_ "GenSigTimeoutTime_ALL" SG_ 1179 EDS_F_Error_1 5000;
BA_ "InvalidValue" SG_ 1179 EDS_F_Error_1 "null";
BA_ "GenSigSendType" SG_ 1179 EDS_F_Error_2 4;
BA_ "GenSigTimeoutTime_ALL" SG_ 1179 EDS_F_Error_2 5000;
BA_ "InvalidValue" SG_ 1179 EDS_F_Error_2 "null";
BA_ "GenSigSendType" SG_ 1179 EDS_F_Error_3 4;
BA_ "GenSigTimeoutTime_ALL" SG_ 1179 EDS_F_Error_3 5000;
BA_ "InvalidValue" SG_ 1179 EDS_F_Error_3 "null";
BA_ "GenSigSendType" SG_ 1179 EDS_F_Error_4 4;
BA_ "GenSigTimeoutTime_ALL" SG_ 1179 EDS_F_Error_4 5000;
BA_ "InvalidValue" SG_ 1179 EDS_F_Error_4 "null";
BA_ "GenSigSendType" SG_ 1179 EDS_F_Error_5 4;
BA_ "GenSigTimeoutTime_ALL" SG_ 1179 EDS_F_Error_5 5000;
BA_ "InvalidValue" SG_ 1179 EDS_F_Error_5 "null";
BA_ "GenSigSendType" SG_ 1179 EDS_F_Error_6 4;
BA_ "GenSigTimeoutTime_ALL" SG_ 1179 EDS_F_Error_6 5000;
BA_ "InvalidValue" SG_ 1179 EDS_F_Error_6 "null";
BA_ "GenSigSendType" SG_ 1179 EDS_F_Error_7 4;
BA_ "GenSigTimeoutTime_ALL" SG_ 1179 EDS_F_Error_7 5000;
BA_ "InvalidValue" SG_ 1179 EDS_F_Error_7 "null";
BA_ "GenSigSendType" SG_ 1179 EDS_F_Error_8 4;
BA_ "GenSigTimeoutTime_ALL" SG_ 1179 EDS_F_Error_8 5000;
BA_ "InvalidValue" SG_ 1179 EDS_F_Error_8 "null";
BA_ "GenSigSendType" SG_ 1179 EDS_F_Error_9 4;
BA_ "GenSigTimeoutTime_ALL" SG_ 1179 EDS_F_Error_9 5000;
BA_ "InvalidValue" SG_ 1179 EDS_F_Error_9 "null";
BA_ "GenSigSendType" SG_ 1179 EDS_F_Error_10 4;
BA_ "GenSigTimeoutTime_ALL" SG_ 1179 EDS_F_Error_10 5000;
BA_ "InvalidValue" SG_ 1179 EDS_F_Error_10 "null";
BA_ "GenSigSendType" SG_ 1179 EDS_F_Error_11 4;
BA_ "GenSigTimeoutTime_ALL" SG_ 1179 EDS_F_Error_11 5000;
BA_ "InvalidValue" SG_ 1179 EDS_F_Error_11 "null";
BA_ "GenSigSendType" SG_ 1179 EDS_F_Error_12 4;
BA_ "GenSigTimeoutTime_ALL" SG_ 1179 EDS_F_Error_12 5000;
BA_ "InvalidValue" SG_ 1179 EDS_F_Error_12 "null";
BA_ "GenSigSendType" SG_ 1179 EDS_F_Error_13 4;
BA_ "GenSigTimeoutTime_ALL" SG_ 1179 EDS_F_Error_13 5000;
BA_ "InvalidValue" SG_ 1179 EDS_F_Error_13 "null";
BA_ "GenSigSendType" SG_ 1179 EDS_F_Error_14 4;
BA_ "GenSigTimeoutTime_ALL" SG_ 1179 EDS_F_Error_14 5000;
BA_ "InvalidValue" SG_ 1179 EDS_F_Error_14 "null";
BA_ "GenSigSendType" SG_ 1179 EDS_F_Error_15 4;
BA_ "GenSigTimeoutTime_ALL" SG_ 1179 EDS_F_Error_15 5000;
BA_ "InvalidValue" SG_ 1179 EDS_F_Error_15 "null";
BA_ "GenSigSendType" SG_ 1179 EDS_F_Error_16 4;
BA_ "GenSigTimeoutTime_ALL" SG_ 1179 EDS_F_Error_16 5000;
BA_ "InvalidValue" SG_ 1179 EDS_F_Error_16 "null";
BA_ "GenSigSendType" SG_ 1179 EDS_F_Error_17 4;
BA_ "GenSigTimeoutTime_ALL" SG_ 1179 EDS_F_Error_17 5000;
BA_ "InvalidValue" SG_ 1179 EDS_F_Error_17 "null";
BA_ "GenSigSendType" SG_ 1179 EDS_F_Error_18 4;
BA_ "GenSigTimeoutTime_ALL" SG_ 1179 EDS_F_Error_18 5000;
BA_ "InvalidValue" SG_ 1179 EDS_F_Error_18 "null";
BA_ "GenSigSendType" SG_ 1179 EDS_F_Error_19 4;
BA_ "GenSigTimeoutTime_ALL" SG_ 1179 EDS_F_Error_19 5000;
BA_ "InvalidValue" SG_ 1179 EDS_F_Error_19 "null";
BA_ "GenSigSendType" SG_ 1179 EDS_F_Error_20 4;
BA_ "GenSigTimeoutTime_ALL" SG_ 1179 EDS_F_Error_20 5000;
BA_ "InvalidValue" SG_ 1179 EDS_F_Error_20 "null";
BA_ "GenSigSendType" SG_ 1179 EDS_F_Error_21 4;
BA_ "GenSigTimeoutTime_ALL" SG_ 1179 EDS_F_Error_21 5000;
BA_ "InvalidValue" SG_ 1179 EDS_F_Error_21 "null";
BA_ "GenSigSendType" SG_ 1179 EDS_F_Error_22 4;
BA_ "GenSigTimeoutTime_ALL" SG_ 1179 EDS_F_Error_22 5000;
BA_ "InvalidValue" SG_ 1179 EDS_F_Error_22 "null";
BA_ "GenSigSendType" SG_ 1179 EDS_F_Error_23 4;
BA_ "GenSigTimeoutTime_ALL" SG_ 1179 EDS_F_Error_23 5000;
BA_ "InvalidValue" SG_ 1179 EDS_F_Error_23 "null";
BA_ "GenSigSendType" SG_ 1179 EDS_F_Error_24 4;
BA_ "GenSigTimeoutTime_ALL" SG_ 1179 EDS_F_Error_24 5000;
BA_ "InvalidValue" SG_ 1179 EDS_F_Error_24 "null";
BA_ "GenSigSendType" SG_ 1179 EDS_F_Error_25 4;
BA_ "GenSigTimeoutTime_ALL" SG_ 1179 EDS_F_Error_25 5000;
BA_ "InvalidValue" SG_ 1179 EDS_F_Error_25 "null";
BA_ "GenSigSendType" SG_ 1179 EDS_F_Error_26 4;
BA_ "GenSigTimeoutTime_ALL" SG_ 1179 EDS_F_Error_26 5000;
BA_ "InvalidValue" SG_ 1179 EDS_F_Error_26 "null";
BA_ "GenSigSendType" SG_ 1179 EDS_F_Error_27 4;
BA_ "GenSigTimeoutTime_ALL" SG_ 1179 EDS_F_Error_27 5000;
BA_ "InvalidValue" SG_ 1179 EDS_F_Error_27 "null";
BA_ "GenSigSendType" SG_ 1179 EDS_F_Error_28 4;
BA_ "GenSigTimeoutTime_ALL" SG_ 1179 EDS_F_Error_28 5000;
BA_ "InvalidValue" SG_ 1179 EDS_F_Error_28 "null";
BA_ "GenSigSendType" SG_ 1179 EDS_F_Error_29 4;
BA_ "GenSigTimeoutTime_ALL" SG_ 1179 EDS_F_Error_29 5000;
BA_ "InvalidValue" SG_ 1179 EDS_F_Error_29 "null";
BA_ "GenSigSendType" SG_ 1179 EDS_F_Error_30 4;
BA_ "GenSigTimeoutTime_ALL" SG_ 1179 EDS_F_Error_30 5000;
BA_ "InvalidValue" SG_ 1179 EDS_F_Error_30 "null";
BA_ "GenSigSendType" SG_ 1179 EDS_F_Error_31 4;
BA_ "GenSigTimeoutTime_ALL" SG_ 1179 EDS_F_Error_31 5000;
BA_ "InvalidValue" SG_ 1179 EDS_F_Error_31 "null";
BA_ "GenSigSendType" SG_ 1179 EDS_F_Error_32 4;
BA_ "GenSigTimeoutTime_ALL" SG_ 1179 EDS_F_Error_32 5000;
BA_ "InvalidValue" SG_ 1179 EDS_F_Error_32 "null";
BA_ "GenSigSendType" SG_ 1179 EDS_F_Error_33 4;
BA_ "GenSigTimeoutTime_ALL" SG_ 1179 EDS_F_Error_33 5000;
BA_ "InvalidValue" SG_ 1179 EDS_F_Error_33 "null";
BA_ "GenSigSendType" SG_ 1179 EDS_F_Error_34 4;
BA_ "GenSigTimeoutTime_ALL" SG_ 1179 EDS_F_Error_34 5000;
BA_ "InvalidValue" SG_ 1179 EDS_F_Error_34 "null";
BA_ "GenSigSendType" SG_ 1179 EDS_F_Error_35 4;
BA_ "GenSigTimeoutTime_ALL" SG_ 1179 EDS_F_Error_35 5000;
BA_ "InvalidValue" SG_ 1179 EDS_F_Error_35 "null";
BA_ "GenSigSendType" SG_ 1179 EDS_F_Error_36 4;
BA_ "GenSigTimeoutTime_ALL" SG_ 1179 EDS_F_Error_36 5000;
BA_ "InvalidValue" SG_ 1179 EDS_F_Error_36 "null";
BA_ "GenSigSendType" SG_ 1179 EDS_F_Error_37 4;
BA_ "GenSigTimeoutTime_ALL" SG_ 1179 EDS_F_Error_37 5000;
BA_ "InvalidValue" SG_ 1179 EDS_F_Error_37 "null";
BA_ "GenSigSendType" SG_ 1179 EDS_F_Error_38 4;
BA_ "GenSigTimeoutTime_ALL" SG_ 1179 EDS_F_Error_38 5000;
BA_ "InvalidValue" SG_ 1179 EDS_F_Error_38 "null";
BA_ "GenSigSendType" SG_ 1179 EDS_F_Error_39 4;
BA_ "GenSigTimeoutTime_ALL" SG_ 1179 EDS_F_Error_39 5000;
BA_ "InvalidValue" SG_ 1179 EDS_F_Error_39 "null";
BA_ "GenSigSendType" SG_ 1179 EDS_F_Error_40 4;
BA_ "GenSigTimeoutTime_ALL" SG_ 1179 EDS_F_Error_40 5000;
BA_ "InvalidValue" SG_ 1179 EDS_F_Error_40 "null";
BA_ "GenSigSendType" SG_ 1179 EDS_F_Error_41 4;
BA_ "GenSigTimeoutTime_ALL" SG_ 1179 EDS_F_Error_41 5000;
BA_ "InvalidValue" SG_ 1179 EDS_F_Error_41 "null";
BA_ "GenSigSendType" SG_ 1179 EDS_F_Error_42 4;
BA_ "GenSigTimeoutTime_ALL" SG_ 1179 EDS_F_Error_42 5000;
BA_ "InvalidValue" SG_ 1179 EDS_F_Error_42 "null";
BA_ "GenSigSendType" SG_ 1179 EDS_F_Error_43 4;
BA_ "GenSigTimeoutTime_ALL" SG_ 1179 EDS_F_Error_43 5000;
BA_ "InvalidValue" SG_ 1179 EDS_F_Error_43 "null";
BA_ "GenSigSendType" SG_ 1179 EDS_F_Error_44 4;
BA_ "GenSigTimeoutTime_ALL" SG_ 1179 EDS_F_Error_44 5000;
BA_ "InvalidValue" SG_ 1179 EDS_F_Error_44 "null";
BA_ "GenSigSendType" SG_ 1179 EDS_F_Error_45 4;
BA_ "GenSigTimeoutTime_ALL" SG_ 1179 EDS_F_Error_45 5000;
BA_ "InvalidValue" SG_ 1179 EDS_F_Error_45 "null";
BA_ "GenSigSendType" SG_ 1179 EDS_F_Error_46 4;
BA_ "GenSigTimeoutTime_ALL" SG_ 1179 EDS_F_Error_46 5000;
BA_ "InvalidValue" SG_ 1179 EDS_F_Error_46 "null";
BA_ "GenSigSendType" SG_ 1179 EDS_F_Error_47 4;
BA_ "GenSigTimeoutTime_ALL" SG_ 1179 EDS_F_Error_47 5000;
BA_ "InvalidValue" SG_ 1179 EDS_F_Error_47 "null";
BA_ "GenSigSendType" SG_ 1179 EDS_F_Error_48 4;
BA_ "GenSigTimeoutTime_ALL" SG_ 1179 EDS_F_Error_48 5000;
BA_ "InvalidValue" SG_ 1179 EDS_F_Error_48 "null";
BA_ "GenSigSendType" SG_ 1179 EDS_F_Error_49 4;
BA_ "GenSigTimeoutTime_ALL" SG_ 1179 EDS_F_Error_49 5000;
BA_ "InvalidValue" SG_ 1179 EDS_F_Error_49 "null";
BA_ "GenSigSendType" SG_ 1179 EDS_F_Error_50 4;
BA_ "GenSigTimeoutTime_ALL" SG_ 1179 EDS_F_Error_50 5000;
BA_ "InvalidValue" SG_ 1179 EDS_F_Error_50 "null";
BA_ "GenSigSendType" SG_ 1179 EDS_F_Error_51 4;
BA_ "GenSigTimeoutTime_ALL" SG_ 1179 EDS_F_Error_51 5000;
BA_ "InvalidValue" SG_ 1179 EDS_F_Error_51 "null";
BA_ "GenSigSendType" SG_ 1179 EDS_F_Error_52 4;
BA_ "GenSigTimeoutTime_ALL" SG_ 1179 EDS_F_Error_52 5000;
BA_ "InvalidValue" SG_ 1179 EDS_F_Error_52 "null";
BA_ "GenSigSendType" SG_ 1191 CHSKM_RCU_WarnMsg 3;
BA_ "GenSigTimeoutTime_ALL" SG_ 1191 CHSKM_RCU_WarnMsg 5000;
BA_ "GenSigSendType" SG_ 1191 ALV_RCU_WarnMsg 3;
BA_ "GenSigTimeoutTime_ALL" SG_ 1191 ALV_RCU_WarnMsg 5000;
BA_ "InvalidValue" SG_ 1191 ALV_RCU_WarnMsg "Fh";
BA_ "GenSigSendType" SG_ 1191 RCU_DAA_NoOpDoorOpen 4;
BA_ "GenSigTimeoutTime_ALL" SG_ 1191 RCU_DAA_NoOpDoorOpen 5000;
BA_ "GenSigSendType" SG_ 1191 RCU_EHandBrk_fault 4;
BA_ "GenSigTimeoutTime_ALL" SG_ 1191 RCU_EHandBrk_fault 5000;
BA_ "GenSigSendType" SG_ 1191 RCU_EOL_NotDone 4;
BA_ "GenSigTimeoutTime_ALL" SG_ 1191 RCU_EOL_NotDone 5000;
BA_ "GenSigSendType" SG_ 1191 RCU_ECD_RWU_active 4;
BA_ "GenSigTimeoutTime_ALL" SG_ 1191 RCU_ECD_RWU_active 5000;
BA_ "GenSigSendType" SG_ 1191 RCU_ParkOnSteepInclination 4;
BA_ "GenSigTimeoutTime_ALL" SG_ 1191 RCU_ParkOnSteepInclination 5000;
BA_ "GenSigSendType" SG_ 1191 RCU_BrkForceNotEnough 4;
BA_ "GenSigTimeoutTime_ALL" SG_ 1191 RCU_BrkForceNotEnough 5000;
BA_ "GenSigSendType" SG_ 1191 RCU_ReleaseEPB_Wo_PressBrk 4;
BA_ "GenSigTimeoutTime_ALL" SG_ 1191 RCU_ReleaseEPB_Wo_PressBrk 5000;
BA_ "GenSigSendType" SG_ 1191 RCU_ParkBrkApplied 4;
BA_ "GenSigTimeoutTime_ALL" SG_ 1191 RCU_ParkBrkApplied 5000;
BA_ "GenSigSendType" SG_ 1191 RCU_Swch_Mafnc 4;
BA_ "GenSigTimeoutTime_ALL" SG_ 1191 RCU_Swch_Mafnc 5000;
BA_ "GenSigSendType" SG_ 1191 RCU_DAA_NoOpBeltUnbuckled 4;
BA_ "GenSigTimeoutTime_ALL" SG_ 1191 RCU_DAA_NoOpBeltUnbuckled 5000;
BA_ "GenSigSendType" SG_ 1191 RCU_RollerBenchMode 4;
BA_ "GenSigTimeoutTime_ALL" SG_ 1191 RCU_RollerBenchMode 5000;
BA_ "GenSigSendType" SG_ 1191 RCU_EPB_ParkLampState 4;
BA_ "GenSigTimeoutTime_ALL" SG_ 1191 RCU_EPB_ParkLampState 5000;
BA_ "GenSigSendType" SG_ 1191 RCU_EPB_WarnLampState 4;
BA_ "GenSigTimeoutTime_ALL" SG_ 1191 RCU_EPB_WarnLampState 5000;
BA_ "GenSigSendType" SG_ 1191 RCU_WflagRes36 4;
BA_ "GenSigTimeoutTime_ALL" SG_ 1191 RCU_WflagRes36 5000;
BA_ "InvalidValue" SG_ 1191 RCU_WflagRes36 "null";
BA_ "GenSigSendType" SG_ 1191 RCU_WflagRes37 4;
BA_ "GenSigTimeoutTime_ALL" SG_ 1191 RCU_WflagRes37 5000;
BA_ "InvalidValue" SG_ 1191 RCU_WflagRes37 "null";
BA_ "GenSigSendType" SG_ 1191 RCU_WflagRes38 4;
BA_ "GenSigTimeoutTime_ALL" SG_ 1191 RCU_WflagRes38 5000;
BA_ "InvalidValue" SG_ 1191 RCU_WflagRes38 "null";
BA_ "GenSigSendType" SG_ 1191 RCU_WflagRes39 4;
BA_ "GenSigTimeoutTime_ALL" SG_ 1191 RCU_WflagRes39 5000;
BA_ "InvalidValue" SG_ 1191 RCU_WflagRes39 "null";
BA_ "GenSigSendType" SG_ 1191 RCU_WflagRes40 4;
BA_ "GenSigTimeoutTime_ALL" SG_ 1191 RCU_WflagRes40 5000;
BA_ "InvalidValue" SG_ 1191 RCU_WflagRes40 "null";
BA_ "GenSigSendType" SG_ 1191 RCU_WflagRes41 4;
BA_ "GenSigTimeoutTime_ALL" SG_ 1191 RCU_WflagRes41 5000;
BA_ "InvalidValue" SG_ 1191 RCU_WflagRes41 "null";
BA_ "GenSigSendType" SG_ 1191 RCU_WflagRes42 4;
BA_ "GenSigTimeoutTime_ALL" SG_ 1191 RCU_WflagRes42 5000;
BA_ "InvalidValue" SG_ 1191 RCU_WflagRes42 "null";
BA_ "GenSigSendType" SG_ 1191 RCU_WflagRes43 4;
BA_ "GenSigTimeoutTime_ALL" SG_ 1191 RCU_WflagRes43 5000;
BA_ "GenSigSendType" SG_ 1191 RCU_WflagRes44 4;
BA_ "GenSigTimeoutTime_ALL" SG_ 1191 RCU_WflagRes44 5000;
BA_ "GenSigSendType" SG_ 1191 RCU_WflagRes45 4;
BA_ "GenSigTimeoutTime_ALL" SG_ 1191 RCU_WflagRes45 5000;
BA_ "GenSigSendType" SG_ 1191 RCU_WflagRes46 4;
BA_ "GenSigTimeoutTime_ALL" SG_ 1191 RCU_WflagRes46 5000;
BA_ "GenSigSendType" SG_ 1191 RCU_WflagRes47 4;
BA_ "GenSigTimeoutTime_ALL" SG_ 1191 RCU_WflagRes47 5000;
BA_ "GenSigSendType" SG_ 1191 RCU_Reserved_signal1 4;
BA_ "GenSigTimeoutTime_ALL" SG_ 1191 RCU_Reserved_signal1 5000;
BA_ "InvalidValue" SG_ 1191 RCU_Reserved_signal1 "null";
BA_ "GenSigSendType" SG_ 1192 CHSKM_EPS_WarnMsg 3;
BA_ "GenSigTimeoutTime_ALL" SG_ 1192 CHSKM_EPS_WarnMsg 5000;
BA_ "InvalidValue" SG_ 1192 CHSKM_EPS_WarnMsg "null";
BA_ "GenSigSendType" SG_ 1192 ALV_EPS_WarnMsg 3;
BA_ "GenSigTimeoutTime_ALL" SG_ 1192 ALV_EPS_WarnMsg 5000;
BA_ "InvalidValue" SG_ 1192 ALV_EPS_WarnMsg "Fh";
BA_ "GenSigSendType" SG_ 1192 EPS_Malfunction 4;
BA_ "GenSigTimeoutTime_ALL" SG_ 1192 EPS_Malfunction 5000;
BA_ "InvalidValue" SG_ 1192 EPS_Malfunction "null";
BA_ "GenSigSendType" SG_ 1192 EPS_Reduced 4;
BA_ "GenSigTimeoutTime_ALL" SG_ 1192 EPS_Reduced 5000;
BA_ "InvalidValue" SG_ 1192 EPS_Reduced "null";
BA_ "GenSigSendType" SG_ 1192 EPS_Overheat 4;
BA_ "GenSigTimeoutTime_ALL" SG_ 1192 EPS_Overheat 5000;
BA_ "InvalidValue" SG_ 1192 EPS_Overheat "null";
BA_ "GenSigSendType" SG_ 1192 EPS_NotReady 4;
BA_ "GenSigTimeoutTime_ALL" SG_ 1192 EPS_NotReady 5000;
BA_ "InvalidValue" SG_ 1192 EPS_NotReady "null";
BA_ "GenSigSendType" SG_ 1192 EPS_Warning_Flag_5 4;
BA_ "GenSigTimeoutTime_ALL" SG_ 1192 EPS_Warning_Flag_5 5000;
BA_ "InvalidValue" SG_ 1192 EPS_Warning_Flag_5 "null";
BA_ "GenSigSendType" SG_ 1192 EPS_Warning_Flag_6 4;
BA_ "GenSigTimeoutTime_ALL" SG_ 1192 EPS_Warning_Flag_6 5000;
BA_ "InvalidValue" SG_ 1192 EPS_Warning_Flag_6 "null";
BA_ "GenSigSendType" SG_ 1192 EPS_Warning_Flag_7 4;
BA_ "GenSigTimeoutTime_ALL" SG_ 1192 EPS_Warning_Flag_7 5000;
BA_ "InvalidValue" SG_ 1192 EPS_Warning_Flag_7 "null";
BA_ "GenSigSendType" SG_ 1192 EPS_Warning_Flag_8 4;
BA_ "GenSigTimeoutTime_ALL" SG_ 1192 EPS_Warning_Flag_8 5000;
BA_ "InvalidValue" SG_ 1192 EPS_Warning_Flag_8 "null";
BA_ "GenSigSendType" SG_ 1192 EPS_Warning_Flag_9 4;
BA_ "GenSigTimeoutTime_ALL" SG_ 1192 EPS_Warning_Flag_9 5000;
BA_ "InvalidValue" SG_ 1192 EPS_Warning_Flag_9 "null";
BA_ "GenSigSendType" SG_ 1192 EPS_Warning_Flag_10 4;
BA_ "GenSigTimeoutTime_ALL" SG_ 1192 EPS_Warning_Flag_10 5000;
BA_ "InvalidValue" SG_ 1192 EPS_Warning_Flag_10 "null";
BA_ "GenSigSendType" SG_ 1192 EPS_Warning_Flag_11 4;
BA_ "GenSigTimeoutTime_ALL" SG_ 1192 EPS_Warning_Flag_11 5000;
BA_ "InvalidValue" SG_ 1192 EPS_Warning_Flag_11 "null";
BA_ "GenSigSendType" SG_ 1192 EPS_Warning_Flag_12 4;
BA_ "GenSigTimeoutTime_ALL" SG_ 1192 EPS_Warning_Flag_12 5000;
BA_ "InvalidValue" SG_ 1192 EPS_Warning_Flag_12 "null";
BA_ "GenSigSendType" SG_ 1192 EPS_Reserved_signal1 4;
BA_ "GenSigTimeoutTime_ALL" SG_ 1192 EPS_Reserved_signal1 5000;
BA_ "InvalidValue" SG_ 1192 EPS_Reserved_signal1 "null";
BA_ "GenSigSendType" SG_ 1192 EPS_Reserved_signal2 4;
BA_ "GenSigTimeoutTime_ALL" SG_ 1192 EPS_Reserved_signal2 5000;
BA_ "InvalidValue" SG_ 1192 EPS_Reserved_signal2 "null";
BA_ "GenSigSendType" SG_ 1192 EPS_Reserved_signal3 4;
BA_ "GenSigTimeoutTime_ALL" SG_ 1192 EPS_Reserved_signal3 5000;
BA_ "InvalidValue" SG_ 1192 EPS_Reserved_signal3 "null";
BA_ "GenSigSendType" SG_ 1192 EPS_Reserved_signal4 4;
BA_ "GenSigTimeoutTime_ALL" SG_ 1192 EPS_Reserved_signal4 5000;
BA_ "InvalidValue" SG_ 1192 EPS_Reserved_signal4 "null";
BA_ "GenSigSendType" SG_ 1192 EPS_Reserved_signal5 4;
BA_ "GenSigTimeoutTime_ALL" SG_ 1192 EPS_Reserved_signal5 5000;
BA_ "InvalidValue" SG_ 1192 EPS_Reserved_signal5 "null";
BA_ "GenSigSendType" SG_ 1193 CHSKM_IDB_WarnMsg 3;
BA_ "GenSigTimeoutTime_ALL" SG_ 1193 CHSKM_IDB_WarnMsg 5000;
BA_ "InvalidValue" SG_ 1193 CHSKM_IDB_WarnMsg "null";
BA_ "GenSigSendType" SG_ 1193 ALV_IDB_WarnMsg 3;
BA_ "GenSigTimeoutTime_ALL" SG_ 1193 ALV_IDB_WarnMsg 5000;
BA_ "InvalidValue" SG_ 1193 ALV_IDB_WarnMsg "Fh";
BA_ "GenSigSendType" SG_ 1193 IDB_ESC_fault 4;
BA_ "GenSigTimeoutTime_ALL" SG_ 1193 IDB_ESC_fault 5000;
BA_ "InvalidValue" SG_ 1193 IDB_ESC_fault "null";
BA_ "GenSigSendType" SG_ 1193 IDB_ABS_fault 4;
BA_ "GenSigTimeoutTime_ALL" SG_ 1193 IDB_ABS_fault 5000;
BA_ "InvalidValue" SG_ 1193 IDB_ABS_fault "null";
BA_ "GenSigSendType" SG_ 1193 IDB_BrkLowFluid 4;
BA_ "GenSigTimeoutTime_ALL" SG_ 1193 IDB_BrkLowFluid 5000;
BA_ "InvalidValue" SG_ 1193 IDB_BrkLowFluid "null";
BA_ "GenSigSendType" SG_ 1193 IDB_BrkSysFault 4;
BA_ "GenSigTimeoutTime_ALL" SG_ 1193 IDB_BrkSysFault 5000;
BA_ "InvalidValue" SG_ 1193 IDB_BrkSysFault "null";
BA_ "GenSigSendType" SG_ 1193 IDB_fault 4;
BA_ "GenSigTimeoutTime_ALL" SG_ 1193 IDB_fault 5000;
BA_ "InvalidValue" SG_ 1193 IDB_fault "null";
BA_ "GenSigSendType" SG_ 1193 IDB_HydraulicBrkAssist_Fault 4;
BA_ "GenSigTimeoutTime_ALL" SG_ 1193 IDB_HydraulicBrkAssist_Fault 5000;
BA_ "InvalidValue" SG_ 1193 IDB_HydraulicBrkAssist_Fault "null";
BA_ "GenSigSendType" SG_ 1193 IDB_HAS_Fault 4;
BA_ "GenSigTimeoutTime_ALL" SG_ 1193 IDB_HAS_Fault 5000;
BA_ "InvalidValue" SG_ 1193 IDB_HAS_Fault "null";
BA_ "GenSigSendType" SG_ 1193 IDB_TSM_Fault 4;
BA_ "GenSigTimeoutTime_ALL" SG_ 1193 IDB_TSM_Fault 5000;
BA_ "InvalidValue" SG_ 1193 IDB_TSM_Fault "null";
BA_ "GenSigSendType" SG_ 1193 IDB_Reserved_signal2 4;
BA_ "GenSigTimeoutTime_ALL" SG_ 1193 IDB_Reserved_signal2 5000;
BA_ "InvalidValue" SG_ 1193 IDB_Reserved_signal2 "null";
BA_ "GenSigSendType" SG_ 1193 IDB_Reserved_signal3 4;
BA_ "GenSigTimeoutTime_ALL" SG_ 1193 IDB_Reserved_signal3 5000;
BA_ "InvalidValue" SG_ 1193 IDB_Reserved_signal3 "null";
BA_ "GenSigSendType" SG_ 1193 IDB_Reserved_signal4 4;
BA_ "GenSigTimeoutTime_ALL" SG_ 1193 IDB_Reserved_signal4 5000;
BA_ "InvalidValue" SG_ 1193 IDB_Reserved_signal4 "null";
BA_ "GenSigSendType" SG_ 1193 IDB_Reserved_signal5 4;
BA_ "GenSigTimeoutTime_ALL" SG_ 1193 IDB_Reserved_signal5 5000;
BA_ "InvalidValue" SG_ 1193 IDB_Reserved_signal5 "null";
BA_ "GenSigSendType" SG_ 1196 CHSKM_VCU_WarnMsg 3;
BA_ "GenSigTimeoutTime_ALL" SG_ 1196 CHSKM_VCU_WarnMsg 5000;
BA_ "GenSigSendType" SG_ 1196 ALV_VCU_WarnMsg 3;
BA_ "GenSigTimeoutTime_ALL" SG_ 1196 ALV_VCU_WarnMsg 5000;
BA_ "InvalidValue" SG_ 1196 ALV_VCU_WarnMsg "Fh";
BA_ "GenSigSendType" SG_ 1196 VCU_GearPOnlyAtStationaryAlert 4;
BA_ "GenSigTimeoutTime_ALL" SG_ 1196 VCU_GearPOnlyAtStationaryAlert 5000;
BA_ "GenSigSendType" SG_ 1196 VCU_GearP_NotPossibleAlert 4;
BA_ "GenSigTimeoutTime_ALL" SG_ 1196 VCU_GearP_NotPossibleAlert 5000;
BA_ "GenSigSendType" SG_ 1196 VCU_PressBrakeToEngageGear 4;
BA_ "GenSigTimeoutTime_ALL" SG_ 1196 VCU_PressBrakeToEngageGear 5000;
BA_ "GenSigSendType" SG_ 1196 VCU_CantChangeGear 4;
BA_ "GenSigTimeoutTime_ALL" SG_ 1196 VCU_CantChangeGear 5000;
BA_ "GenSigSendType" SG_ 1196 VCU_GearMalfunction 4;
BA_ "GenSigTimeoutTime_ALL" SG_ 1196 VCU_GearMalfunction 5000;
BA_ "GenSigSendType" SG_ 1196 VCU_RangeAlert 4;
BA_ "GenSigTimeoutTime_ALL" SG_ 1196 VCU_RangeAlert 5000;
BA_ "GenSigSendType" SG_ 1196 VCU_HVSystemReduced 4;
BA_ "GenSigTimeoutTime_ALL" SG_ 1196 VCU_HVSystemReduced 5000;
BA_ "GenSigSendType" SG_ 1196 VCU_FrontEDSReduced 4;
BA_ "GenSigTimeoutTime_ALL" SG_ 1196 VCU_FrontEDSReduced 5000;
BA_ "GenSigSendType" SG_ 1196 VCU_FrontEDS_Malfunc 4;
BA_ "GenSigTimeoutTime_ALL" SG_ 1196 VCU_FrontEDS_Malfunc 5000;
BA_ "GenSigSendType" SG_ 1196 VCU_RearEDSReduced 4;
BA_ "GenSigTimeoutTime_ALL" SG_ 1196 VCU_RearEDSReduced 5000;
BA_ "GenSigSendType" SG_ 1196 VCU_RearEDS_Malfunc 4;
BA_ "GenSigTimeoutTime_ALL" SG_ 1196 VCU_RearEDS_Malfunc 5000;
BA_ "GenSigSendType" SG_ 1196 VCU_CoolingSystem_Malfunc 4;
BA_ "GenSigTimeoutTime_ALL" SG_ 1196 VCU_CoolingSystem_Malfunc 5000;
BA_ "GenSigSendType" SG_ 1196 VCU_NeutralRequest 4;
BA_ "GenSigTimeoutTime_ALL" SG_ 1196 VCU_NeutralRequest 5000;
BA_ "GenSigSendType" SG_ 1196 VCU_SoftShutdown 4;
BA_ "GenSigTimeoutTime_ALL" SG_ 1196 VCU_SoftShutdown 5000;
BA_ "GenSigSendType" SG_ 1196 VCU_EmergencyShutdown 4;
BA_ "GenSigTimeoutTime_ALL" SG_ 1196 VCU_EmergencyShutdown 5000;
BA_ "GenSigSendType" SG_ 1196 VCU_ChgPortDoorSys_Malfunc 4;
BA_ "GenSigTimeoutTime_ALL" SG_ 1196 VCU_ChgPortDoorSys_Malfunc 5000;
BA_ "GenSigSendType" SG_ 1196 VCU_Gearchange_NotPossible 4;
BA_ "GenSigTimeoutTime_ALL" SG_ 1196 VCU_Gearchange_NotPossible 5000;
BA_ "GenSigTimeoutTime_ALL" SG_ 1196 VCU_Gearchange_NotPossible 5000;
BA_ "GenSigSendType" SG_ 1196 VCU_12v_Warning 4;
BA_ "GenSigTimeoutTime_ALL" SG_ 1196 VCU_12v_Warning 5000;
BA_ "GenSigSendType" SG_ 1196 VCU_WflagRes19 4;
BA_ "GenSigTimeoutTime_ALL" SG_ 1196 VCU_WflagRes19 5000;
BA_ "GenSigSendType" SG_ 1196 VCU_WflagRes20 4;
BA_ "GenSigTimeoutTime_ALL" SG_ 1196 VCU_WflagRes20 5000;
BA_ "GenSigSendType" SG_ 1196 VCU_WflagRes21 4;
BA_ "GenSigTimeoutTime_ALL" SG_ 1196 VCU_WflagRes21 5000;
BA_ "GenSigSendType" SG_ 1196 VCU_WflagRes22 4;
BA_ "GenSigTimeoutTime_ALL" SG_ 1196 VCU_WflagRes22 5000;
BA_ "GenSigSendType" SG_ 1196 VCU_WflagRes23 4;
BA_ "GenSigTimeoutTime_ALL" SG_ 1196 VCU_WflagRes23 5000;
BA_ "GenSigSendType" SG_ 1196 VCU_WflagRes24 4;
BA_ "GenSigTimeoutTime_ALL" SG_ 1196 VCU_WflagRes24 5000;
BA_ "GenSigSendType" SG_ 1196 VCU_WflagRes25 4;
BA_ "GenSigTimeoutTime_ALL" SG_ 1196 VCU_WflagRes25 5000;
BA_ "GenSigSendType" SG_ 1196 VCU_WflagRes26 4;
BA_ "GenSigTimeoutTime_ALL" SG_ 1196 VCU_WflagRes26 5000;
BA_ "GenSigSendType" SG_ 1196 VCU_WflagRes27 4;
BA_ "GenSigTimeoutTime_ALL" SG_ 1196 VCU_WflagRes27 5000;
BA_ "GenSigSendType" SG_ 1196 VCU_SuperFastCharge_longer 4;
BA_ "GenSigTimeoutTime_ALL" SG_ 1196 VCU_SuperFastCharge_longer 5000;
BA_ "GenSigTimeoutTime_ALL" SG_ 1196 VCU_SuperFastCharge_longer 5000;
BA_ "GenSigSendType" SG_ 1196 VCU_Reserved_signal1 4;
BA_ "GenSigTimeoutTime_ALL" SG_ 1196 VCU_Reserved_signal1 5000;
BA_ "GenSigSendType" SG_ 1196 VCU_Reserved_signal2 4;
BA_ "GenSigTimeoutTime_ALL" SG_ 1196 VCU_Reserved_signal2 5000;
BA_ "GenSigSendType" SG_ 1196 VCU_Reserved_signal3 4;
BA_ "GenSigTimeoutTime_ALL" SG_ 1196 VCU_Reserved_signal3 5000;
BA_ "GenSigSendType" SG_ 1198 CHSKM_EASC_WarnMsg 3;
BA_ "GenSigTimeoutTime_ALL" SG_ 1198 CHSKM_EASC_WarnMsg 5000;
BA_ "GenSigSendType" SG_ 1198 ALV_EASC_WarnMsg 3;
BA_ "GenSigTimeoutTime_ALL" SG_ 1198 ALV_EASC_WarnMsg 5000;
BA_ "InvalidValue" SG_ 1198 ALV_EASC_WarnMsg "Fh";
BA_ "GenSigSendType" SG_ 1198 EASC_Warning_Flag_1 4;
BA_ "GenSigTimeoutTime_ALL" SG_ 1198 EASC_Warning_Flag_1 5000;
BA_ "GenSigSendType" SG_ 1198 EASC_Warning_Flag_2 4;
BA_ "GenSigTimeoutTime_ALL" SG_ 1198 EASC_Warning_Flag_2 5000;
BA_ "GenSigSendType" SG_ 1198 EASC_Warning_Flag_3 4;
BA_ "GenSigTimeoutTime_ALL" SG_ 1198 EASC_Warning_Flag_3 5000;
BA_ "GenSigSendType" SG_ 1198 EASC_Warning_Flag_4 4;
BA_ "GenSigTimeoutTime_ALL" SG_ 1198 EASC_Warning_Flag_4 5000;
BA_ "GenSigSendType" SG_ 1198 EASC_Warning_Flag_5 4;
BA_ "GenSigTimeoutTime_ALL" SG_ 1198 EASC_Warning_Flag_5 5000;
BA_ "GenSigSendType" SG_ 1198 EASC_Warning_Flag_6 4;
BA_ "GenSigTimeoutTime_ALL" SG_ 1198 EASC_Warning_Flag_6 5000;
BA_ "GenSigSendType" SG_ 1198 EASC_Warning_Flag_7 4;
BA_ "GenSigTimeoutTime_ALL" SG_ 1198 EASC_Warning_Flag_7 5000;
BA_ "GenSigSendType" SG_ 1198 EASC_Warning_Flag_8 4;
BA_ "GenSigTimeoutTime_ALL" SG_ 1198 EASC_Warning_Flag_8 5000;
BA_ "GenSigSendType" SG_ 1198 EASC_Warning_Flag_9 4;
BA_ "GenSigTimeoutTime_ALL" SG_ 1198 EASC_Warning_Flag_9 5000;
BA_ "GenSigSendType" SG_ 1198 EASC_Warning_Flag_10 4;
BA_ "GenSigTimeoutTime_ALL" SG_ 1198 EASC_Warning_Flag_10 5000;
BA_ "GenSigSendType" SG_ 1198 EASC_Warning_Flag_11 4;
BA_ "GenSigTimeoutTime_ALL" SG_ 1198 EASC_Warning_Flag_11 5000;
BA_ "GenSigSendType" SG_ 1198 EASC_Warning_Flag_12 4;
BA_ "GenSigTimeoutTime_ALL" SG_ 1198 EASC_Warning_Flag_12 5000;
BA_ "GenSigSendType" SG_ 1198 EASC_Reserved_signal1 4;
BA_ "GenSigTimeoutTime_ALL" SG_ 1198 EASC_Reserved_signal1 5000;
BA_ "GenSigSendType" SG_ 1198 EASC_Reserved_signal2 4;
BA_ "GenSigTimeoutTime_ALL" SG_ 1198 EASC_Reserved_signal2 5000;
BA_ "GenSigSendType" SG_ 1198 EASC_Reserved_signal3 4;
BA_ "GenSigTimeoutTime_ALL" SG_ 1198 EASC_Reserved_signal3 5000;
BA_ "GenSigSendType" SG_ 1198 EASC_Reserved_signal4 4;
BA_ "GenSigTimeoutTime_ALL" SG_ 1198 EASC_Reserved_signal4 5000;
BA_ "GenSigSendType" SG_ 1198 EASC_Reserved_signal5 4;
BA_ "GenSigTimeoutTime_ALL" SG_ 1198 EASC_Reserved_signal5 5000;
BA_ "GenSigSendType" SG_ 1199 CHSKM_CPD_WarnMsg 3;
BA_ "GenSigTimeoutTime_ALL" SG_ 1199 CHSKM_CPD_WarnMsg 5000;
BA_ "GenSigSendType" SG_ 1199 ALV_CPD_WarnMsg 3;
BA_ "GenSigTimeoutTime_ALL" SG_ 1199 ALV_CPD_WarnMsg 5000;
BA_ "InvalidValue" SG_ 1199 ALV_CPD_WarnMsg "Fh";
BA_ "GenSigSendType" SG_ 1199 CPD_Malfunction 4;
BA_ "GenSigTimeoutTime_ALL" SG_ 1199 CPD_Malfunction 5000;
BA_ "GenSigSendType" SG_ 1199 CPD_SensorFault 4;
BA_ "GenSigTimeoutTime_ALL" SG_ 1199 CPD_SensorFault 5000;
BA_ "InvalidValue" SG_ 1199 CPD_SensorFault "3h";
BA_ "GenSigSendType" SG_ 1199 CPD_Warning_Flag_4 4;
BA_ "GenSigTimeoutTime_ALL" SG_ 1199 CPD_Warning_Flag_4 5000;
BA_ "GenSigSendType" SG_ 1199 CPD_Warning_Flag_5 4;
BA_ "GenSigTimeoutTime_ALL" SG_ 1199 CPD_Warning_Flag_5 5000;
BA_ "GenSigSendType" SG_ 1199 CPD_Warning_Flag_6 4;
BA_ "GenSigTimeoutTime_ALL" SG_ 1199 CPD_Warning_Flag_6 5000;
BA_ "GenSigSendType" SG_ 1199 CPD_Warning_Flag_7 4;
BA_ "GenSigTimeoutTime_ALL" SG_ 1199 CPD_Warning_Flag_7 5000;
BA_ "GenSigSendType" SG_ 1199 CPD_Warning_Flag_8 4;
BA_ "GenSigTimeoutTime_ALL" SG_ 1199 CPD_Warning_Flag_8 5000;
BA_ "GenSigSendType" SG_ 1199 CPD_Warning_Flag_9 4;
BA_ "GenSigTimeoutTime_ALL" SG_ 1199 CPD_Warning_Flag_9 5000;
BA_ "GenSigSendType" SG_ 1199 CPD_Warning_Flag_10 4;
BA_ "GenSigTimeoutTime_ALL" SG_ 1199 CPD_Warning_Flag_10 5000;
BA_ "GenSigSendType" SG_ 1199 CPD_Warning_Flag_11 4;
BA_ "GenSigTimeoutTime_ALL" SG_ 1199 CPD_Warning_Flag_11 5000;
BA_ "GenSigSendType" SG_ 1199 CPD_Warning_Flag_12 4;
BA_ "GenSigTimeoutTime_ALL" SG_ 1199 CPD_Warning_Flag_12 5000;
BA_ "GenSigSendType" SG_ 1199 CPD_Reserved_signal1 4;
BA_ "GenSigTimeoutTime_ALL" SG_ 1199 CPD_Reserved_signal1 5000;
BA_ "GenSigSendType" SG_ 1199 CPD_Reserved_signal2 4;
BA_ "GenSigTimeoutTime_ALL" SG_ 1199 CPD_Reserved_signal2 5000;
BA_ "GenSigSendType" SG_ 1199 CPD_Reserved_signal3 4;
BA_ "GenSigTimeoutTime_ALL" SG_ 1199 CPD_Reserved_signal3 5000;
BA_ "GenSigSendType" SG_ 1199 CPD_Reserved_signal4 4;
BA_ "GenSigTimeoutTime_ALL" SG_ 1199 CPD_Reserved_signal4 5000;
BA_ "GenSigSendType" SG_ 1199 CPD_Reserved_signal5 4;
BA_ "GenSigTimeoutTime_ALL" SG_ 1199 CPD_Reserved_signal5 5000;
VAL_ 1094 MHU_DrivingSide 0 "Left handside" 1 "Right handside";
VAL_ 1094 MHU_Junction_type 0 "Single intersection" 1 "Roundabout" 2 "Reserved" 3 "Signal Invalid";
VAL_ 1094 MHU_JunctionElement1 0 "No direction" 1 "direction 1 (162deg)" 2 "direction 2 (144deg)" 3 "direction 3 (126deg)" 4 "direction 4 (108deg)" 5 "direction 5 (90deg) - Right" 6 "direction 6 (72deg)" 7 "direction 7 (54deg)" 8 "direction 8 (36deg)" 9 "direction 9 (18deg)" 10 "direction 10 (0 deg) - Top" 11 "direction 11 (-18deg)" 12 "direction 12 (-36deg)" 13 "direction 13 (-54deg)" 14 "direction 14 (-72deg)" 15 "direction 15 (-90) - Left" 16 "direction 16 (-108)" 17 "direction 17 (-126)" 18 "direction 18 (-144)" 19 "direction 19 (-162)" 20 "Left U-turn (-180)" 21 "Right U-turn (180)";
VAL_ 1094 MHU_JunctionElement0 0 "No direction" 1 "direction 1 (162deg)" 2 "direction 2 (144deg)" 3 "direction 3 (126deg)" 4 "direction 4 (108deg)" 5 "direction 5 (90deg) - Right" 6 "direction 6 (72deg)" 7 "direction 7 (54deg)" 8 "direction 8 (36deg)" 9 "direction 9 (18deg)" 10 "direction 10 (0 deg) - Top" 11 "direction 11 (-18deg)" 12 "direction 12 (-36deg)" 13 "direction 13 (-54deg)" 14 "direction 14 (-72deg)" 15 "direction 15 (-90) - Left" 16 "direction 16 (-108)" 17 "direction 17 (-126)" 18 "direction 18 (-144)" 19 "direction 19 (-162)" 20 "Left U-turn (-180)" 21 "Right U-turn (180)";
VAL_ 1094 MHU_JunctionElement2 0 "No direction" 1 "direction 1 (162deg)" 2 "direction 2 (144deg)" 3 "direction 3 (126deg)" 4 "direction 4 (108deg)" 5 "direction 5 (90deg) - Right" 6 "direction 6 (72deg)" 7 "direction 7 (54deg)" 8 "direction 8 (36deg)" 9 "direction 9 (18deg)" 10 "direction 10 (0 deg) - Top" 11 "direction 11 (-18deg)" 12 "direction 12 (-36deg)" 13 "direction 13 (-54deg)" 14 "direction 14 (-72deg)" 15 "direction 15 (-90) - Left" 16 "direction 16 (-108)" 17 "direction 17 (-126)" 18 "direction 18 (-144)" 19 "direction 19 (-162)" 20 "Left U-turn (-180)" 21 "Right U-turn (180)";
VAL_ 1094 MHU_JunctionElement4 0 "No direction" 1 "direction 1 (162deg)" 2 "direction 2 (144deg)" 3 "direction 3 (126deg)" 4 "direction 4 (108deg)" 5 "direction 5 (90deg) - Right" 6 "direction 6 (72deg)" 7 "direction 7 (54deg)" 8 "direction 8 (36deg)" 9 "direction 9 (18deg)" 10 "direction 10 (0 deg) - Top" 11 "direction 11 (-18deg)" 12 "direction 12 (-36deg)" 13 "direction 13 (-54deg)" 14 "direction 14 (-72deg)" 15 "direction 15 (-90) - Left" 16 "direction 16 (-108)" 17 "direction 17 (-126)" 18 "direction 18 (-144)" 19 "direction 19 (-162)" 20 "Left U-turn (-180)" 21 "Right U-turn (180)";
VAL_ 1094 MHU_JunctionElement3 0 "No direction" 1 "direction 1 (162deg)" 2 "direction 2 (144deg)" 3 "direction 3 (126deg)" 4 "direction 4 (108deg)" 5 "direction 5 (90deg) - Right" 6 "direction 6 (72deg)" 7 "direction 7 (54deg)" 8 "direction 8 (36deg)" 9 "direction 9 (18deg)" 10 "direction 10 (0 deg) - Top" 11 "direction 11 (-18deg)" 12 "direction 12 (-36deg)" 13 "direction 13 (-54deg)" 14 "direction 14 (-72deg)" 15 "direction 15 (-90) - Left" 16 "direction 16 (-108)" 17 "direction 17 (-126)" 18 "direction 18 (-144)" 19 "direction 19 (-162)" 20 "Left U-turn (-180)" 21 "Right U-turn (180)";
VAL_ 1094 MHU_JunctionElement5 0 "No direction" 1 "direction 1 (162deg)" 2 "direction 2 (144deg)" 3 "direction 3 (126deg)" 4 "direction 4 (108deg)" 5 "direction 5 (90deg) - Right" 6 "direction 6 (72deg)" 7 "direction 7 (54deg)" 8 "direction 8 (36deg)" 9 "direction 9 (18deg)" 10 "direction 10 (0 deg) - Top" 11 "direction 11 (-18deg)" 12 "direction 12 (-36deg)" 13 "direction 13 (-54deg)" 14 "direction 14 (-72deg)" 15 "direction 15 (-90) - Left" 16 "direction 16 (-108)" 17 "direction 17 (-126)" 18 "direction 18 (-144)" 19 "direction 19 (-162)" 20 "Left U-turn (-180)" 21 "Right U-turn (180)";
VAL_ 1094 MHU_JunctionElement6 0 "No direction" 1 "direction 1 (162deg)" 2 "direction 2 (144deg)" 3 "direction 3 (126deg)" 4 "direction 4 (108deg)" 5 "direction 5 (90deg) - Right" 6 "direction 6 (72deg)" 7 "direction 7 (54deg)" 8 "direction 8 (36deg)" 9 "direction 9 (18deg)" 10 "direction 10 (0 deg) - Top" 11 "direction 11 (-18deg)" 12 "direction 12 (-36deg)" 13 "direction 13 (-54deg)" 14 "direction 14 (-72deg)" 15 "direction 15 (-90) - Left" 16 "direction 16 (-108)" 17 "direction 17 (-126)" 18 "direction 18 (-144)" 19 "direction 19 (-162)" 20 "Left U-turn (-180)" 21 "Right U-turn (180)";
VAL_ 1095 MHU_SET_TransportMode 0 "No request" 1 "Request ON"  2 "Request OFF" 3 "Signal Invalid";
VAL_ 1095 MHU_Request_CarOFF 0 "Not Request" 1 "Request Car goes to OFF" 2 "Reserved" 3 "Signal Invalid";
VAL_ 1095 MHU_SET_ChildMode 0 "Child Mode OFF" 1 "Child mode ON" 2 "Reserved" 3 "Signal Invalid";
VAL_ 1095 MHU_SET_GameMode 0 "Game mode OFF" 1 "Game mode ON" 2 "Reserved" 3 "Signal Invalid";
VAL_ 1095 MHU_SET_KaraokeMode 0 "Karaoke mode OFF" 1 "Karaoke ON" 2 "Reserved" 3 "Signal Invalid";
VAL_ 1095 MHU_Req_StoppingMode 0 "Off" 1 "CreepMode" 2 "RollMode" 3 "HoldMode" 4 "NoRequest" 5 "Reserved" 6 "Reserved" 7 "Invalid";
VAL_ 1095 MHU_SET_WashMode 0 "Wash mode OFFt" 1 "Wash mode ON" 2 "Reserved" 3 "Signal Invalid";
VAL_ 1095 MHU_SET_StopMode 0 "Creep" 1 "Hold" 2 "Roll" 3 "Signal Invalid";
VAL_ 1095 MHU_AVH_Sw 0 "No Action" 1 "ON" 2 "OFF" 3 "Reserved";
VAL_ 1096 EDS_iDcLnkOvCLimFail_FWD 0 "Normal" 1 "Error";
VAL_ 1096 EDS_MotBlockedFault_FWD 0 "Normal" 1 "Error";
VAL_ 1096 EDS_RSLErr_FWD 0 "Normal" 1 "Error";
VAL_ 1096 EDS_MotTrqLimFault_FWD 0 "Normal" 1 "Error";
VAL_ 1096 EDS_VCUChksumFault_FWD 0 "Normal" 1 "Error";
VAL_ 1096 EDS_IGBTFault_FWD 0 "Normal" 1 "Error";
VAL_ 1096 EDS_CANBusoffFault_FWD 0 "Normal" 1 "Error";
VAL_ 1096 EDS_TDrvBoardOvHiWarn_FWD 0 "Normal" 1 "Error";
VAL_ 1096 EDS_TIGBTOvHiFault_FWD 0 "Normal" 1 "Error";
VAL_ 1096 EDS_TIGBTOvHiWarn_FWD 0 "Normal" 1 "Error";
VAL_ 1096 EDS_IOHWABSampFail_FWD 0 "Normal" 1 "Error";
VAL_ 1096 EDS_EDSOpenFault_FWD 0 "Normal" 1 "Error";
VAL_ 1096 EDS_MotorOpenFault_FWD 0 "Normal" 1 "Error";
VAL_ 1096 EDS_EparkSampFail_FWD 0 "Normal" 1 "Error";
VAL_ 1096 EDS_EmacBlkdWarn_FWD 0 "Normal" 1 "Error";
VAL_ 1096 EDS_VerMatchFailureErr_FWD 0 "Normal" 1 "Error";
VAL_ 1096 EDS_DiashCirNoPsblErr_FWD 0 "Normal" 1 "Error";
VAL_ 1096 EDS_OperOutdRngErr_FWD 0 "Normal" 1 "Error";
VAL_ 1096 EDS_PhaseLossFaultErr_FWD 0 "Normal" 1 "Error";
VAL_ 1096 EDS_CPLDFault_FWD 0 "Normal" 1 "Error";
VAL_ 1096 EDS_CPLDFaultBaseSpd_FWD 0 "Normal" 1 "Error";
VAL_ 1096 EDS_IOHWABNen33Fail_FWD 0 "Normal" 1 "Error";
VAL_ 1096 EDS_HvMcuSlightFault_FWD 0 "Normal" 1 "Error";
VAL_ 1096 EDS_HvMcuSevFault_FWD 0 "Normal" 1 "Error";
VAL_ 1096 EDS_EDSPhaSampHWFault_FWD 0 "Normal" 1 "Error";
VAL_ 1096 EDS_IsOvHiErr_FWD 0 "Normal" 1 "Error";
VAL_ 1096 EDS_CanRollingCounterErr_FWD 0 "Normal" 1 "Error";
VAL_ 1096 EDS_CanTimeoutErr_FWD 0 "Normal" 1 "Error";
VAL_ 1096 EDS_CrashFault_FWD 0 "Normal" 1 "Error";
VAL_ 1096 EDS_PCFSlightFault_FWD 0 "Normal" 1 "Error";
VAL_ 1096 EDS_PCFSerFault_FWD 0 "Normal" 1 "Error";
VAL_ 1097 EDS_iDcLnkOvCLimFail_RWD 0 "Normal" 1 "Error";
VAL_ 1097 EDS_MotBlockedFault_RWD 0 "Normal" 1 "Error";
VAL_ 1097 EDS_RSLErr_RWD 0 "Normal" 1 "Error";
VAL_ 1097 EDS_MotTrqLimFault_RWD 0 "Normal" 1 "Error";
VAL_ 1097 EDS_VCUChksumFault_RWD 0 "Normal" 1 "Error";
VAL_ 1097 EDS_IGBTFault_RWD 0 "Normal" 1 "Error";
VAL_ 1097 EDS_CANBusoffFault_RWD 0 "Normal" 1 "Error";
VAL_ 1097 EDS_TDrvBoardOvHiWarn_RWD 0 "Normal" 1 "Error";
VAL_ 1097 EDS_TIGBTOvHiFault_RWD 0 "Normal" 1 "Error";
VAL_ 1097 EDS_TIGBTOvHiWarn_RWD 0 "Normal" 1 "Error";
VAL_ 1097 EDS_IOHWABSampFail_RWD 0 "Normal" 1 "Error";
VAL_ 1097 EDS_EDSOpenFault_RWD 0 "Normal" 1 "Error";
VAL_ 1097 EDS_MotorOpenFault_RWD 0 "Normal" 1 "Error";
VAL_ 1097 EDS_EparkSampFail_RWD 0 "Normal" 1 "Error";
VAL_ 1097 EDS_EmacBlkdWarn_RWD 0 "Normal" 1 "Error";
VAL_ 1097 EDS_VerMatchFailureErr_RWD 0 "Normal" 1 "Error";
VAL_ 1097 EDS_DiashCirNoPsblErr_RWD 0 "Normal" 1 "Error";
VAL_ 1097 EDS_OperOutdRngErr_RWD 0 "Normal" 1 "Error";
VAL_ 1097 EDS_PhaseLossFaultErr_RWD 0 "Normal" 1 "Error";
VAL_ 1097 EDS_CPLDFault_RWD 0 "Normal" 1 "Error";
VAL_ 1097 EDS_CPLDFaultBaseSpd_RWD 0 "Normal" 1 "Error";
VAL_ 1097 EDS_IOHWABNen33Fail_RWD 0 "Normal" 1 "Error";
VAL_ 1097 EDS_HvMcuSlightFault_RWD 0 "Normal" 1 "Error";
VAL_ 1097 EDS_HvMcuSevFault_RWD 0 "Normal" 1 "Error";
VAL_ 1097 EDS_EDSPhaSampHWFault_RWD 0 "Normal" 1 "Error";
VAL_ 1097 EDS_IsOvHiErr_RWD 0 "Normal" 1 "Error";
VAL_ 1097 EDS_CanRollingCounterErr_RWD 0 "Normal" 1 "Error";
VAL_ 1097 EDS_CanTimeoutErr_RWD 0 "Normal" 1 "Error";
VAL_ 1097 EDS_CrashFault_RWD 0 "Normal" 1 "Error";
VAL_ 1097 EDS_PCFSlightFault_RWD 0 "Normal" 1 "Error";
VAL_ 1097 EDS_PCFSerFault_RWD 0 "Normal" 1 "Error";
VAL_ 1104 MHU_SET_WindowLifterFrontL 0 "No action" 1 "Manual open" 2 "Automatic open" 3 "Manual close" 4 "Automatic close" 5 "Slightly open" 6 "Reserved" 7 "Signal invalid";
VAL_ 1104 MHU_SET_WindowLifterFrontR 0 "No action" 1 "Manual open" 2 "Automatic open" 3 "Manual close" 4 "Automatic close" 5 "Slightly open" 6 "Reserved" 7 "Signal invalid";
VAL_ 1104 MHU_SET_WindowLifterRearL 0 "No action" 1 "Manual open" 2 "Automatic open" 3 "Manual close" 4 "Automatic close" 5 "Slightly open" 6 "Reserved" 7 "Signal invalid";
VAL_ 1104 MHU_SET_WindowLifterRearR 0 "No action" 1 "Manual open" 2 "Automatic open" 3 "Manual close" 4 "Automatic close" 5 "Slightly open" 6 "Reserved" 7 "Signal invalid";
VAL_ 1104 MHU_SET_WindowAutoClose 0 "OFF" 1 "ON" 2 "Reserved" 3 "Signal invalid";
VAL_ 1106 MHU_SET_ANN1_MODE 0 "Invalid" 1 "Navigation" 2 "Telephone" 3 "Prompts";
VAL_ 1107 MHU_SET_ANN1_PROMPTS_SPEAKER 0 "Invalid" 1 "Select FL_FR" 2 "Select CEN" 3 "Select FL_FR_CEN" 4 "Select RL_RR" 5 "Select All" 6 "Reserved";
VAL_ 1108 MHU_SET_ANN2_CEN_Mute 0 "Invalid" 1 "Mute ANN2 CEN" 2 "UnMute ANN2 CEN";
VAL_ 1108 MHU_SET_ANN2_RR_Mute 0 "Invalid" 1 "Mute ANN2 RR" 2 "UnMute ANN2 RR";
VAL_ 1108 MHU_SET_ANN2_RL_Mute 0 "Invalid" 1 "Mute ANN2 RL" 2 "Unmute ANN2 RL";
VAL_ 1108 MHU_SET_ANN2_FR_Mute 0 "Invalid" 1 "Mute ANN2 FR" 2 "UnMute ANN2 FR";
VAL_ 1108 MHU_SET_ANN2_FL_Mute 0 "Invalid" 1 "Mute ANN2 FL" 2 "UnMute ANN2 FL";
VAL_ 1109 AMP_SET_Soundzone 0 "Invalid" 1 "Front" 2 "Rear" 3 "ALL";
VAL_ 1109 AMP_SET_MediaMute 0 "Invalid" 1 "Mute" 2 "Unmute" 3 "Reserved";
VAL_ 1110 OP_WISW_SZL_LIN 0 "No action" 255 "Signal Invalid";
VAL_ 1110 COMM_ERR_SZL_LIN 0 "No error" 1 "Error active";
VAL_ 1110 BCM_Wiper_Front_Status 0 "OFF" 1 "Mist" 2 "IntermittentAuto" 3 "Low Speed" 4 "High Speed" 5 "Reserved" 6 "Reserved" 7 "Invalid";
VAL_ 1110 OP_WIPO_SZL_LIN 0 "Step 1" 1 "Step 2" 2 "Step 3" 4 "Step 4" 7 "Signal Invalid";
VAL_ 1110 OP_COLS_SZL_LIN 0 "No action" 255 "Signal Invalid";
VAL_ 1110 NOD_ERR_SZL_LIN 0 "NO error" 1 "error active" 2 "error Stat change" 3 "Signal invalid";
VAL_ 1110 BCM_Wiper_Rear_Status 0 "OFF" 1 "ON" 2 "Reserved" 3 "Signal Invalid";
VAL_ 1111 AmbLight_Error_Z5 0 "No Error" 1 "Error";
VAL_ 1111 AmbLight_Error_Z4 0 "No Error" 1 "Error";
VAL_ 1111 AmbLight_Error_Z3 0 "No Error" 1 "Error";
VAL_ 1111 AmbLight_Error_Z2 0 "No Error" 1 "Error";
VAL_ 1111 AmbLight_Error_Z1 0 "No Error" 1 "Error";
VAL_ 1112 AmbLightColorZoneReq 0 "no zone" 1 " ALM Zone 1 = CSUV_ALM Cockpit_DSUV_COCKPIT_DRIVER " 2 " ALM Zone 2 = CSUV_ALM Right Front Door_DSUV_COCKPIT_PASSANGER" 3 "ALM Zone 3 = CSUV_ALM Left Front Door_DSUV_FRT_DOOR_LH" 4 "ALM Zone 4 = CSUV_ALM Right Rear Door_DSUV_FRT_DOOR_RH" 5 "ALM Zone 5 = CSUV_ALM Left Rear Door_DSUV_RR_DOOR_RH" 6 "ALM Zone 6 = DSUV_RR_DOOR_RH" 7 "ALM Zone 7 = DSUV_CENTER_CONSOLE_DRIVER" 8 "ALM Zone 8 = DSUV_CENTER_CONSOLE_PASSANGER" 9 "ALM Zone 9 = DSUV_CENTER_CONSOLE_RR_DRIVER" 10 "ALM Zone 10 = DSUV_CENTER_CONSOLE_RR_PASSANGER";
VAL_ 1113 AmbLightIntensityTimingTypeReq 0 "None" 1 "Blinking" 2 "Wave" 3 "Morse" 4 "Fading";
VAL_ 1124 LDML_LampAssemblySts 0 "Normal" 1 "Fault" 2 "Reserved" 3 "Signal Invalid";
VAL_ 1124 LDML_PosLmpSts 0 "OFF" 1 "ON" 2 "Fault" 3 "Signal Invalid";
VAL_ 1124 LDML_ControllerSts 0 "Normal" 1 "Fault" 2 "Reserved" 3 "Signal Invalid";
VAL_ 1124 LDML_TurnIndicatorSts 0 "OFF" 1 "ON" 2 "Fault" 3 "Signal Invalid";
VAL_ 1124 LDML_AuxLBSts 0 "OFF" 1 "ON" 2 "Fault" 3 "Signal Invalid";
VAL_ 1124 LDML_LowBeamSts 0 "OFF" 1 "ON" 2 "Fault" 3 "Signal Invalid ";
VAL_ 1124 LDML_HighBeamSts 0 "OFF" 1 "ON" 2 "Fault" 3 "Signal Invalid";
VAL_ 1124 LDML_DayRunningLampSts 0 "OFF" 1 "ON" 2 "Fault" 3 "Signal Invalid";
VAL_ 1124 LDML_DayTimeRunningLightFbSts 0 "OFF" 1 "ON" 2 "Reserved" 3 "Signal Invalid";
VAL_ 1124 LDML_AutoLvlFbSts 0 "OFF" 1 "ON" 2 "Reserved" 3 "Signal Invalid";
VAL_ 1124 LDML_AdptvDrvBeamFbSts 0 "OFF" 1 "ON" 2 "Reserved" 3 "Signal Invalid";
VAL_ 1124 LDML_AuxHBSts 0 "OFF" 1 "ON" 2 "Fault" 3 "Signal Invalid";
VAL_ 1124 LDML_FollowMeHomeFbSts 0 "OFF" 1 "30 secs" 2 "60 secs" 3 "90 secs" 4 "120 secs" 5 "Signal Invalid";
VAL_ 1124 LDML_ExteriorLightFbSts 0 "OFF" 1 "Parking" 2 "Low Beam" 3 "AUTO" 4 "Signal Invalid";
VAL_ 1124 LDML_AHB_ICON_Feed 0 "off " 1 "gray icon" 2 "green icon" 3 "SNA";
VAL_ 1125 LDMR_LampAssemblySts 0 "Normal" 1 "Fault" 2 "Reserved" 3 "Signal Invalid";
VAL_ 1125 LDMR_PosLmpSts 0 "OFF" 1 "ON" 2 "Fault" 3 "Signal Invalid";
VAL_ 1125 LDMR_ControllerSts 0 "Normal" 1 "Fault" 2 "Reserved" 3 "Signal Invalid";
VAL_ 1125 LDMR_TurnIndicatorSts 0 "OFF" 1 "ON" 2 "Fault" 3 "Signal Invalid";
VAL_ 1125 LDMR_AuxLBSts 0 "OFF" 1 "ON" 2 "Fault" 3 "Signal Invalid";
VAL_ 1125 LDMR_LowBeamSts 0 "OFF" 1 "ON" 2 "Fault" 3 "Signal Invalid ";
VAL_ 1125 LDMR_HighBeamSts 0 "OFF" 1 "ON" 2 "Fault" 3 "Signal Invalid";
VAL_ 1125 LDMR_DayRunningLampSts 0 "OFF" 1 "ON" 2 "Fault" 3 "Signal Invalid";
VAL_ 1125 LDMR_DayTimeRunningLightFbSts 0 "OFF" 1 "ON" 2 "Reserved" 3 "Signal Invalid";
VAL_ 1125 LDMR_AutoLvlFbSts 0 "OFF" 1 "ON" 2 "Reserved" 3 "Signal Invalid";
VAL_ 1125 LDMR_AdptvDrvBeamFbSts 0 "OFF" 1 "ON" 2 "Reserved" 3 "Signal Invalid";
VAL_ 1125 LDMR_AuxHBSts 0 "OFF" 1 "ON" 2 "Fault" 3 "Signal Invalid";
VAL_ 1125 LDMR_FollowMeHomeFbSts 0 "OFF" 1 "30 secs" 2 "60 secs" 3 "90 secs" 4 "120 secs" 5 "Signal Invalid";
VAL_ 1125 LDMR_ExteriorLightFbSts 0 "OFF" 1 "Parking" 2 "Low Beam" 3 "AUTO" 4 "Signal Invalid";
VAL_ 1125 LDMR_AHB_ICON_Feed 0 "off " 1 "gray icon" 2 "green icon" 3 "SNA";
VAL_ 1136 AMP_SET_ANN1_MODE 0 "Invalid" 1 "Navigation" 2 "Telephone" 3 "Prompts";
VAL_ 1137 AMP_SET_ANN1_PROMPTS_SPEAKER 0 "Invalid" 1 "Select FL_FR" 2 "Select CEN" 3 "Select FL_FR_CEN" 4 "Select RL_RR" 5 "Select All" 6 "Reserved";
VAL_ 1138 AMP_SET_ANN2_CEN_Mute 0 "Invalid" 1 "Mute ANN2 CEN" 2 "UnMute ANN2 CEN";
VAL_ 1138 AMP_SET_ANN2_RR_Mute 0 "Invalid" 1 "Mute ANN2 RR" 2 "UnMute ANN2 RR";
VAL_ 1138 AMP_SET_ANN2_RL_Mute 0 "Invalid" 1 "Mute ANN2 RL" 2 "UnMute ANN2 RL";
VAL_ 1138 AMP_SET_ANN2_FR_Mute 0 "Invalid" 1 "Mute ANN2 FR" 2 "UnMute ANN2 FR";
VAL_ 1138 AMP_SET_ANN2_FL_Mute 0 "Invalid" 1 "Mute ANN2 FL" 2 "UnMute ANN2 FL";
VAL_ 1152 PSM_DrvSeatMissalignment 0 "Off" 1 "Driver Power seat malfunction, Seat Initialization required";
VAL_ 1152 PSM_PasSeatMisalignment 0 "Off" 1 "Passenger Power seat malfunction, Seat Initialization required";
VAL_ 1153 BCM_NoValidKey_1 0 "None" 1 "Alert";
VAL_ 1153 BCM_SSB_defect 0 "None" 1 "Alert";
VAL_ 1153 BCM_WrongGearPosToStart 0 "None" 1 "Alert";
VAL_ 1153 BCM_NoValidKey_2 0 "None" 1 "Alert";
VAL_ 1153 BCM_PressBrakeToStart 0 "None" 1 "Alert";
VAL_ 1153 BCM_TurnOffPosLightRemindr 0 "None" 1 "Alert";
VAL_ 1153 BCM_KeyFob_LowBattery 0 "None" 1 "Alert";
VAL_ 1153 BCM_StopLightDefect 0 "None" 1 "Alert";
VAL_ 1153 BCM_LowBeamDefect 0 "None" 1 "Alert";
VAL_ 1153 BCM_HighBeamDefect 0 "None" 1 "Alert";
VAL_ 1153 BCM_PositionLightDefect 0 "None" 1 "Alert";
VAL_ 1153 BCM_CHMLS_Defect 0 "None" 1 "Alert";
VAL_ 1153 BCM_LicencePlateLight_Defect 0 "None" 1 "Alert";
VAL_ 1153 BCM_FrontFog_Defect 0 "None" 1 "Alert";
VAL_ 1153 BCM_RearFog_Defect 0 "None" 1 "Alert";
VAL_ 1153 BCM_ReverseLightDefect 0 "None" 1 "Alert";
VAL_ 1153 BCM_RLS_Malfunction 0 "None" 1 "Alert";
VAL_ 1153 BCM_12VBattery_LowLevel 0 "None" 1 "Alert";
VAL_ 1153 BCM_ForgetKeyFOBInCar 0 "None" 1 "Alert";
VAL_ 1153 BCM_12VBattery_Discharging 0 "None" 1 "Alert";
VAL_ 1153 BCM_TurnIndicatorDefect 0 "None" 1 "Alert";
VAL_ 1153 BCM_dTPMS_Malfunc 0 "None" 1 "Alert";
VAL_ 1153 BCM_dTPMS_Malfunc_LostSensor 0 "None" 1 "Alert";
VAL_ 1153 BCM_dTPMS_LowPressure 0 "None" 1 "Alert";
VAL_ 1153 BCM_dTPMS_RapidLeak 0 "None" 1 "Alert";
VAL_ 1153 BCM_dTPMS_HighTemperature 0 "None" 1 "Alert";
VAL_ 1153 BCM_dTPMS_HighPressure 0 "None" 1 "Alert";
VAL_ 1153 BCM_dTPMS_LowBattery 0 "None" 1 "Alert";
VAL_ 1153 BCM_Keyfob_Leftcar 0 "None" 1 "Alert";
VAL_ 1153 BCM_IDB_Brakelight_Malfunction 0 "None" 1 "Alert";
VAL_ 1153 BCM_VCU_Brakelight_Malfunction 0 "None" 1 "Alert";
VAL_ 1153 BCM_ADAS_Turnlight_Malfunction 0 "None" 1 "Alert";
VAL_ 1153 BCM_ADAS_Highbeam_Malfunction 0 "None" 1 "Alert";
VAL_ 1153 BCM_ADAS_LowBeam_Malfunction 0 "None" 1 "Alert";
VAL_ 1153 BCM_MHU_Malfunction 0 "None" 1 "Alert";
VAL_ 1153 BCM_BCM_Malfunction 0 "None" 1 "Alert";
VAL_ 1153 BCM_SCM_Malfunction 0 "None" 1 "Alert";
VAL_ 1153 BCM_CrashSignalDefect 0 "None" 1 "Alert";
VAL_ 1153 BCM_FrontWiperDefect 0 "None" 1 "Alert";
VAL_ 1153 BCM_Rear_RightDoorLockDefect 0 "None" 1 "Alert";
VAL_ 1153 BCM_RearLeftDoorLockDefect 0 "None" 1 "Alert";
VAL_ 1153 BCM_Front_RightDoorLockDefect 0 "None" 1 "Alert";
VAL_ 1153 BCM_FrontLeftDoorLockDefect 0 "None" 1 "Alert";
VAL_ 1153 BCM_LDML_Malfunction 0 "None" 1 "Alert";
VAL_ 1153 BCM_LDMR_Malfunction 0 "None" 1 "Alert";
VAL_ 1153 BCM_RLBL_Malfunction 0 "None" 1 "Alert";
VAL_ 1153 BCM_RLBR_Malfunction 0 "None" 1 "Alert";
VAL_ 1153 BCM_RLT_Malfunction 0 "None" 1 "Alert";
VAL_ 1153 BCM_BCM_POWER_Malfunction 0 "None" 1 "Alert";
VAL_ 1153 BCM_IDB_AutoHazardBlinking_Malf 0 "None" 1 "Alert";
VAL_ 1154 XGW_AutoHLLevelingFault 0 "No Error" 1 "Error";
VAL_ 1154 XGW_WasherFluidLvlSw 0 "No Error" 1 "Error";
VAL_ 1154 XGW_Warning_Flag_3 0 "No Error" 1 "Error";
VAL_ 1154 XGW_Warning_Flag_4 0 "No Error" 1 "Error";
VAL_ 1154 XGW_Warning_Flag_5 0 "No Error" 1 "Error";
VAL_ 1154 XGW_Warning_Flag_6 0 "No Error" 1 "Error";
VAL_ 1154 XGW_Warning_Flag_7 0 "No Error" 1 "Error";
VAL_ 1154 XGW_Warning_Flag_8 0 "No Error" 1 "Error";
VAL_ 1154 XGW_Warning_Flag_9 0 "No Error" 1 "Error";
VAL_ 1154 XGW_Warning_Flag_10 0 "No Error" 1 "Error";
VAL_ 1154 XGW_Warning_Flag_11 0 "No Error" 1 "Error";
VAL_ 1154 XGW_Warning_Flag_12 0 "No Error" 1 "Error";
VAL_ 1155 TPMS_FLTirePress 255 "Invalid";
VAL_ 1155 TPMS_FRTirePress 255 "Invalid";
VAL_ 1155 TPMS_RLTirePress 255 "Invalid";
VAL_ 1155 TPMS_RRTirePress 255 "Invalid";
VAL_ 1155 TPMS_FLTirePressAlarm 0 "No warning" 1 "High pressure warning" 2 "Low pressure warning" 3 "Quick leakage" 4 "Lost Sensor" 5 "Sensor battery low" 6 "Sensor failure" 7 "Reserved";
VAL_ 1155 TPMS_FRTirePressAlarm 0 "No warning" 1 "High pressure warning" 2 "Low pressure warning" 3 "Quick leakage" 4 "Lost Sensor" 5 "Sensor battery low" 6 "Sensor failure" 7 "Reserved";
VAL_ 1155 TPMS_RLTirePressAlarm 0 "No warning" 1 "High pressure warning" 2 "Low pressure warning" 3 "Quick leakage" 4 "Lost Sensor" 5 "Sensor battery low" 6 "Sensor failure" 7 "Reserved";
VAL_ 1155 TPMS_RRTirePressAlarm 0 "No warning" 1 "High pressure warning" 2 "Low pressure warning" 3 "Quick leakage" 4 "Lost Sensor" 5 "Sensor battery low" 6 "Sensor failure" 7 "Reserved";
VAL_ 1155 TPMS_TirePosition 0 "No any sensor" 1 "Left Front tire" 2 "Right Front tire" 3 "Right Rear tire" 4 "Left Rear tire" 5 "reseved" 6 "reseved" 7 "reserved";
VAL_ 1155 TPMS_ready2learning 0 "Invalid" 1 "Ready";
VAL_ 1155 TPMS_TireTempAlarm 0 "No warning" 1 "High Temperature Warning";
VAL_ 1155 TPMS_LearningStatus 0 "invalid" 1 "Left Front tire done" 2 "Right Front tire done" 3 "Right Rear tire done" 4 "Left Rear tire done" 5 "All completed" 6 "Failure" 7 "reserved";
VAL_ 1155 TPMS_TireTemp 255 "Invalid";
VAL_ 1156 APA_ReqInfoDispTxt3 0 "No request" 1 "Timeout, parking exit" 2 "gear intervention, parking exit" 3 "throttle intervention, parking exit" 4 "steering wheel intervention, parking exit" 5 "Electronic handbrake intervention, parking exit'" 6 "The main driving door is opened and parking is suspended" 7 "The number of parking times exceeds the limit, and the parking is exited" 8 "The road slope is too big, parking exit" 9 "The number of resumable interruptions exceeds the limit, and the parking is exited" 10 "Associated ECU failure, parking exit" 11 "Parking speed exceeds limit, parking exit" 12 "Parking system failure, parking exit" 13 "The gear can't be switched normally, parking exit" 14 "The driver takes the initiative to exit" 15 "The vehicle cannot move, parking exit" 16 "When an obstacle is detected, parking is suspended" 17 "The main driver's seat belt is loosened and parking is suspended" 18 "The co-drive door is opened and parking is suspended" 19 "The parking space is limited, and the parking function is exited" 20 "The tailgate is opened and parking is suspended" 21 "The right rear door is opened and parking is suspended" 22 "The left rear door is opened and parking is suspended" 23 "The front hatch door is opened and parking is suspended" 24 "parking is completed" 25 "parking failed" 26 "Remote connection is interrupted" 27 "Please hang in the P gear" 28 "Remote parking has started" 29 "noise interference causing parking termination";
VAL_ 1156 APA_ParkOutDircnDisReq 0 "No Request" 1 "Request";
VAL_ 1156 APA_ParkOutModeDisReq 0 "No Request" 1 "Request";
VAL_ 1156 APA_MHU_DisplaystartbuttonReq 0 "No" 1 "FAPA Request" 2 "RP Request";
VAL_ 1156 APA_ReqInfoDispTxt4 0 "No request" 1 "The main driver's door is open" 2 "passenger door is open" 3 "left passenger area is open" 4 " passenger area on the right is open" 5 "The front hatch door is open" 6 "The tailgate is open" 7 "APA parking assist system failure, parking exit" 8 "APA related actuator failure" 9 "ACC/ICC function cannot be activated" 10 "vehicle speed is too fast" 11 "slope is too large to activate";
VAL_ 1156 APA_ReqInfoDispTxt2 0 "No request" 1 "drive forward" 2 "parking space has been found" 3 "Parking starts" 4 " Auto parking in progress" 5 "please put the gear into P please release the brake and steering" 6 "please release the brake and steering" 7 "If you need to continue parking please click the Continue button";
VAL_ 1156 APA_ReqInfoDispTxt1 0 "No request" 1 "APA parking assist system is faulty and the parking function cannot be opened" 2 "APA related actuator failure, unable to open the parking function" 3 "The ACC/ICA function is activated, and the parking function cannot be turned on" 4 "The ESC auxiliary function is activated, and the parking function cannot be turned on" 5 "The slope is too large to activate the parking function" 6 "The trailer is detected, the FAPA/RP function cannot be turned on";
VAL_ 1156 APA_MHU_Displayparkingtype 0 "No Request" 1 "Request";
VAL_ 1156 APA_ShowAPAFdbck 0 "No request" 1 "Request APA on" 2 "Request APA off";
VAL_ 1156 APA_FuncModeFdbck 0 "No Function" 1 "parking in" 2 "parking out" 3 "drag parking";
VAL_ 1156 APA_MHU_DisplayrecoverbuttonReq 0 "No Request" 1 "Request";
VAL_ 1156 APA_SysSoundIndication 0 "No indication" 1 "Find the park slot" 2 "successful spot selection" 3 "Parking in progress" 4 "RP in progress" 5 "Parking completed " 6 "Ask the driver take over" 7 "System disabled or fault";
VAL_ 1156 APA_Currentfunction 0 "No function" 1 "Auto Parking in" 2 "Auto Parking out" 3 "Auto drag parking in" 4 "Remote Parking in" 5 "Remote Parking out'" 6 "Straight Parking";
VAL_ 1156 APA_MHU_Status 0 "Off" 1 "Standby" 2 "Enable" 3 "Active" 4 "Finished" 5 "Suspend" 6 "abort" 7 "Failed";
VAL_ 1160 ACM_Malfunction 0 "ACM_Failure" 1 "ACM_Normal_Operation";
VAL_ 1160 ACM_Pre_Drive_Check 0 "ACM_Pre_Drive_Check" 1 "ACM_Normal_Operation";
VAL_ 1160 ACM_in_Plant_Mode 0 "ACM_in_Plant_Mode" 1 "ACM_in_Normal_Mode";
VAL_ 1160 ACM_PAB_Suppression 0 "Not_Suppressed" 1 "Suppressed" 2 "Function Failure" 3 "Invalid_Value";
VAL_ 1160 ACM_Airbag_Disabled 0 "ACM_AirBag_Disabled" 1 "ACM_Normal_Operation";
VAL_ 1160 ACM_Development_Calibration 0 "ACM_Dev_Calibrated" 1 "ACM_Normal_Operation";
VAL_ 1160 ACM_In_Disposal_Mode 0 "ACM_In_Disposal_Mode" 1 "ACM_Normal_Operation";
VAL_ 1160 ACM_Seatbelt_Reminder_Request 0 "Seatbelt reminder NOT activated" 1 "Seatbelt reminder activated";
VAL_ 1160 ACM_SBR_Chime_Req 0 "No Active Chime" 1 "Active Chime";
VAL_ 1160 ACM_SBR_Blinking_Req 0 "No Blinking" 1 "Blinking 1Hz";
VAL_ 1161 CCU_Malfunction 0 "No Error" 1 "Error";
VAL_ 1161 CCU_Warning_Flag_2 0 "No Error" 1 "Error";
VAL_ 1161 CCU_Warning_Flag_3 0 "No Error" 1 "Error";
VAL_ 1161 CCU_Warning_Flag_4 0 "No Error" 1 "Error";
VAL_ 1161 CCU_Warning_Flag_5 0 "No Error" 1 "Error";
VAL_ 1161 CCU_Warning_Flag_6 0 "No Error" 1 "Error";
VAL_ 1161 CCU_Warning_Flag_7 0 "No Error" 1 "Error";
VAL_ 1161 CCU_Warning_Flag_8 0 "No Error" 1 "Error";
VAL_ 1161 CCU_Warning_Flag_9 0 "No Error" 1 "Error";
VAL_ 1161 CCU_Warning_Flag_10 0 "No Error" 1 "Error";
VAL_ 1161 CCU_Warning_Flag_11 0 "No Error" 1 "Error";
VAL_ 1161 CCU_Warning_Flag_12 0 "No Error" 1 "Error";
VAL_ 1165 HUD_Malfunction 0 "No Error" 1 "Error";
VAL_ 1165 HUD_Failed_Temporary 0 "No Error" 1 "Error";
VAL_ 1165 HUD_Overheating 0 "No Error" 1 "Error";
VAL_ 1165 HUD_Warning_Flag_4 0 "No Error" 1 "Error";
VAL_ 1165 HUD_Warning_Flag_5 0 "No Error" 1 "Error";
VAL_ 1165 HUD_Warning_Flag_6 0 "No Error" 1 "Error";
VAL_ 1165 HUD_Warning_Flag_7 0 "No Error" 1 "Error";
VAL_ 1165 HUD_Warning_Flag_8 0 "No Error" 1 "Error";
VAL_ 1165 HUD_Warning_Flag_9 0 "No Error" 1 "Error";
VAL_ 1165 HUD_Warning_Flag_10 0 "No Error" 1 "Error";
VAL_ 1165 HUD_Warning_Flag_11 0 "No Error" 1 "Error";
VAL_ 1165 HUD_Warning_Flag_12 0 "No Error" 1 "Error";
VAL_ 1166 ETG_Malfunction 0 "No Error" 1 "Error";
VAL_ 1166 ETG_Warning_Flag_2 0 "No Error" 1 "Error";
VAL_ 1166 ETG_Warning_Flag_3 0 "No Error" 1 "Error";
VAL_ 1166 ETG_Warning_Flag_4 0 "No Error" 1 "Error";
VAL_ 1166 ETG_Warning_Flag_5 0 "No Error" 1 "Error";
VAL_ 1166 ETG_Warning_Flag_6 0 "No Error" 1 "Error";
VAL_ 1166 ETG_Warning_Flag_7 0 "No Error" 1 "Error";
VAL_ 1166 ETG_Warning_Flag_8 0 "No Error" 1 "Error";
VAL_ 1166 ETG_Warning_Flag_9 0 "No Error" 1 "Error";
VAL_ 1166 ETG_Warning_Flag_10 0 "No Error" 1 "Error";
VAL_ 1166 ETG_Warning_Flag_11 0 "No Error" 1 "Error";
VAL_ 1166 ETG_Warning_Flag_12 0 "No Error" 1 "Error";
VAL_ 1168 GS_Warning_Flag_1 0 "No Error" 1 "Error";
VAL_ 1168 GS_Warning_Flag_2 0 "No Error" 1 "Error";
VAL_ 1168 GS_Warning_Flag_3 0 "No Error" 1 "Error";
VAL_ 1168 GS_Warning_Flag_4 0 "No Error" 1 "Error";
VAL_ 1168 GS_Warning_Flag_5 0 "No Error" 1 "Error";
VAL_ 1168 GS_Warning_Flag_6 0 "No Error" 1 "Error";
VAL_ 1168 GS_Warning_Flag_7 0 "No Error" 1 "Error";
VAL_ 1168 GS_Warning_Flag_8 0 "No Error" 1 "Error";
VAL_ 1168 GS_Warning_Flag_9 0 "No Error" 1 "Error";
VAL_ 1168 GS_Warning_Flag_10 0 "No Error" 1 "Error";
VAL_ 1168 GS_Warning_Flag_11 0 "No Error" 1 "Error";
VAL_ 1168 GS_Warning_Flag_12 0 "No Error" 1 "Error";
VAL_ 1171 BMS_PackTempSts 0 "No warning" 1 "Over Temperature Warning" 2 "Under Temperature Warning" 3 "Extreme low temp error";
VAL_ 1171 BMS_ThermalRunaway 0 "No Warning" 1 "Warning";
VAL_ 1171 BMS_BatteryReplacement 0 "No Warning" 1 "Warning";
VAL_ 1171 BMS_Warning_PowerDegrade 0 "Normal" 1 "Pack Power Degrade";
VAL_ 1171 BMS_Warning_DeltaSoC 0 "Normal" 1 "Delta SOC high";
VAL_ 1171 BMS_Warning_HVILSts 0 "Normal" 1 "HVIL error detected";
VAL_ 1171 BMS_Warning_Isolation 0 "Normal" 1 "Isolation reached level 3";
VAL_ 1171 BMS_Warning_CoolantLeakage 0 "Normal" 1 "Coolant leakage detected";
VAL_ 1171 BMS_MalfunctionSts 0 "No Warning" 1 "Warning";
VAL_ 1171 BMS_LowBattery 0 "No warning" 1 "Low level" 2 "Extremely low level";
VAL_ 1171 BMS_Warning_DeltaTemperature 0 "Normal" 1 "Level 1 warning" 2 "Level 2 extreme";
VAL_ 1171 BMS_Warning_BDUTemperatureSts 0 "Normal" 1 "BDU temp warning" 2 "BDU hot" 3 "BDU extreme hot";
VAL_ 1171 BMS_Warning_Contactor_Aging 0 "No warning" 1 "warning" ;
VAL_ 1178 EDS_R_Error_1 0 "No Error" 1 "Error";
VAL_ 1178 EDS_R_Error_2 0 "No Error" 1 "Error";
VAL_ 1178 EDS_R_Error_3 0 "No Error" 1 "Error";
VAL_ 1178 EDS_R_Error_4 0 "No Error" 1 "Error";
VAL_ 1178 EDS_R_Error_5 0 "No Error" 1 "Error";
VAL_ 1178 EDS_R_Error_6 0 "No Error" 1 "Error";
VAL_ 1178 EDS_R_Error_7 0 "No Error" 1 "Error";
VAL_ 1178 EDS_R_Error_8 0 "No Error" 1 "Error";
VAL_ 1178 EDS_R_Error_9 0 "No Error" 1 "Error";
VAL_ 1178 EDS_R_Error_10 0 "No Error" 1 "Error";
VAL_ 1178 EDS_R_Error_11 0 "No Error" 1 "Error";
VAL_ 1178 EDS_R_Error_12 0 "No Error" 1 "Error";
VAL_ 1178 EDS_R_Error_13 0 "No Error" 1 "Error";
VAL_ 1178 EDS_R_Error_14 0 "No Error" 1 "Error";
VAL_ 1178 EDS_R_Error_15 0 "No Error" 1 "Error";
VAL_ 1178 EDS_R_Error_16 0 "No Error" 1 "Error";
VAL_ 1178 EDS_R_Error_17 0 "No Error" 1 "Error";
VAL_ 1178 EDS_R_Error_18 0 "No Error" 1 "Error";
VAL_ 1178 EDS_R_Error_19 0 "No Error" 1 "Error";
VAL_ 1178 EDS_R_Error_20 0 "No Error" 1 "Error";
VAL_ 1178 EDS_R_Error_21 0 "No Error" 1 "Error";
VAL_ 1178 EDS_R_Error_22 0 "No Error" 1 "Error";
VAL_ 1178 EDS_R_Error_23 0 "No Error" 1 "Error";
VAL_ 1178 EDS_R_Error_24 0 "No Error" 1 "Error";
VAL_ 1178 EDS_R_Error_25 0 "No Error" 1 "Error";
VAL_ 1178 EDS_R_Error_26 0 "No Error" 1 "Error";
VAL_ 1178 EDS_R_Error_27 0 "No Error" 1 "Error";
VAL_ 1178 EDS_R_Error_28 0 "No Error" 1 "Error";
VAL_ 1178 EDS_R_Error_29 0 "No Error" 1 "Error";
VAL_ 1178 EDS_R_Error_30 0 "No Error" 1 "Error";
VAL_ 1178 EDS_R_Error_31 0 "No Error" 1 "Error";
VAL_ 1178 EDS_R_Error_32 0 "No Error" 1 "Error";
VAL_ 1178 EDS_R_Error_33 0 "No Error" 1 "Error";
VAL_ 1178 EDS_R_Error_34 0 "No Error" 1 "Error";
VAL_ 1178 EDS_R_Error_35 0 "No Error" 1 "Error";
VAL_ 1178 EDS_R_Error_36 0 "No Error" 1 "Error";
VAL_ 1178 EDS_R_Error_37 0 "No Error" 1 "Error";
VAL_ 1178 EDS_R_Error_38 0 "No Error" 1 "Error";
VAL_ 1178 EDS_R_Error_39 0 "No Error" 1 "Error";
VAL_ 1178 EDS_R_Error_40 0 "No Error" 1 "Error";
VAL_ 1178 EDS_R_Error_41 0 "No Error" 1 "Error";
VAL_ 1178 EDS_R_Error_42 0 "No Error" 1 "Error";
VAL_ 1178 EDS_R_Error_43 0 "No Error" 1 "Error";
VAL_ 1178 EDS_R_Error_44 0 "No Error" 1 "Error";
VAL_ 1178 EDS_R_Error_45 0 "No Error" 1 "Error";
VAL_ 1178 EDS_R_Error_46 0 "No Error" 1 "Error";
VAL_ 1178 EDS_R_Error_47 0 "No Error" 1 "Error";
VAL_ 1178 EDS_R_Error_48 0 "No Error" 1 "Error";
VAL_ 1178 EDS_R_Error_49 0 "No Error" 1 "Error";
VAL_ 1178 EDS_R_Error_50 0 "No Error" 1 "Error";
VAL_ 1178 EDS_R_Error_51 0 "No Error" 1 "Error";
VAL_ 1178 EDS_R_Error_52 0 "No Error" 1 "Error";
VAL_ 1179 EDS_F_Error_1 0 "No Error" 1 "Error";
VAL_ 1179 EDS_F_Error_2 0 "No Error" 1 "Error";
VAL_ 1179 EDS_F_Error_3 0 "No Error" 1 "Error";
VAL_ 1179 EDS_F_Error_4 0 "No Error" 1 "Error";
VAL_ 1179 EDS_F_Error_5 0 "No Error" 1 "Error";
VAL_ 1179 EDS_F_Error_6 0 "No Error" 1 "Error";
VAL_ 1179 EDS_F_Error_7 0 "No Error" 1 "Error";
VAL_ 1179 EDS_F_Error_8 0 "No Error" 1 "Error";
VAL_ 1179 EDS_F_Error_9 0 "No Error" 1 "Error";
VAL_ 1179 EDS_F_Error_10 0 "No Error" 1 "Error";
VAL_ 1179 EDS_F_Error_11 0 "No Error" 1 "Error";
VAL_ 1179 EDS_F_Error_12 0 "No Error" 1 "Error";
VAL_ 1179 EDS_F_Error_13 0 "No Error" 1 "Error";
VAL_ 1179 EDS_F_Error_14 0 "No Error" 1 "Error";
VAL_ 1179 EDS_F_Error_15 0 "No Error" 1 "Error";
VAL_ 1179 EDS_F_Error_16 0 "No Error" 1 "Error";
VAL_ 1179 EDS_F_Error_17 0 "No Error" 1 "Error";
VAL_ 1179 EDS_F_Error_18 0 "No Error" 1 "Error";
VAL_ 1179 EDS_F_Error_19 0 "No Error" 1 "Error";
VAL_ 1179 EDS_F_Error_20 0 "No Error" 1 "Error";
VAL_ 1179 EDS_F_Error_21 0 "No Error" 1 "Error";
VAL_ 1179 EDS_F_Error_22 0 "No Error" 1 "Error";
VAL_ 1179 EDS_F_Error_23 0 "No Error" 1 "Error";
VAL_ 1179 EDS_F_Error_24 0 "No Error" 1 "Error";
VAL_ 1179 EDS_F_Error_25 0 "No Error" 1 "Error";
VAL_ 1179 EDS_F_Error_26 0 "No Error" 1 "Error";
VAL_ 1179 EDS_F_Error_27 0 "No Error" 1 "Error";
VAL_ 1179 EDS_F_Error_28 0 "No Error" 1 "Error";
VAL_ 1179 EDS_F_Error_29 0 "No Error" 1 "Error";
VAL_ 1179 EDS_F_Error_30 0 "No Error" 1 "Error";
VAL_ 1179 EDS_F_Error_31 0 "No Error" 1 "Error";
VAL_ 1179 EDS_F_Error_32 0 "No Error" 1 "Error";
VAL_ 1179 EDS_F_Error_33 0 "No Error" 1 "Error";
VAL_ 1179 EDS_F_Error_34 0 "No Error" 1 "Error";
VAL_ 1179 EDS_F_Error_35 0 "No Error" 1 "Error";
VAL_ 1179 EDS_F_Error_36 0 "No Error" 1 "Error";
VAL_ 1179 EDS_F_Error_37 0 "No Error" 1 "Error";
VAL_ 1179 EDS_F_Error_38 0 "No Error" 1 "Error";
VAL_ 1179 EDS_F_Error_39 0 "No Error" 1 "Error";
VAL_ 1179 EDS_F_Error_40 0 "No Error" 1 "Error";
VAL_ 1179 EDS_F_Error_41 0 "No Error" 1 "Error";
VAL_ 1179 EDS_F_Error_42 0 "No Error" 1 "Error";
VAL_ 1179 EDS_F_Error_43 0 "No Error" 1 "Error";
VAL_ 1179 EDS_F_Error_44 0 "No Error" 1 "Error";
VAL_ 1179 EDS_F_Error_45 0 "No Error" 1 "Error";
VAL_ 1179 EDS_F_Error_46 0 "No Error" 1 "Error";
VAL_ 1179 EDS_F_Error_47 0 "No Error" 1 "Error";
VAL_ 1179 EDS_F_Error_48 0 "No Error" 1 "Error";
VAL_ 1179 EDS_F_Error_49 0 "No Error" 1 "Error";
VAL_ 1179 EDS_F_Error_50 0 "No Error" 1 "Error";
VAL_ 1179 EDS_F_Error_51 0 "No Error" 1 "Error";
VAL_ 1179 EDS_F_Error_52 0 "No Error" 1 "Error";
VAL_ 1191 RCU_DAA_NoOpDoorOpen 0 "None" 1 "Alert";
VAL_ 1191 RCU_EHandBrk_fault 0 "None" 1 "Alert";
VAL_ 1191 RCU_EOL_NotDone 0 "None" 1 "Alert";
VAL_ 1191 RCU_ECD_RWU_active 0 "None" 1 "Alert";
VAL_ 1191 RCU_ParkOnSteepInclination 0 "None" 1 "Alert";
VAL_ 1191 RCU_BrkForceNotEnough 0 "None" 1 "Alert";
VAL_ 1191 RCU_ReleaseEPB_Wo_PressBrk 0 "None" 1 "Alert";
VAL_ 1191 RCU_ParkBrkApplied 0 "None" 1 "Alert";
VAL_ 1191 RCU_Swch_Mafnc 0 "None" 1 "Alert";
VAL_ 1191 RCU_DAA_NoOpBeltUnbuckled 0 "None" 1 "Alert";
VAL_ 1191 RCU_RollerBenchMode 0 "None" 1 "Alert";
VAL_ 1191 RCU_EPB_ParkLampState 0 "No Indication" 1 "Durable" 2 "Bilinking 1Hz" 3 "Blinking 3Hz";
VAL_ 1191 RCU_EPB_WarnLampState 0 "No Indication" 1 "Durable" 2 "Bilinking 1Hz" 3 "Blinking 3Hz";
VAL_ 1191 RCU_WflagRes36 0 "None" 1 "Alert";
VAL_ 1191 RCU_WflagRes37 0 "None" 1 "Alert";
VAL_ 1191 RCU_WflagRes38 0 "None" 1 "Alert";
VAL_ 1191 RCU_WflagRes39 0 "None" 1 "Alert";
VAL_ 1191 RCU_WflagRes40 0 "None" 1 "Alert";
VAL_ 1191 RCU_WflagRes41 0 "None" 1 "Alert";
VAL_ 1191 RCU_WflagRes42 0 "None" 1 "Alert";
VAL_ 1191 RCU_WflagRes43 0 "None" 1 "Alert";
VAL_ 1191 RCU_WflagRes44 0 "None" 1 "Alert";
VAL_ 1191 RCU_WflagRes45 0 "None" 1 "Alert";
VAL_ 1191 RCU_WflagRes46 0 "None" 1 "Alert";
VAL_ 1191 RCU_WflagRes47 0 "None" 1 "Alert";
VAL_ 1192 EPS_Malfunction 0 "No Error" 1 "Error";
VAL_ 1192 EPS_Reduced 0 "No Error" 1 "Error";
VAL_ 1192 EPS_Overheat 0 "No Error" 1 "Error";
VAL_ 1192 EPS_NotReady 0 "No Error" 1 "Error";
VAL_ 1192 EPS_Warning_Flag_5 0 "No Error" 1 "Error";
VAL_ 1192 EPS_Warning_Flag_6 0 "No Error" 1 "Error";
VAL_ 1192 EPS_Warning_Flag_7 0 "No Error" 1 "Error";
VAL_ 1192 EPS_Warning_Flag_8 0 "No Error" 1 "Error";
VAL_ 1192 EPS_Warning_Flag_9 0 "No Error" 1 "Error";
VAL_ 1192 EPS_Warning_Flag_10 0 "No Error" 1 "Error";
VAL_ 1192 EPS_Warning_Flag_11 0 "No Error" 1 "Error";
VAL_ 1192 EPS_Warning_Flag_12 0 "No Error" 1 "Error";
VAL_ 1193 IDB_ESC_fault 0 "No Error" 1 "Error";
VAL_ 1193 IDB_ABS_fault 0 "No Error" 1 "Error";
VAL_ 1193 IDB_BrkLowFluid 0 "No Error" 1 "Error";
VAL_ 1193 IDB_BrkSysFault 0 "No Error" 1 "Error";
VAL_ 1193 IDB_fault 0 "No Error" 1 "Error";
VAL_ 1193 IDB_HydraulicBrkAssist_Fault 0 "No Error" 1 "Error";
VAL_ 1193 IDB_HAS_Fault 0 "No Error" 1 "Error";
VAL_ 1193 IDB_TSM_Fault 0 "No Error" 1 "Error";
VAL_ 1196 VCU_GearPOnlyAtStationaryAlert 0 "None" 1 "Alert";
VAL_ 1196 VCU_GearP_NotPossibleAlert 0 "None" 1 "Alert";
VAL_ 1196 VCU_PressBrakeToEngageGear 0 "None" 1 "Alert";
VAL_ 1196 VCU_CantChangeGear 0 "None" 1 "Alert";
VAL_ 1196 VCU_GearMalfunction 0 "None" 1 "Alert";
VAL_ 1196 VCU_RangeAlert 0 "None" 1 "Alert";
VAL_ 1196 VCU_HVSystemReduced 0 "None" 1 "Alert";
VAL_ 1196 VCU_FrontEDSReduced 0 "None" 1 "Alert";
VAL_ 1196 VCU_FrontEDS_Malfunc 0 "None" 1 "Alert";
VAL_ 1196 VCU_RearEDSReduced 0 "None" 1 "Alert";
VAL_ 1196 VCU_RearEDS_Malfunc 0 "None" 1 "Alert";
VAL_ 1196 VCU_CoolingSystem_Malfunc 0 "None" 1 "Alert";
VAL_ 1196 VCU_NeutralRequest 0 "None" 1 "Alert";
VAL_ 1196 VCU_SoftShutdown 0 "None" 1 "Alert";
VAL_ 1196 VCU_EmergencyShutdown 0 "None" 1 "Alert";
VAL_ 1196 VCU_ChgPortDoorSys_Malfunc 0 "None" 1 "Alert";
VAL_ 1196 VCU_Gearchange_NotPossible 0 "None" 1 "Alert";
VAL_ 1196 VCU_12v_Warning 0 "None" 1 "Alert";
VAL_ 1196 VCU_WflagRes19 0 "None" 1 "Alert";
VAL_ 1196 VCU_WflagRes20 0 "None" 1 "Alert";
VAL_ 1196 VCU_WflagRes21 0 "None" 1 "Alert";
VAL_ 1196 VCU_WflagRes22 0 "None" 1 "Alert";
VAL_ 1196 VCU_WflagRes23 0 "None" 1 "Alert";
VAL_ 1196 VCU_WflagRes24 0 "None" 1 "Alert";
VAL_ 1196 VCU_WflagRes25 0 "None" 1 "Alert";
VAL_ 1196 VCU_WflagRes26 0 "None" 1 "Alert";
VAL_ 1196 VCU_WflagRes27 0 "None" 1 "Alert";
VAL_ 1196 VCU_SuperFastCharge_longer 0 "None" 1 "Alert";
VAL_ 1198 EASC_Warning_Flag_1 0 "No Error" 1 "Error";
VAL_ 1198 EASC_Warning_Flag_2 0 "No Error" 1 "Error";
VAL_ 1198 EASC_Warning_Flag_3 0 "No Error" 1 "Error";
VAL_ 1198 EASC_Warning_Flag_4 0 "No Error" 1 "Error";
VAL_ 1198 EASC_Warning_Flag_5 0 "No Error" 1 "Error";
VAL_ 1198 EASC_Warning_Flag_6 0 "No Error" 1 "Error";
VAL_ 1198 EASC_Warning_Flag_7 0 "No Error" 1 "Error";
VAL_ 1198 EASC_Warning_Flag_8 0 "No Error" 1 "Error";
VAL_ 1198 EASC_Warning_Flag_9 0 "No Error" 1 "Error";
VAL_ 1198 EASC_Warning_Flag_10 0 "No Error" 1 "Error";
VAL_ 1198 EASC_Warning_Flag_11 0 "No Error" 1 "Error";
VAL_ 1198 EASC_Warning_Flag_12 0 "No Error" 1 "Error";
VAL_ 1199 CPD_Malfunction 0 "No Error" 1 "Error";
VAL_ 1199 CPD_SensorFault 0 "No error" 1 "Temporarily not available" 2 "Permanently not available";
VAL_ 1199 CPD_Warning_Flag_4 0 "No Error" 1 "Error";
VAL_ 1199 CPD_Warning_Flag_5 0 "No Error" 1 "Error";
VAL_ 1199 CPD_Warning_Flag_6 0 "No Error" 1 "Error";
VAL_ 1199 CPD_Warning_Flag_7 0 "No Error" 1 "Error";
VAL_ 1199 CPD_Warning_Flag_8 0 "No Error" 1 "Error";
VAL_ 1199 CPD_Warning_Flag_9 0 "No Error" 1 "Error";
VAL_ 1199 CPD_Warning_Flag_10 0 "No Error" 1 "Error";
VAL_ 1199 CPD_Warning_Flag_11 0 "No Error" 1 "Error";
VAL_ 1199 CPD_Warning_Flag_12 0 "No Error" 1 "Error";
